VERSION ""

NS_ :

BS_:

BU_: Vector__XXX

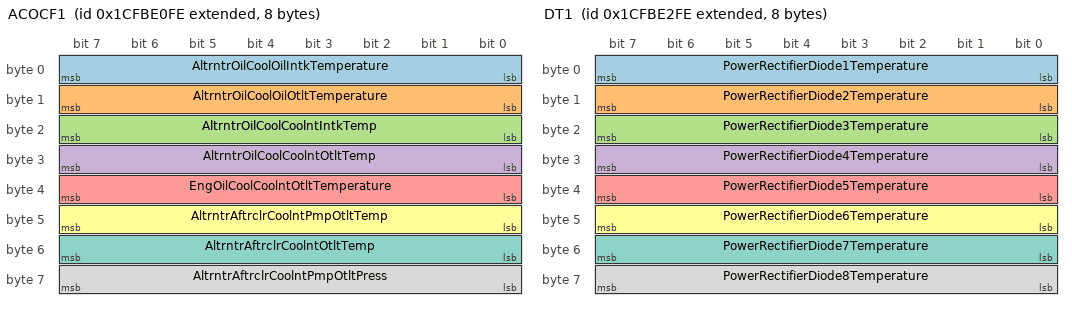
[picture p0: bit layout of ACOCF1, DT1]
BO_ 2633752830 ACOCF1: 8 Vector__XXX
SG_ AltrntrOilCoolOilIntkTemperature : 0|8@1+ (1,-40) [-40|210] "deg C" Vector__XXX
SG_ AltrntrOilCoolOilOtltTemperature : 8|8@1+ (1,-40) [-40|210] "deg C" Vector__XXX
SG_ AltrntrOilCoolCoolntIntkTemp : 16|8@1+ (1,-40) [-40|210] "deg C" Vector__XXX
SG_ AltrntrOilCoolCoolntOtltTemp : 24|8@1+ (1,-40) [-40|210] "deg C" Vector__XXX
SG_ EngOilCoolCoolntOtltTemperature : 32|8@1+ (1,-40) [-40|210] "deg C" Vector__XXX
SG_ AltrntrAftrclrCoolntPmpOtltTemp : 40|8@1+ (1,-40) [-40|210] "deg C" Vector__XXX
SG_ AltrntrAftrclrCoolntOtltTemp : 48|8@1+ (1,-40) [-40|210] "deg C" Vector__XXX
SG_ AltrntrAftrclrCoolntPmpOtltPress : 56|8@1+ (2,0) [0|500] "kPa" Vector__XXX

BO_ 2633753086 DT2: 8 Vector__XXX
SG_ PowerRectifierDiode9Temperature : 0|8@1+ (1,-40) [-40|210] "deg C" Vector__XXX
SG_ PowerRectifierDiode10Temperature : 8|8@1+ (1,-40) [-40|210] "deg C" Vector__XXX
SG_ PowerRectifierDiode11Temperature : 16|8@1+ (1,-40) [-40|210] "deg C" Vector__XXX
SG_ PowerRectifierDiode12Temperature : 24|8@1+ (1,-40) [-40|210] "deg C" Vector__XXX

BO_ 2633753342 DT1: 8 Vector__XXX
SG_ PowerRectifierDiode1Temperature : 0|8@1+ (1,-40) [-40|210] "deg C" Vector__XXX
SG_ PowerRectifierDiode2Temperature : 8|8@1+ (1,-40) [-40|210] "deg C" Vector__XXX
SG_ PowerRectifierDiode3Temperature : 16|8@1+ (1,-40) [-40|210] "deg C" Vector__XXX
SG_ PowerRectifierDiode4Temperature : 24|8@1+ (1,-40) [-40|210] "deg C" Vector__XXX
SG_ PowerRectifierDiode5Temperature : 32|8@1+ (1,-40) [-40|210] "deg C" Vector__XXX
SG_ PowerRectifierDiode6Temperature : 40|8@1+ (1,-40) [-40|210] "deg C" Vector__XXX
SG_ PowerRectifierDiode7Temperature : 48|8@1+ (1,-40) [-40|210] "deg C" Vector__XXX
SG_ PowerRectifierDiode8Temperature : 56|8@1+ (1,-40) [-40|210] "deg C" Vector__XXX

BO_ 2633753598 AT2: 8 Vector__XXX
SG_ EngineAltrntrWinding7Temperature : 0|8@1+ (1,-40) [-40|210] "deg C" Vector__XXX
SG_ EngineAltrntrWinding8Temperature : 8|8@1+ (1,-40) [-40|210] "deg C" Vector__XXX
SG_ EngineAltrntrWinding9Temperature : 16|8@1+ (1,-40) [-40|210] "deg C" Vector__XXX
SG_ EngAltrntrWinding10Temperature : 24|8@1+ (1,-40) [-40|210] "deg C" Vector__XXX
SG_ EngAltrntrWinding11Temperature : 32|8@1+ (1,-40) [-40|210] "deg C" Vector__XXX
SG_ EngAltrntrWinding12Temperature : 40|8@1+ (1,-40) [-40|210] "deg C" Vector__XXX
SG_ AltrntrAirCoolAirIntkTemperature : 48|8@1+ (1,-40) [-40|210] "deg C" Vector__XXX
SG_ AltrntrAirCoolAirOtltTemperature : 56|8@1+ (1,-40) [-40|210] "deg C" Vector__XXX

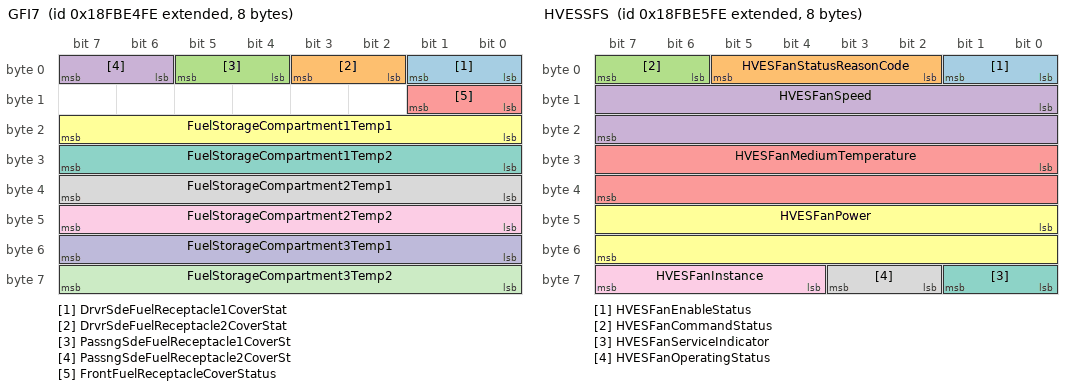
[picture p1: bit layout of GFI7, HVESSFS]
BO_ 2566644990 GFI7: 8 Vector__XXX
SG_ DrvrSdeFuelReceptacle1CoverStat : 0|2@1+ (1,0) [0|3] "" Vector__XXX
SG_ DrvrSdeFuelReceptacle2CoverStat : 2|2@1+ (1,0) [0|3] "" Vector__XXX
SG_ PassngSdeFuelReceptacle1CoverSt : 4|2@1+ (1,0) [0|3] "" Vector__XXX
SG_ PassngSdeFuelReceptacle2CoverSt : 6|2@1+ (1,0) [0|3] "" Vector__XXX
SG_ FrontFuelReceptacleCoverStatus : 8|2@1+ (1,0) [0|3] "" Vector__XXX
SG_ FuelStorageCompartment1Temp1 : 16|8@1+ (1,-40) [-40|210] "deg C" Vector__XXX
SG_ FuelStorageCompartment1Temp2 : 24|8@1+ (1,-40) [-40|210] "deg C" Vector__XXX
SG_ FuelStorageCompartment2Temp1 : 32|8@1+ (1,-40) [-40|210] "deg C" Vector__XXX
SG_ FuelStorageCompartment2Temp2 : 40|8@1+ (1,-40) [-40|210] "deg C" Vector__XXX
SG_ FuelStorageCompartment3Temp1 : 48|8@1+ (1,-40) [-40|210] "deg C" Vector__XXX
SG_ FuelStorageCompartment3Temp2 : 56|8@1+ (1,-40) [-40|210] "deg C" Vector__XXX

BO_ 2566645246 HVESSFS: 8 Vector__XXX
SG_ HVESFanEnableStatus : 0|2@1+ (1,0) [0|3] "" Vector__XXX
SG_ HVESFanStatusReasonCode : 2|4@1+ (1,0) [0|15] "" Vector__XXX
SG_ HVESFanCommandStatus : 6|2@1+ (1,0) [0|3] "" Vector__XXX
SG_ HVESFanSpeed : 8|16@1+ (0.5,0) [0|32127.5] "rpm" Vector__XXX
SG_ HVESFanMediumTemperature : 24|16@1+ (0.03125,-273) [-273|1734.96875] "deg C" Vector__XXX
SG_ HVESFanPower : 40|16@1+ (0.5,0) [0|32127.5] "W" Vector__XXX
SG_ HVESFanServiceIndicator : 56|2@1+ (1,0) [0|3] "" Vector__XXX
SG_ HVESFanOperatingStatus : 58|2@1+ (1,0) [0|3] "" Vector__XXX
SG_ HVESFanInstance : 60|4@1+ (1,0) [0|15] "" Vector__XXX

BO_ 2365318910 HVESSFC: 8 Vector__XXX
SG_ HVESFanEnableCommand : 0|2@1+ (1,0) [0|3] "" Vector__XXX
SG_ HVESFanPowerHold : 2|2@1+ (1,0) [0|3] "" Vector__XXX
SG_ HVESFanSpeedCommand : 8|16@1+ (0.5,0) [0|32127.5] "rpm" Vector__XXX
SG_ HVESFanPercentSpeedCommand : 24|8@1+ (0.4,0) [0|100] "%" Vector__XXX
SG_ HVESFanInstance1 : 32|1@1+ (1,0) [0|1] "" Vector__XXX
SG_ HVESFanInstance2 : 33|1@1+ (1,0) [0|1] "" Vector__XXX
SG_ HVESFanInstance3 : 34|1@1+ (1,0) [0|1] "" Vector__XXX
SG_ HVESFanInstance4 : 35|1@1+ (1,0) [0|1] "" Vector__XXX
SG_ HVESFanInstance5 : 36|1@1+ (1,0) [0|1] "" Vector__XXX
SG_ HVESFanInstance6 : 37|1@1+ (1,0) [0|1] "" Vector__XXX
SG_ HVESFanInstance7 : 38|1@1+ (1,0) [0|1] "" Vector__XXX
SG_ HVESFanInstance8 : 39|1@1+ (1,0) [0|1] "" Vector__XXX
SG_ HVESFanInstance9 : 40|1@1+ (1,0) [0|1] "" Vector__XXX
SG_ HVESFanInstance10 : 41|1@1+ (1,0) [0|1] "" Vector__XXX
SG_ HVESFanInstance11 : 42|1@1+ (1,0) [0|1] "" Vector__XXX
SG_ HVESFanInstance12 : 43|1@1+ (1,0) [0|1] "" Vector__XXX
SG_ HVESFanInstance13 : 44|1@1+ (1,0) [0|1] "" Vector__XXX
SG_ HVESFanInstance14 : 45|1@1+ (1,0) [0|1] "" Vector__XXX
SG_ HVESFanInstance15 : 46|1@1+ (1,0) [0|1] "" Vector__XXX

BO_ 2633754622 SCROII5: 8 Vector__XXX
SG_ Aftrtrtmnt1SCRIntkHghTempTime : 0|32@1+ (1,0) [0|4211081215] "s" Vector__XXX
SG_ SCROprtrIndcEmrgOvrrdTtlActtnTme : 32|32@1+ (1,0) [0|4211081215] "s" Vector__XXX

BO_ 2633754878 ASI2: 8 Vector__XXX
SG_ AftrtrtmntTotalDslExhstFluidUsed : 0|32@1+ (0.5,0) [0|2105540607.5] "l" Vector__XXX
SG_ AftDslExhstFldUsdThisOprtngCycle : 32|16@1+ (0.1,0) [0|6425.5] "l" Vector__XXX
SG_ DEFDosingMode : 48|8@1+ (1,0) [0|250] "" Vector__XXX
SG_ HCDoserDutyCycle : 56|8@1+ (0.4,0) [0|100] "%" Vector__XXX

BO_ 2633755134 E1NET2: 100 Vector__XXX
SG_ HostName : 7|800@0+ (1,0) [0|0] "ASCII" Vector__XXX

BO_ 2633755390 E1NET1: 19 Vector__XXX
SG_ DHCPStatus : 0|4@1+ (1,0) [0|15] "" Vector__XXX
SG_ EthernetLinkStatus : 4|2@1+ (1,0) [0|3] "" Vector__XXX
SG_ IPv4AddressOctet1 : 8|8@1+ (1,0) [0|255] "" Vector__XXX
SG_ IPv4AddressOctet2 : 16|8@1+ (1,0) [0|255] "" Vector__XXX
SG_ IPv4AddressOctet3 : 24|8@1+ (1,0) [0|255] "" Vector__XXX
SG_ IPv4AddressOctet4 : 32|8@1+ (1,0) [0|255] "" Vector__XXX
SG_ SubnetMaskOctet1 : 40|8@1+ (1,0) [0|255] "" Vector__XXX
SG_ SubnetMaskOctet2 : 48|8@1+ (1,0) [0|255] "" Vector__XXX
SG_ SubnetMaskOctet3 : 56|8@1+ (1,0) [0|255] "" Vector__XXX
SG_ SubnetMaskOctet4 : 64|8@1+ (1,0) [0|255] "" Vector__XXX
SG_ DefaultGatewayOctet1 : 72|8@1+ (1,0) [0|255] "" Vector__XXX
SG_ DefaultGatewayOctet2 : 80|8@1+ (1,0) [0|255] "" Vector__XXX
SG_ DefaultGatewayOctet3 : 88|8@1+ (1,0) [0|255] "" Vector__XXX
SG_ DefaultGatewayOctet4 : 96|8@1+ (1,0) [0|255] "" Vector__XXX
SG_ MACAddressOctet1 : 104|8@1+ (1,0) [0|255] "" Vector__XXX
SG_ MACAddressOctet2 : 112|8@1+ (1,0) [0|255] "" Vector__XXX
SG_ MACAddressOctet3 : 120|8@1+ (1,0) [0|255] "" Vector__XXX
SG_ MACAddressOctet4 : 128|8@1+ (1,0) [0|255] "" Vector__XXX
SG_ MACAddressOctet5 : 136|8@1+ (1,0) [0|255] "" Vector__XXX
SG_ MACAddressOctet6 : 144|8@1+ (1,0) [0|255] "" Vector__XXX

BO_ 2566646782 ODMCF1_2: 8 Vector__XXX
SG_ OilDebrisMontFerrsBins12IdNo : 0|8@1+ (1,0) [0|250] "" Vector__XXX
SG_ OilDebrisMonitorFerrousBin1Count : 8|24@1+ (1,0) [0|16449535] "" Vector__XXX
SG_ OilDebrisMonitorFerrousBin2Count : 32|24@1+ (1,0) [0|16449535] "" Vector__XXX

BO_ 2566647038 ODMCF3_4: 8 Vector__XXX
SG_ OilDebrisMontFerrsBins34IdNo : 0|8@1+ (1,0) [0|250] "" Vector__XXX
SG_ OilDebrisMonitorFerrousBin3Count : 8|24@1+ (1,0) [0|16449535] "" Vector__XXX
SG_ OilDebrisMonitorFerrousBin4Count : 32|24@1+ (1,0) [0|16449535] "" Vector__XXX

BO_ 2566647294 ODMCF5_6: 8 Vector__XXX
SG_ OilDebrisMontFerrsBins56IdNo : 0|8@1+ (1,0) [0|250] "" Vector__XXX
SG_ OilDebrisMonitorFerrousBin5Count : 8|24@1+ (1,0) [0|16449535] "" Vector__XXX
SG_ OilDebrisMonitorFerrousBin6Count : 32|24@1+ (1,0) [0|16449535] "" Vector__XXX

BO_ 2566647550 ODMCNF1_2: 8 Vector__XXX
SG_ OilDebrisMontNFerrsBins12IdNo : 0|8@1+ (1,0) [0|250] "" Vector__XXX
SG_ OilDebrisMonitorNonFerrsBin1Cnt : 8|24@1+ (1,0) [0|16449535] "" Vector__XXX
SG_ OilDebrisMonitorNonFerrsBin2Cnt : 32|24@1+ (1,0) [0|16449535] "" Vector__XXX

BO_ 2566647806 ODMCNF3_4: 8 Vector__XXX
SG_ OilDebrisMontNFerrsBins34IdNo : 0|8@1+ (1,0) [0|250] "" Vector__XXX
SG_ OilDebrisMonitorNonFerrsBin3Cnt : 8|24@1+ (1,0) [0|16449535] "" Vector__XXX
SG_ OilDebrisMonitorNonFerrsBin4Cnt : 32|24@1+ (1,0) [0|16449535] "" Vector__XXX

BO_ 2566648062 ODMCNF5_6: 8 Vector__XXX
SG_ OilDebrisMontNFerrsBins56IdNo : 0|8@1+ (1,0) [0|250] "" Vector__XXX
SG_ OilDebrisMonitorNonFerrsBin5Cnt : 8|24@1+ (1,0) [0|16449535] "" Vector__XXX
SG_ OilDebrisMonitorNonFerrsBin6Cnt : 32|24@1+ (1,0) [0|16449535] "" Vector__XXX

BO_ 2566648318 ODMSS: 8 Vector__XXX
SG_ OilDebrisMontStatusIdntfctionNo : 0|8@1+ (1,0) [0|250] "" Vector__XXX
SG_ OilDebrisMontTotalNumberSensors : 8|8@1+ (1,0) [0|250] "" Vector__XXX
SG_ OilDebrisMontEnvironmentStatus : 16|2@1+ (1,0) [0|3] "" Vector__XXX
SG_ OilDebrisMontSensingElementStat : 18|2@1+ (1,0) [0|3] "" Vector__XXX
SG_ OilDebrisMontSigPrcngElctrncsSt : 20|2@1+ (1,0) [0|3] "" Vector__XXX
SG_ OilDebrisMontElctrncsTempStat : 22|2@1+ (1,0) [0|3] "" Vector__XXX

BO_ 2365322238 CCVS5: 8 Vector__XXX
SG_ DirectionalVehicleSpeed : 0|16@1+ (0.0078125,-250) [-250|251.992] "km/h" Vector__XXX

BO_ 2566649086 A2DOC2: 8 Vector__XXX
SG_ Aft2DslOxidtnCtlystIntkPress : 0|16@1+ (0.1,0) [0|6425.5] "kPa" Vector__XXX
SG_ Aft2DslOxidtnCtlystOtltPress : 16|16@1+ (0.1,0) [0|6425.5] "kPa" Vector__XXX
SG_ Aft2DOCInletToDPFOtltDeltaPress : 32|16@1+ (0.1,0) [0|6425.5] "kPa" Vector__XXX

BO_ 2566649342 A1DOC2: 8 Vector__XXX
SG_ Aft1DslOxidtnCtlystIntkPress : 0|16@1+ (0.1,0) [0|6425.5] "kPa" Vector__XXX
SG_ Aft1DslOxidtnCtlystOtltPress : 16|16@1+ (0.1,0) [0|6425.5] "kPa" Vector__XXX
SG_ Aft1DOCInletToDPFOtltDeltaPress : 32|16@1+ (0.1,0) [0|6425.5] "kPa" Vector__XXX

BO_ 2566649598 VP2: 8 Vector__XXX
SG_ TotalNumberOfSatellitesInView : 0|8@1+ (1,0) [0|250] "" Vector__XXX
SG_ HorizontalDilutionOfPrecision : 8|8@1+ (0.1,0) [0|25] "" Vector__XXX
SG_ VerticalDilutionOfPrecision : 16|8@1+ (0.1,0) [0|25] "" Vector__XXX
SG_ PositionDilutionOfPrecision : 24|8@1+ (0.1,0) [0|25] "" Vector__XXX
SG_ TimeDilutionOfPrecision : 32|8@1+ (0.1,0) [0|25] "" Vector__XXX

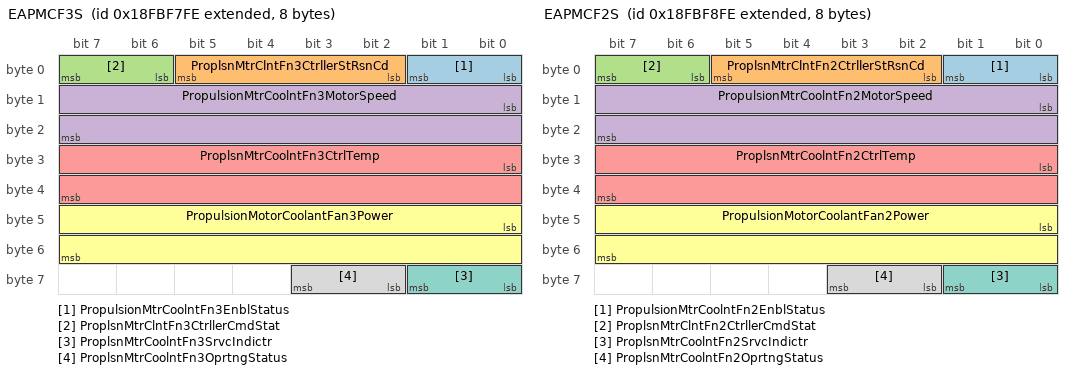
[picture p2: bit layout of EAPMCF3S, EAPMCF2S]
BO_ 2566649854 EAPMCF3S: 8 Vector__XXX
SG_ PropulsionMtrCoolntFn3EnblStatus : 0|2@1+ (1,0) [0|3] "" Vector__XXX
SG_ ProplsnMtrClntFn3CtrllerStRsnCd : 2|4@1+ (1,0) [0|15] "" Vector__XXX
SG_ ProplsnMtrClntFn3CtrllerCmdStat : 6|2@1+ (1,0) [0|3] "" Vector__XXX
SG_ PropulsionMtrCoolntFn3MotorSpeed : 8|16@1+ (0.5,0) [0|32127.5] "rpm" Vector__XXX
SG_ ProplsnMtrCoolntFn3CtrlTemp : 24|16@1+ (0.03125,-273) [-273|1734.96875] "deg C" Vector__XXX
SG_ PropulsionMotorCoolantFan3Power : 40|16@1+ (0.5,0) [0|32127.5] "W" Vector__XXX
SG_ ProplsnMtrCoolntFn3SrvcIndictr : 56|2@1+ (1,0) [0|3] "" Vector__XXX
SG_ ProplsnMtrCoolntFn3OprtngStatus : 58|2@1+ (1,0) [0|3] "" Vector__XXX

BO_ 2566650110 EAPMCF2S: 8 Vector__XXX
SG_ PropulsionMtrCoolntFn2EnblStatus : 0|2@1+ (1,0) [0|3] "" Vector__XXX
SG_ ProplsnMtrClntFn2CtrllerStRsnCd : 2|4@1+ (1,0) [0|15] "" Vector__XXX
SG_ ProplsnMtrClntFn2CtrllerCmdStat : 6|2@1+ (1,0) [0|3] "" Vector__XXX
SG_ PropulsionMtrCoolntFn2MotorSpeed : 8|16@1+ (0.5,0) [0|32127.5] "rpm" Vector__XXX
SG_ ProplsnMtrCoolntFn2CtrlTemp : 24|16@1+ (0.03125,-273) [-273|1734.96875] "deg C" Vector__XXX
SG_ PropulsionMotorCoolantFan2Power : 40|16@1+ (0.5,0) [0|32127.5] "W" Vector__XXX
SG_ ProplsnMtrCoolntFn2SrvcIndictr : 56|2@1+ (1,0) [0|3] "" Vector__XXX
SG_ ProplsnMtrCoolntFn2OprtngStatus : 58|2@1+ (1,0) [0|3] "" Vector__XXX

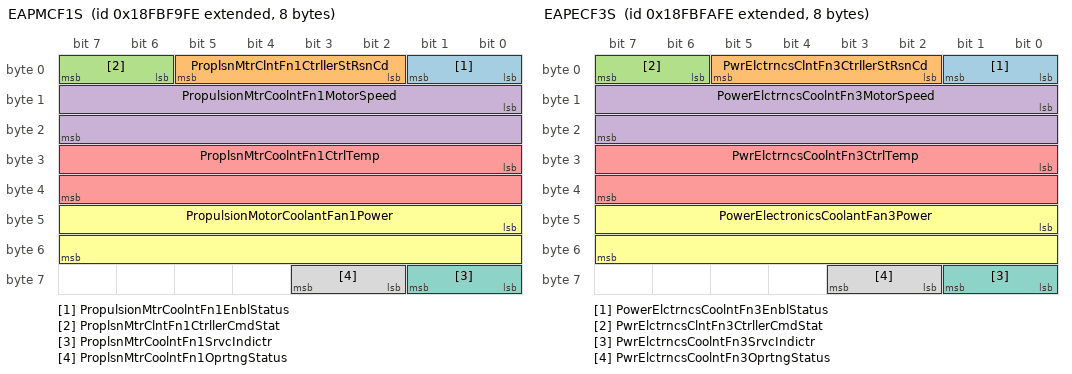
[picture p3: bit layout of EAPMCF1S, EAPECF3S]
BO_ 2566650366 EAPMCF1S: 8 Vector__XXX
SG_ PropulsionMtrCoolntFn1EnblStatus : 0|2@1+ (1,0) [0|3] "" Vector__XXX
SG_ ProplsnMtrClntFn1CtrllerStRsnCd : 2|4@1+ (1,0) [0|15] "" Vector__XXX
SG_ ProplsnMtrClntFn1CtrllerCmdStat : 6|2@1+ (1,0) [0|3] "" Vector__XXX
SG_ PropulsionMtrCoolntFn1MotorSpeed : 8|16@1+ (0.5,0) [0|32127.5] "rpm" Vector__XXX
SG_ ProplsnMtrCoolntFn1CtrlTemp : 24|16@1+ (0.03125,-273) [-273|1734.96875] "deg C" Vector__XXX
SG_ PropulsionMotorCoolantFan1Power : 40|16@1+ (0.5,0) [0|32127.5] "W" Vector__XXX
SG_ ProplsnMtrCoolntFn1SrvcIndictr : 56|2@1+ (1,0) [0|3] "" Vector__XXX
SG_ ProplsnMtrCoolntFn1OprtngStatus : 58|2@1+ (1,0) [0|3] "" Vector__XXX

BO_ 2566650622 EAPECF3S: 8 Vector__XXX
SG_ PowerElctrncsCoolntFn3EnblStatus : 0|2@1+ (1,0) [0|3] "" Vector__XXX
SG_ PwrElctrncsClntFn3CtrllerStRsnCd : 2|4@1+ (1,0) [0|15] "" Vector__XXX
SG_ PwrElctrncsClntFn3CtrllerCmdStat : 6|2@1+ (1,0) [0|3] "" Vector__XXX
SG_ PowerElctrncsCoolntFn3MotorSpeed : 8|16@1+ (0.5,0) [0|32127.5] "rpm" Vector__XXX
SG_ PwrElctrncsCoolntFn3CtrlTemp : 24|16@1+ (0.03125,-273) [-273|1734.96875] "deg C" Vector__XXX
SG_ PowerElectronicsCoolantFan3Power : 40|16@1+ (0.5,0) [0|32127.5] "W" Vector__XXX
SG_ PwrElctrncsCoolntFn3SrvcIndictr : 56|2@1+ (1,0) [0|3] "" Vector__XXX
SG_ PwrElctrncsCoolntFn3OprtngStatus : 58|2@1+ (1,0) [0|3] "" Vector__XXX

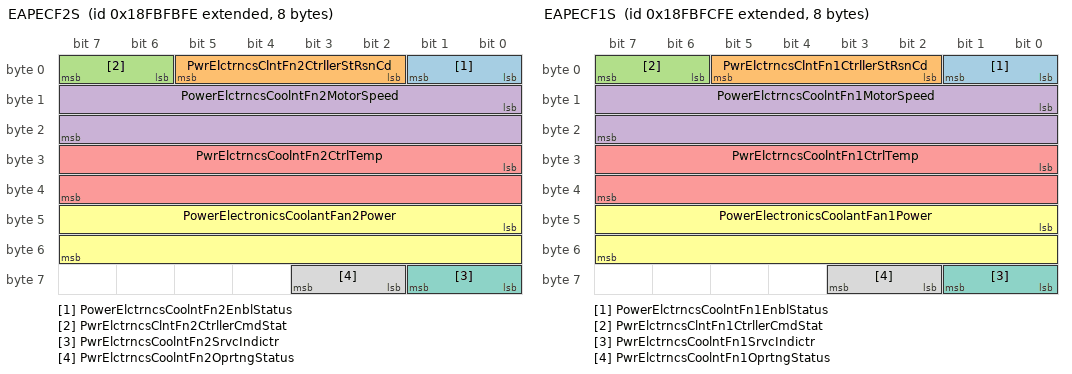
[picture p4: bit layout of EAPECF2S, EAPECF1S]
BO_ 2566650878 EAPECF2S: 8 Vector__XXX
SG_ PowerElctrncsCoolntFn2EnblStatus : 0|2@1+ (1,0) [0|3] "" Vector__XXX
SG_ PwrElctrncsClntFn2CtrllerStRsnCd : 2|4@1+ (1,0) [0|15] "" Vector__XXX
SG_ PwrElctrncsClntFn2CtrllerCmdStat : 6|2@1+ (1,0) [0|3] "" Vector__XXX
SG_ PowerElctrncsCoolntFn2MotorSpeed : 8|16@1+ (0.5,0) [0|32127.5] "rpm" Vector__XXX
SG_ PwrElctrncsCoolntFn2CtrlTemp : 24|16@1+ (0.03125,-273) [-273|1734.96875] "deg C" Vector__XXX
SG_ PowerElectronicsCoolantFan2Power : 40|16@1+ (0.5,0) [0|32127.5] "W" Vector__XXX
SG_ PwrElctrncsCoolntFn2SrvcIndictr : 56|2@1+ (1,0) [0|3] "" Vector__XXX
SG_ PwrElctrncsCoolntFn2OprtngStatus : 58|2@1+ (1,0) [0|3] "" Vector__XXX

BO_ 2566651134 EAPECF1S: 8 Vector__XXX
SG_ PowerElctrncsCoolntFn1EnblStatus : 0|2@1+ (1,0) [0|3] "" Vector__XXX
SG_ PwrElctrncsClntFn1CtrllerStRsnCd : 2|4@1+ (1,0) [0|15] "" Vector__XXX
SG_ PwrElctrncsClntFn1CtrllerCmdStat : 6|2@1+ (1,0) [0|3] "" Vector__XXX
SG_ PowerElctrncsCoolntFn1MotorSpeed : 8|16@1+ (0.5,0) [0|32127.5] "rpm" Vector__XXX
SG_ PwrElctrncsCoolntFn1CtrlTemp : 24|16@1+ (0.03125,-273) [-273|1734.96875] "deg C" Vector__XXX
SG_ PowerElectronicsCoolantFan1Power : 40|16@1+ (0.5,0) [0|32127.5] "W" Vector__XXX
SG_ PwrElctrncsCoolntFn1SrvcIndictr : 56|2@1+ (1,0) [0|3] "" Vector__XXX
SG_ PwrElctrncsCoolntFn1OprtngStatus : 58|2@1+ (1,0) [0|3] "" Vector__XXX

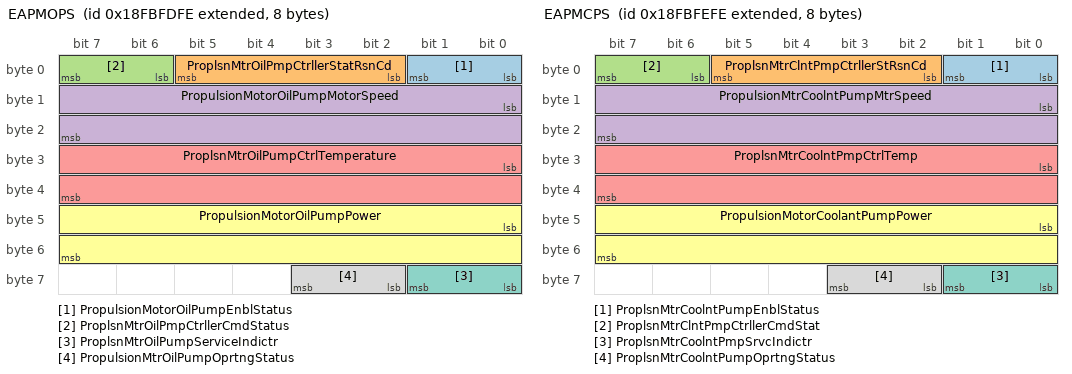
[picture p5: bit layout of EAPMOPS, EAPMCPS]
BO_ 2566651390 EAPMOPS: 8 Vector__XXX
SG_ PropulsionMotorOilPumpEnblStatus : 0|2@1+ (1,0) [0|3] "" Vector__XXX
SG_ ProplsnMtrOilPmpCtrllerStatRsnCd : 2|4@1+ (1,0) [0|15] "" Vector__XXX
SG_ ProplsnMtrOilPmpCtrllerCmdStatus : 6|2@1+ (1,0) [0|3] "" Vector__XXX
SG_ PropulsionMotorOilPumpMotorSpeed : 8|16@1+ (0.5,0) [0|32127.5] "rpm" Vector__XXX
SG_ ProplsnMtrOilPumpCtrlTemperature : 24|16@1+ (0.03125,-273) [-273|1734.96875] "deg C" Vector__XXX
SG_ PropulsionMotorOilPumpPower : 40|16@1+ (0.5,0) [0|32127.5] "W" Vector__XXX
SG_ ProplsnMtrOilPumpServiceIndictr : 56|2@1+ (1,0) [0|3] "" Vector__XXX
SG_ PropulsionMtrOilPumpOprtngStatus : 58|2@1+ (1,0) [0|3] "" Vector__XXX

BO_ 2566651646 EAPMCPS: 8 Vector__XXX
SG_ ProplsnMtrCoolntPumpEnblStatus : 0|2@1+ (1,0) [0|3] "" Vector__XXX
SG_ ProplsnMtrClntPmpCtrllerStRsnCd : 2|4@1+ (1,0) [0|15] "" Vector__XXX
SG_ ProplsnMtrClntPmpCtrllerCmdStat : 6|2@1+ (1,0) [0|3] "" Vector__XXX
SG_ PropulsionMtrCoolntPumpMtrSpeed : 8|16@1+ (0.5,0) [0|32127.5] "rpm" Vector__XXX
SG_ ProplsnMtrCoolntPmpCtrlTemp : 24|16@1+ (0.03125,-273) [-273|1734.96875] "deg C" Vector__XXX
SG_ PropulsionMotorCoolantPumpPower : 40|16@1+ (0.5,0) [0|32127.5] "W" Vector__XXX
SG_ ProplsnMtrCoolntPmpSrvcIndictr : 56|2@1+ (1,0) [0|3] "" Vector__XXX
SG_ ProplsnMtrCoolntPumpOprtngStatus : 58|2@1+ (1,0) [0|3] "" Vector__XXX

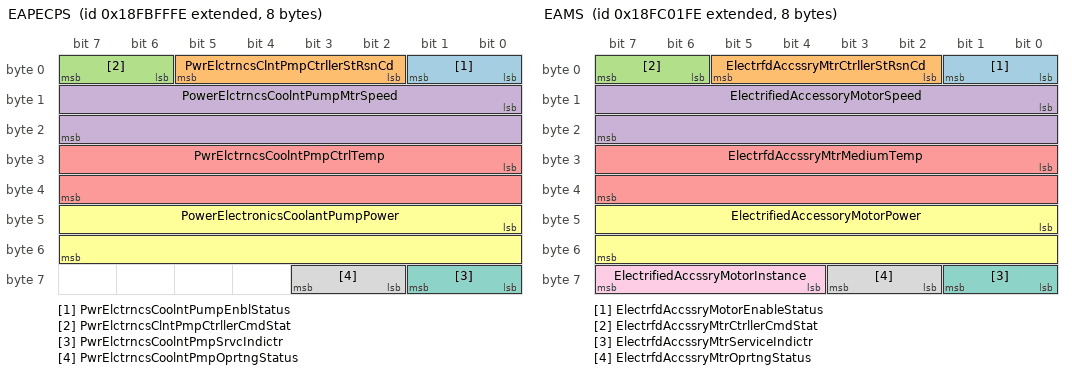
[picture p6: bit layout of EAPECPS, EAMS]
BO_ 2566651902 EAPECPS: 8 Vector__XXX
SG_ PwrElctrncsCoolntPumpEnblStatus : 0|2@1+ (1,0) [0|3] "" Vector__XXX
SG_ PwrElctrncsClntPmpCtrllerStRsnCd : 2|4@1+ (1,0) [0|15] "" Vector__XXX
SG_ PwrElctrncsClntPmpCtrllerCmdStat : 6|2@1+ (1,0) [0|3] "" Vector__XXX
SG_ PowerElctrncsCoolntPumpMtrSpeed : 8|16@1+ (0.5,0) [0|32127.5] "rpm" Vector__XXX
SG_ PwrElctrncsCoolntPmpCtrlTemp : 24|16@1+ (0.03125,-273) [-273|1734.96875] "deg C" Vector__XXX
SG_ PowerElectronicsCoolantPumpPower : 40|16@1+ (0.5,0) [0|32127.5] "W" Vector__XXX
SG_ PwrElctrncsCoolntPmpSrvcIndictr : 56|2@1+ (1,0) [0|3] "" Vector__XXX
SG_ PwrElctrncsCoolntPmpOprtngStatus : 58|2@1+ (1,0) [0|3] "" Vector__XXX

BO_ 2566652414 EAMS: 8 Vector__XXX
SG_ ElectrfdAccssryMotorEnableStatus : 0|2@1+ (1,0) [0|3] "" Vector__XXX
SG_ ElectrfdAccssryMtrCtrllerStRsnCd : 2|4@1+ (1,0) [0|15] "" Vector__XXX
SG_ ElectrfdAccssryMtrCtrllerCmdStat : 6|2@1+ (1,0) [0|3] "" Vector__XXX
SG_ ElectrifiedAccessoryMotorSpeed : 8|16@1+ (0.5,0) [0|32127.5] "rpm" Vector__XXX
SG_ ElectrfdAccssryMtrMediumTemp : 24|16@1+ (0.03125,-273) [-273|1734.96875] "deg C" Vector__XXX
SG_ ElectrifiedAccessoryMotorPower : 40|16@1+ (0.5,0) [0|32127.5] "W" Vector__XXX
SG_ ElectrfdAccssryMtrServiceIndictr : 56|2@1+ (1,0) [0|3] "" Vector__XXX
SG_ ElectrfdAccssryMtrOprtngStatus : 58|2@1+ (1,0) [0|3] "" Vector__XXX
SG_ ElectrifiedAccssryMotorInstance : 60|4@1+ (1,0) [0|15] "" Vector__XXX

BO_ 2566652670 SCRSI: 8 Vector__XXX
SG_ DieselExhaustFluidFrozenTime : 0|32@1+ (1,0) [0|4211081215] "s" Vector__XXX
SG_ Aftrtrtmnt1SCRSystemHydrocarbon : 32|8@1+ (1,0) [0|250] "%" Vector__XXX
SG_ Aft1DslExhstFldDsngSysFrozen : 40|2@1+ (1,0) [0|3] "" Vector__XXX
SG_ Aft2DslExhstFldDsngSysFrozen : 42|2@1+ (1,0) [0|3] "" Vector__XXX
SG_ Afttreatment2SCRSysHydrocarbon : 48|8@1+ (1,0) [0|250] "%" Vector__XXX

BO_ 2566652926 VEP14: 8 Vector__XXX
SG_ SLIBattryPack1Battry4StateCharge : 0|16@1+ (0.0025,0) [0|160.6375] "%" Vector__XXX
SG_ SLIBatteryPack1Battery4Capacity : 16|16@1+ (1,0) [0|64255] "Ah" Vector__XXX
SG_ SLIBatteryPack1Battery4Health : 32|8@1+ (0.5,0) [0|125] "%" Vector__XXX
SG_ SLIBattPack1Batt4PrdctMnCrnkVltg : 40|8@1+ (0.2,0) [0|50] "V" Vector__XXX
SG_ SLIBattryPack1Sensor4InitStatus : 48|4@1+ (1,0) [0|15] "" Vector__XXX

BO_ 2566653182 VEP13: 8 Vector__XXX
SG_ SLIBattryPack1Battery4NetCurrent : 0|16@1+ (0.05,-1600) [-1600|1612.75] "A" Vector__XXX
SG_ SLIBattryPack1Battry4Temperature : 16|8@1+ (1,-40) [-40|210] "deg C" Vector__XXX
SG_ SLIBatteryPack1Battery4Voltage : 24|16@1+ (0.05,0) [0|3212.75] "V" Vector__XXX

BO_ 2566653438 VEP12: 8 Vector__XXX
SG_ SLIBattryPack1Battry3StateCharge : 0|16@1+ (0.0025,0) [0|160.6375] "%" Vector__XXX
SG_ SLIBatteryPack1Battery3Capacity : 16|16@1+ (1,0) [0|64255] "Ah" Vector__XXX
SG_ SLIBatteryPack1Battery3Health : 32|8@1+ (0.5,0) [0|125] "%" Vector__XXX
SG_ SLIBattPack1Batt3PrdctMnCrnkVltg : 40|8@1+ (0.2,0) [0|50] "V" Vector__XXX
SG_ SLIBattryPack1Sensor3InitStatus : 48|4@1+ (1,0) [0|15] "" Vector__XXX

BO_ 2566653694 VEP11: 8 Vector__XXX
SG_ SLIBattryPack1Battery3NetCurrent : 0|16@1+ (0.05,-1600) [-1600|1612.75] "A" Vector__XXX
SG_ SLIBattryPack1Battry3Temperature : 16|8@1+ (1,-40) [-40|210] "deg C" Vector__XXX
SG_ SLIBatteryPack1Battery3Voltage : 24|16@1+ (0.05,0) [0|3212.75] "V" Vector__XXX

BO_ 2566653950 VEP10: 8 Vector__XXX
SG_ SLIBattryPack1Battry2StateCharge : 0|16@1+ (0.0025,0) [0|160.6375] "%" Vector__XXX
SG_ SLIBatteryPack1Battery2Capacity : 16|16@1+ (1,0) [0|64255] "Ah" Vector__XXX
SG_ SLIBatteryPack1Battery2Health : 32|8@1+ (0.5,0) [0|125] "%" Vector__XXX
SG_ SLIBattPack1Batt2PrdctMnCrnkVltg : 40|8@1+ (0.2,0) [0|50] "V" Vector__XXX
SG_ SLIBattryPack1Sensor2InitStatus : 48|4@1+ (1,0) [0|15] "" Vector__XXX

BO_ 2566654206 VEP9: 8 Vector__XXX
SG_ SLIBattryPack1Battery2NetCurrent : 0|16@1+ (0.05,-1600) [-1600|1612.75] "A" Vector__XXX
SG_ SLIBattryPack1Battry2Temperature : 16|8@1+ (1,-40) [-40|210] "deg C" Vector__XXX
SG_ SLIBatteryPack1Battery2Voltage : 24|16@1+ (0.05,0) [0|3212.75] "V" Vector__XXX

BO_ 2566654462 VEP8: 8 Vector__XXX
SG_ SLIBattryPack1Battry1StateCharge : 0|16@1+ (0.0025,0) [0|160.6375] "%" Vector__XXX
SG_ SLIBatteryPack1Battery1Capacity : 16|16@1+ (1,0) [0|64255] "Ah" Vector__XXX
SG_ SLIBatteryPack1Battery1Health : 32|8@1+ (0.5,0) [0|125] "%" Vector__XXX
SG_ SLIBattPack1Batt1PrdctMnCrnkVltg : 40|8@1+ (0.2,0) [0|50] "V" Vector__XXX
SG_ SLIBattryPack1Sensor1InitStatus : 48|4@1+ (1,0) [0|15] "" Vector__XXX

BO_ 2566654718 VEP7: 8 Vector__XXX
SG_ SLIBattryPack1Battery1NetCurrent : 0|16@1+ (0.05,-1600) [-1600|1612.75] "A" Vector__XXX
SG_ SLIBattryPack1Battry1Temperature : 16|8@1+ (1,-40) [-40|210] "deg C" Vector__XXX
SG_ SLIBatteryPack1Battery1Voltage : 24|16@1+ (0.05,0) [0|3212.75] "V" Vector__XXX

BO_ 2566654974 EEC20: 8 Vector__XXX
SG_ EstEngParasiticLossesPrcntTorque : 0|16@1+ (0.0015625,0) [0|100.3984375] "%" Vector__XXX
SG_ ActlMaximumAvailEngPercentFuel : 16|8@1+ (0.4,0) [0|100] "%" Vector__XXX

BO_ 2633764094 EVAP: 8 Vector__XXX
SG_ CanisterVentValve : 0|2@1+ (1,0) [0|3] "" Vector__XXX
SG_ CanisterPurgeValveCommand : 8|8@1+ (0.4,0) [0|100] "%" Vector__XXX
SG_ GasolineFuelTankPressure : 16|16@1+ (0.1,-3212.7) [-3212.7|3212.8] "kPa" Vector__XXX

BO_ 2633764350 FPS1: 8 Vector__XXX
SG_ FirePumpOperationTime : 0|32@1+ (1,0) [0|4211081215] "s" Vector__XXX
SG_ FirePumpEngagementCycles : 32|16@1+ (1,0) [0|64255] "" Vector__XXX

BO_ 2566655742 PHRPS: 8 Vector__XXX
SG_ RearHitchRollSensitivity : 0|8@1+ (0.4,0) [0|100] "%" Vector__XXX
SG_ RearHitchPitchSensitivity : 8|8@1+ (0.4,0) [0|100] "%" Vector__XXX

BO_ 2566655998 SHRPS: 8 Vector__XXX
SG_ FrontHitchRollSensitivity : 0|8@1+ (0.4,0) [0|100] "%" Vector__XXX
SG_ FrontHitchPitchSensitivity : 8|8@1+ (0.4,0) [0|100] "%" Vector__XXX

BO_ 2566656254 AMB3: 8 Vector__XXX
SG_ BarometricAbsolutePressure2 : 0|16@1+ (0.1,0) [0|6425.5] "kPa" Vector__XXX
SG_ EngineIntake2AirTemperature : 16|8@1+ (1,-40) [-40|210] "deg C" Vector__XXX
SG_ EngPwrDerateRelHumidityDiffrnc : 24|16@1+ (0.01,-321.27) [-321.27|321.28] "%" Vector__XXX

BO_ 2566656510 TGFI: 8 Vector__XXX
SG_ EngineTotalGaseousFuelVolumeUsed : 0|32@1+ (0.5,0) [0|2105540607.5] "m^3" Vector__XXX
SG_ EngTotalGasIdleFuelVolumeUsed : 32|32@1+ (0.5,0) [0|2105540607.5] "m^3" Vector__XXX

BO_ 2499547902 CDC: 8 Vector__XXX
SG_ CabDoorsLockActuationCommand : 0|3@1+ (1,0) [0|7] "" Vector__XXX
SG_ RemoteCabDoorLockRequest : 8|3@1+ (1,0) [0|7] "" Vector__XXX
SG_ LeftFrontWindowPositionCommand : 16|3@1+ (1,0) [0|7] "" Vector__XXX
SG_ RightFrontWindowPositionCommand : 19|3@1+ (1,0) [0|7] "" Vector__XXX
SG_ MirrorFoldingSwitch : 22|2@1+ (1,0) [0|3] "" Vector__XXX
SG_ LeftRearWindowPositionCommand : 24|3@1+ (1,0) [0|7] "" Vector__XXX
SG_ RightRearWindowPositionCommand : 27|3@1+ (1,0) [0|7] "" Vector__XXX
SG_ MirrorAutoPanningEnable : 30|2@1+ (1,0) [0|3] "" Vector__XXX
SG_ MirrorLeft1HorizontalCommand : 32|2@1+ (1,0) [0|3] "" Vector__XXX
SG_ MirrorLeft1VerticalCommand : 34|2@1+ (1,0) [0|3] "" Vector__XXX
SG_ MirrorRight1HorizontalCommand : 36|2@1+ (1,0) [0|3] "" Vector__XXX
SG_ MirrorRight1VerticalCommand : 38|2@1+ (1,0) [0|3] "" Vector__XXX
SG_ MirrorLeft2HorizontalCommand : 40|2@1+ (1,0) [0|3] "" Vector__XXX
SG_ MirrorLeft2VerticalCommand : 42|2@1+ (1,0) [0|3] "" Vector__XXX
SG_ MirrorRight2HorizontalCommand : 44|2@1+ (1,0) [0|3] "" Vector__XXX
SG_ MirrorRight2VerticalCommand : 46|2@1+ (1,0) [0|3] "" Vector__XXX
SG_ MirrorLeft1HeatCommand : 48|2@1+ (1,0) [0|3] "" Vector__XXX
SG_ MirrorRight1HeatCommand : 50|2@1+ (1,0) [0|3] "" Vector__XXX
SG_ MirrorLeft2HeatCommand : 52|2@1+ (1,0) [0|3] "" Vector__XXX
SG_ MirrorRight2HeatCommand : 54|2@1+ (1,0) [0|3] "" Vector__XXX

BO_ 2499548158 DLS: 8 Vector__XXX
SG_ LeftFrontCabDoorLatchPosition : 0|3@1+ (1,0) [0|7] "" Vector__XXX
SG_ RightFrontCabDoorLatchPosition : 8|3@1+ (1,0) [0|7] "" Vector__XXX
SG_ LeftRearCabDoorLatchPosition : 16|3@1+ (1,0) [0|7] "" Vector__XXX
SG_ RightRearCabDoorLatchPosition : 24|3@1+ (1,0) [0|7] "" Vector__XXX

BO_ 2499548670 VEP6: 8 Vector__XXX
SG_ BatteryPotentialPowerInput3 : 0|16@1+ (0.05,0) [0|3212.75] "V" Vector__XXX
SG_ BatteryPotentialPowerInput4 : 16|16@1+ (0.05,0) [0|3212.75] "V" Vector__XXX
SG_ SLIBattery3NetCurrent : 32|16@1+ (0.05,-1600) [-1600|1612.75] "A" Vector__XXX
SG_ SLIBattery4NetCurrent : 48|16@1+ (0.05,-1600) [-1600|1612.75] "A" Vector__XXX

BO_ 2499548926 PLT2: 8 Vector__XXX
SG_ PayloadTemperature5 : 0|16@1+ (0.03125,-273) [-273|1734.96875] "deg C" Vector__XXX

BO_ 2499549182 PLT1: 8 Vector__XXX
SG_ PayloadTemperature1 : 0|16@1+ (0.03125,-273) [-273|1734.96875] "deg C" Vector__XXX
SG_ PayloadTemperature2 : 16|16@1+ (0.03125,-273) [-273|1734.96875] "deg C" Vector__XXX
SG_ PayloadTemperature3 : 32|16@1+ (0.03125,-273) [-273|1734.96875] "deg C" Vector__XXX
SG_ PayloadTemperature4 : 48|16@1+ (0.03125,-273) [-273|1734.96875] "deg C" Vector__XXX

BO_ 2566658302 PLST2: 8 Vector__XXX
SG_ TotalPayloadTransactionCount : 0|32@1+ (1,0) [0|4211081215] "" Vector__XXX

BO_ 2566658558 PLST1: 8 Vector__XXX
SG_ TotalDeliveredPayloadWeight : 0|32@1+ (100,0) [0|421108121500] "kg" Vector__XXX
SG_ TotalHaulCycleCount : 32|32@1+ (1,0) [0|4211081215] "" Vector__XXX

BO_ 2633769726 EEC19: 8 Vector__XXX
SG_ TotalEngineEnergy : 0|32@1+ (1,0) [0|4211081215] "kWh" Vector__XXX
SG_ EngineExhaustFlowRate : 32|32@1+ (0.001,0) [0|4211081.215] "kg/h" Vector__XXX

BO_ 2566661118 LFC2: 8 Vector__XXX
SG_ EngineTotalDieselFuelDemand : 0|32@1+ (0.5,0) [0|2105540607.5] "l" Vector__XXX

BO_ 2566661374 AT2T1I2: 8 Vector__XXX
SG_ Aftrtrtmnt2DslExhstFldTnkVolume2 : 0|8@1+ (0.4,0) [0|100] "%" Vector__XXX
SG_ Aftrtrtmnt2DslExhstFldTnkTemp2 : 8|8@1+ (1,-40) [-40|210] "deg C" Vector__XXX
SG_ Aftrtrtmnt2DslExhstFldTankHtr2 : 16|8@1+ (0.4,0) [0|100] "%" Vector__XXX

BO_ 2566661630 AT1T1I2: 8 Vector__XXX
SG_ Aftrtrtmnt1DslExhstFldTnkVolume2 : 0|8@1+ (0.4,0) [0|100] "%" Vector__XXX
SG_ Aftrtrtmnt1DslExhstFldTnkTemp2 : 8|8@1+ (1,-40) [-40|210] "deg C" Vector__XXX
SG_ Aftrtrtmnt1DslExhstFldTankHtr2 : 16|8@1+ (0.4,0) [0|100] "%" Vector__XXX

BO_ 2566661886 A2DEFI2: 8 Vector__XXX
SG_ Aft2DslExhstFldCtrllerTemp : 0|8@1+ (1,-40) [-40|210] "deg C" Vector__XXX
SG_ Aft2DslExhstFldCtrller2Temp : 8|8@1+ (1,-40) [-40|210] "deg C" Vector__XXX

BO_ 2566662142 A1DEFI2: 8 Vector__XXX
SG_ Aft1DslExhstFldCtrller1Temp : 0|8@1+ (1,-40) [-40|210] "deg C" Vector__XXX
SG_ Aft1DslExhstFldCtrller2Temp : 8|8@1+ (1,-40) [-40|210] "deg C" Vector__XXX

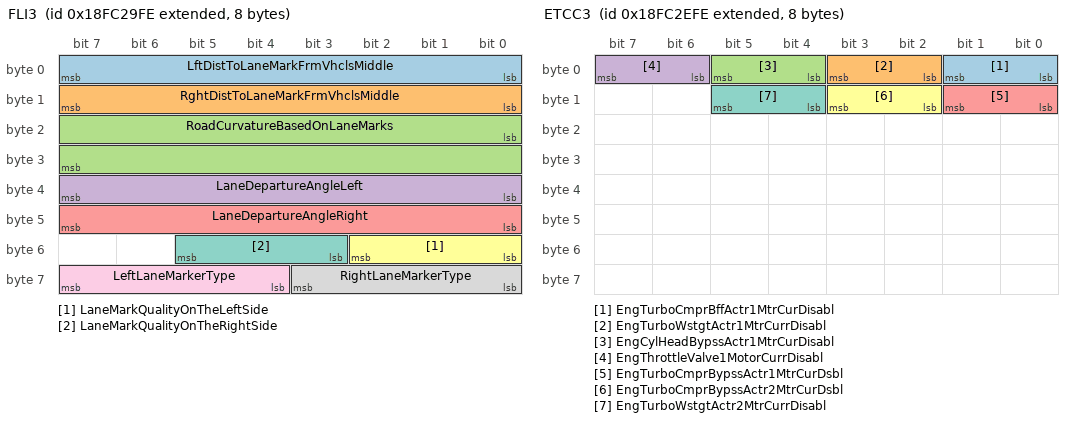
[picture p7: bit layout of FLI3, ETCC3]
BO_ 2566662654 FLI3: 8 Vector__XXX
SG_ LftDistToLaneMarkFrmVhclsMiddle : 0|8@1+ (0.02,0) [0|5] "m" Vector__XXX
SG_ RghtDistToLaneMarkFrmVhclsMiddle : 8|8@1+ (0.02,0) [0|5] "m" Vector__XXX
SG_ RoadCurvatureBasedOnLaneMarks : 16|16@1+ (0.0078125,-250) [-250|251.992] "1/km" Vector__XXX
SG_ LaneDepartureAngleLeft : 32|8@1+ (0.1,-12.5) [-12.5|12.5] "deg" Vector__XXX
SG_ LaneDepartureAngleRight : 40|8@1+ (0.1,-12.5) [-12.5|12.5] "deg" Vector__XXX
SG_ LaneMarkQualityOnTheLeftSide : 48|3@1+ (1,0) [0|7] "" Vector__XXX
SG_ LaneMarkQualityOnTheRightSide : 51|3@1+ (1,0) [0|7] "" Vector__XXX
SG_ RightLaneMarkerType : 56|4@1+ (1,0) [0|15] "" Vector__XXX
SG_ LeftLaneMarkerType : 60|4@1+ (1,0) [0|15] "" Vector__XXX

BO_ 2566662910 OII: 8 Vector__XXX
SG_ OperatorIndcmntTorqueDerateLvl1 : 0|8@1+ (1,0) [0|250] "%" Vector__XXX
SG_ OprtrIndcmntTmeToTrqDerateLvl1 : 8|16@1+ (1,0) [0|64255] "min" Vector__XXX
SG_ OperatorIndcmntTorqueDerateLvl2 : 24|8@1+ (1,0) [0|250] "%" Vector__XXX
SG_ OprtrIndcmntTmeToTrqDerateLvl2 : 32|16@1+ (1,0) [0|64255] "min" Vector__XXX
SG_ OprtrIndcmntTmeToFinalIndcmntAct : 48|16@1+ (1,0) [0|64255] "min" Vector__XXX

BO_ 2566663166 CCVS4: 8 Vector__XXX
SG_ AppliedVehicleSpeedLimit : 0|16@1+ (0.00390625,0) [0|250.996] "km/h" Vector__XXX
SG_ CruiseCtrlAdjustedMaximumSpeed : 16|16@1+ (0.00390625,0) [0|250.996] "km/h" Vector__XXX
SG_ EngExternalIdleRequestFeedback : 32|2@1+ (1,0) [0|3] "" Vector__XXX
SG_ SrcAddrCtrllingDevSttngCrsCtrl : 40|8@1+ (1,0) [0|255] "" Vector__XXX

BO_ 2566663422 BCLC: 8 Vector__XXX
SG_ TractorBrkCaliperLnngClrAxl1Lft : 0|2@1+ (1,0) [0|3] "" Vector__XXX
SG_ TractorBrkCaliperLnngClrAxl1Rght : 2|2@1+ (1,0) [0|3] "" Vector__XXX
SG_ TractorBrkCaliperLnngClrAxl2Lft : 4|2@1+ (1,0) [0|3] "" Vector__XXX
SG_ TractorBrkCaliperLnngClrAxl2Rght : 6|2@1+ (1,0) [0|3] "" Vector__XXX
SG_ TractorBrkCaliperLnngClrAxl3Lft : 8|2@1+ (1,0) [0|3] "" Vector__XXX
SG_ TractorBrkCaliperLnngClrAxl3Rght : 10|2@1+ (1,0) [0|3] "" Vector__XXX
SG_ TractorBrkCaliperLnngClrAxl4Lft : 12|2@1+ (1,0) [0|3] "" Vector__XXX
SG_ TractorBrkCaliperLnngClrAxl4Rght : 14|2@1+ (1,0) [0|3] "" Vector__XXX
SG_ TractorBrkCaliperLnngClrAxl5Lft : 16|2@1+ (1,0) [0|3] "" Vector__XXX
SG_ TractorBrkCaliperLnngClrAxl5Rght : 18|2@1+ (1,0) [0|3] "" Vector__XXX
SG_ TrlrBrkCaliperLnngClearAxl1Lft : 20|2@1+ (1,0) [0|3] "" Vector__XXX
SG_ TrlrBrkCaliperLnngClearAxl1Rght : 22|2@1+ (1,0) [0|3] "" Vector__XXX
SG_ TrlrBrkCaliperLnngClearAxl2Lft : 24|2@1+ (1,0) [0|3] "" Vector__XXX
SG_ TrlrBrkCaliperLnngClearAxl2Rght : 26|2@1+ (1,0) [0|3] "" Vector__XXX
SG_ TrlrBrkCaliperLnngClearAxl3Lft : 28|2@1+ (1,0) [0|3] "" Vector__XXX
SG_ TrlrBrkCaliperLnngClearAxl3Rght : 30|2@1+ (1,0) [0|3] "" Vector__XXX
SG_ TrlrBrkCaliperLnngClearAxl4Lft : 32|2@1+ (1,0) [0|3] "" Vector__XXX
SG_ TrlrBrkCaliperLnngClearAxl4Rght : 34|2@1+ (1,0) [0|3] "" Vector__XXX
SG_ TrlrBrkCaliperLnngClearAxl5Lft : 36|2@1+ (1,0) [0|3] "" Vector__XXX
SG_ TrlrBrkCaliperLnngClearAxl5Rght : 38|2@1+ (1,0) [0|3] "" Vector__XXX

BO_ 2566663678 AF5: 8 Vector__XXX
SG_ LNGTank1VaporPressure : 0|16@1+ (0.1,0) [0|6425.5] "kPa" Vector__XXX
SG_ LNGTank2VaporPressure : 16|16@1+ (0.1,0) [0|6425.5] "kPa" Vector__XXX
SG_ EngFuel2InjectrMeterngRail1Temp2 : 32|8@1+ (1,-40) [-40|210] "deg C" Vector__XXX

BO_ 2566663934 ETCC3: 8 Vector__XXX
SG_ EngTurboCmprBffActr1MtrCurDisabl : 0|2@1+ (1,0) [0|3] "" Vector__XXX
SG_ EngTurboWstgtActr1MtrCurrDisabl : 2|2@1+ (1,0) [0|3] "" Vector__XXX
SG_ EngCylHeadBypssActr1MtrCurDisabl : 4|2@1+ (1,0) [0|3] "" Vector__XXX
SG_ EngThrottleValve1MotorCurrDisabl : 6|2@1+ (1,0) [0|3] "" Vector__XXX
SG_ EngTurboCmprBypssActr1MtrCurDsbl : 8|2@1+ (1,0) [0|3] "" Vector__XXX
SG_ EngTurboCmprBypssActr2MtrCurDsbl : 10|2@1+ (1,0) [0|3] "" Vector__XXX
SG_ EngTurboWstgtActr2MtrCurrDisabl : 12|2@1+ (1,0) [0|3] "" Vector__XXX

BO_ 2633773054 FSAS: 8 Vector__XXX
SG_ FireSuppressionWaterTankLevel : 0|8@1+ (0.4,0) [0|100] "%" Vector__XXX
SG_ FireSuppressionClassAFoamTankLvl : 8|8@1+ (0.4,0) [0|100] "%" Vector__XXX
SG_ FireSuppressionClassBFoamTankLvl : 16|8@1+ (0.4,0) [0|100] "%" Vector__XXX
SG_ FireSupprssnCmpdAirFoamSysAirPrs : 24|8@1+ (8,0) [0|2000] "kPa" Vector__XXX

BO_ 2633773310 SCROII4: 8 Vector__XXX
SG_ SCROprtrIndcEmrgOvrrdTtlRstOccur : 0|16@1+ (1,0) [0|64255] "" Vector__XXX
SG_ SCROperatorIndcmntOverrideMode : 16|3@1+ (1,0) [0|7] "" Vector__XXX
SG_ SCROprtrIndcOvrrdRenewalRequired : 19|2@1+ (1,0) [0|3] "" Vector__XXX
SG_ SCROprtrIndcmntOverrdTimeRemain : 24|16@1+ (1,0) [0|64255] "min" Vector__XXX

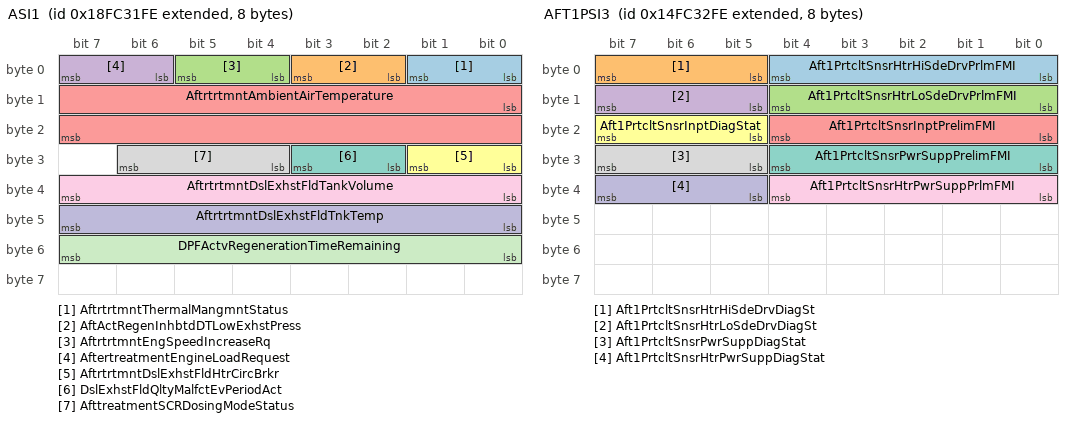
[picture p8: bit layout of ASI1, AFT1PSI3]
BO_ 2566664702 ASI1: 8 Vector__XXX
SG_ AftrtrtmntThermalMangmntStatus : 0|2@1+ (1,0) [0|3] "" Vector__XXX
SG_ AftActRegenInhbtdDTLowExhstPress : 2|2@1+ (1,0) [0|3] "" Vector__XXX
SG_ AftrtrtmntEngSpeedIncreaseRq : 4|2@1+ (1,0) [0|3] "" Vector__XXX
SG_ AftertreatmentEngineLoadRequest : 6|2@1+ (1,0) [0|3] "" Vector__XXX
SG_ AftrtrtmntAmbientAirTemperature : 8|16@1+ (0.03125,-273) [-273|1734.96875] "deg C" Vector__XXX
SG_ AftrtrtmntDslExhstFldHtrCircBrkr : 24|2@1+ (1,0) [0|3] "" Vector__XXX
SG_ DslExhstFldQltyMalfctEvPeriodAct : 26|2@1+ (1,0) [0|3] "" Vector__XXX
SG_ AfttreatmentSCRDosingModeStatus : 28|3@1+ (1,0) [0|7] "" Vector__XXX
SG_ AftrtrtmntDslExhstFldTankVolume : 32|8@1+ (0.4,0) [0|100] "%" Vector__XXX
SG_ AftrtrtmntDslExhstFldTnkTemp : 40|8@1+ (1,-40) [-40|210] "deg C" Vector__XXX
SG_ DPFActvRegenerationTimeRemaining : 48|8@1+ (1,0) [0|250] "min" Vector__XXX

BO_ 2499556094 AFT1PSI3: 8 Vector__XXX
SG_ Aft1PrtcltSnsrHtrHiSdeDrvPrlmFMI : 0|5@1+ (1,0) [0|31] "" Vector__XXX
SG_ Aft1PrtcltSnsrHtrHiSdeDrvDiagSt : 5|3@1+ (1,0) [0|7] "" Vector__XXX
SG_ Aft1PrtcltSnsrHtrLoSdeDrvPrlmFMI : 8|5@1+ (1,0) [0|31] "" Vector__XXX
SG_ Aft1PrtcltSnsrHtrLoSdeDrvDiagSt : 13|3@1+ (1,0) [0|7] "" Vector__XXX
SG_ Aft1PrtcltSnsrInptPrelimFMI : 16|5@1+ (1,0) [0|31] "" Vector__XXX
SG_ Aft1PrtcltSnsrInptDiagStat : 21|3@1+ (1,0) [0|7] "" Vector__XXX
SG_ Aft1PrtcltSnsrPwrSuppPrelimFMI : 24|5@1+ (1,0) [0|31] "" Vector__XXX
SG_ Aft1PrtcltSnsrPwrSuppDiagStat : 29|3@1+ (1,0) [0|7] "" Vector__XXX
SG_ Aft1PrtcltSnsrHtrPwrSuppPrlmFMI : 32|5@1+ (1,0) [0|31] "" Vector__XXX
SG_ Aft1PrtcltSnsrHtrPwrSuppDiagStat : 37|3@1+ (1,0) [0|7] "" Vector__XXX

BO_ 2499556350 EFIMRPI3: 8 Vector__XXX
SG_ EngFuel1InjectrMtrngRail1DsrdPrs : 0|16@1+ (5,0) [0|321275] "kPa" Vector__XXX
SG_ EngFuel1InjectrMtrngRail2DsrdPrs : 16|16@1+ (5,0) [0|321275] "kPa" Vector__XXX

BO_ 2499556606 EFIMRPI2: 8 Vector__XXX
SG_ EngFuel1InjectrMtrngRail1Press1 : 0|16@1+ (5,0) [0|321275] "kPa" Vector__XXX
SG_ EngFuel1InjectrMtrngRail1Press2 : 16|16@1+ (5,0) [0|321275] "kPa" Vector__XXX
SG_ EngFuel1InjectrMtrngRail2Press1 : 32|16@1+ (5,0) [0|321275] "kPa" Vector__XXX
SG_ EngFuel1InjectrMtrngRail2Press2 : 48|16@1+ (5,0) [0|321275] "kPa" Vector__XXX

BO_ 2566665726 AT2P1I: 8 Vector__XXX
SG_ Aftrtrtmnt2DslExhstFldPumpHeater : 0|8@1+ (0.4,0) [0|100] "%" Vector__XXX
SG_ Aftrtrtmnt2DslExhstFldPmp2MtrSpd : 8|16@1+ (0.5,0) [0|32127.5] "rpm" Vector__XXX

BO_ 2499557118 GFSVI: 8 Vector__XXX
SG_ EngGsFuelSupplyShutoffValve1Pos : 0|8@1+ (0.4,0) [0|100] "%" Vector__XXX
SG_ EngGsFuelSupplyShutoffValve2Pos : 8|8@1+ (0.4,0) [0|100] "%" Vector__XXX
SG_ EngGsFuelSupplyBleedValve1Pos : 16|8@1+ (0.4,0) [0|100] "%" Vector__XXX
SG_ EngGsFuelSupplyBleedValve2Pos : 24|8@1+ (0.4,0) [0|100] "%" Vector__XXX
SG_ EngGsFuelSupplyBleedValve3Pos : 32|8@1+ (0.4,0) [0|100] "%" Vector__XXX
SG_ InertGasSupplyValvePosition : 40|8@1+ (0.4,0) [0|100] "%" Vector__XXX

BO_ 2499557374 EOMDI2: 8 Vector__XXX
SG_ EngineOilMist9Concentration : 0|8@1+ (1,0) [0|250] "%" Vector__XXX
SG_ EngineOilMist10Concentration : 8|8@1+ (1,0) [0|250] "%" Vector__XXX

BO_ 2499557630 EOMDI1: 8 Vector__XXX
SG_ EngineOilMist1Concentration : 0|8@1+ (1,0) [0|250] "%" Vector__XXX
SG_ EngineOilMist2Concentration : 8|8@1+ (1,0) [0|250] "%" Vector__XXX
SG_ EngineOilMist3Concentration : 16|8@1+ (1,0) [0|250] "%" Vector__XXX
SG_ EngineOilMist4Concentration : 24|8@1+ (1,0) [0|250] "%" Vector__XXX
SG_ EngineOilMist5Concentration : 32|8@1+ (1,0) [0|250] "%" Vector__XXX
SG_ EngineOilMist6Concentration : 40|8@1+ (1,0) [0|250] "%" Vector__XXX
SG_ EngineOilMist7Concentration : 48|8@1+ (1,0) [0|250] "%" Vector__XXX
SG_ EngineOilMist8Concentration : 56|8@1+ (1,0) [0|250] "%" Vector__XXX

BO_ 2499557886 GFSP2: 8 Vector__XXX
SG_ PlantGasFuelSupplyOutletPressure : 0|16@1+ (0.5,0) [0|32127.5] "kPa" Vector__XXX
SG_ PlantInertGsSupplyOutletPressure : 16|16@1+ (0.5,0) [0|32127.5] "kPa" Vector__XXX

BO_ 2499558142 GFSP1: 8 Vector__XXX
SG_ EngineGaseousFuelSupplyPressure2 : 0|16@1+ (0.5,0) [0|32127.5] "kPa" Vector__XXX
SG_ EngGsFuelSupplyUnitIntkPressure : 16|16@1+ (0.5,0) [0|32127.5] "kPa" Vector__XXX
SG_ EngGsFuelSuppShtoffVlv1IntkPress : 32|16@1+ (0.5,0) [0|32127.5] "kPa" Vector__XXX
SG_ EngGsFuelSuppShtoffVlv2IntkPress : 48|16@1+ (0.5,0) [0|32127.5] "kPa" Vector__XXX

BO_ 2566667262 EEBT3: 8 Vector__XXX
SG_ EngineEndBearing17Temperature : 0|8@1+ (1,-40) [-40|210] "deg C" Vector__XXX
SG_ EngineEndBearing18Temperature : 8|8@1+ (1,-40) [-40|210] "deg C" Vector__XXX
SG_ EngineEndBearing19Temperature : 16|8@1+ (1,-40) [-40|210] "deg C" Vector__XXX
SG_ EngineEndBearing20Temperature : 24|8@1+ (1,-40) [-40|210] "deg C" Vector__XXX

BO_ 2566667518 EEBT2: 8 Vector__XXX
SG_ EngineEndBearing9Temperature : 0|8@1+ (1,-40) [-40|210] "deg C" Vector__XXX
SG_ EngineEndBearing10Temperature : 8|8@1+ (1,-40) [-40|210] "deg C" Vector__XXX
SG_ EngineEndBearing11Temperature : 16|8@1+ (1,-40) [-40|210] "deg C" Vector__XXX
SG_ EngineEndBearing12Temperature : 24|8@1+ (1,-40) [-40|210] "deg C" Vector__XXX
SG_ EngineEndBearing13Temperature : 32|8@1+ (1,-40) [-40|210] "deg C" Vector__XXX
SG_ EngineEndBearing14Temperature : 40|8@1+ (1,-40) [-40|210] "deg C" Vector__XXX
SG_ EngineEndBearing15Temperature : 48|8@1+ (1,-40) [-40|210] "deg C" Vector__XXX
SG_ EngineEndBearing16Temperature : 56|8@1+ (1,-40) [-40|210] "deg C" Vector__XXX

BO_ 2566667774 EEBT1: 8 Vector__XXX
SG_ EngineEndBearing1Temperature : 0|8@1+ (1,-40) [-40|210] "deg C" Vector__XXX
SG_ EngineEndBearing2Temperature : 8|8@1+ (1,-40) [-40|210] "deg C" Vector__XXX
SG_ EngineEndBearing3Temperature : 16|8@1+ (1,-40) [-40|210] "deg C" Vector__XXX
SG_ EngineEndBearing4Temperature : 24|8@1+ (1,-40) [-40|210] "deg C" Vector__XXX
SG_ EngineEndBearing5Temperature : 32|8@1+ (1,-40) [-40|210] "deg C" Vector__XXX
SG_ EngineEndBearing6Temperature : 40|8@1+ (1,-40) [-40|210] "deg C" Vector__XXX
SG_ EngineEndBearing7Temperature : 48|8@1+ (1,-40) [-40|210] "deg C" Vector__XXX
SG_ EngineEndBearing8Temperature : 56|8@1+ (1,-40) [-40|210] "deg C" Vector__XXX

BO_ 2566668030 HEDPI: 8 Vector__XXX
SG_ HeatExchangerDebrisPurgeStatus : 0|2@1+ (1,0) [0|3] "" Vector__XXX
SG_ HeatExchangerDebrisPurgeApprchng : 2|2@1+ (1,0) [0|3] "" Vector__XXX

BO_ 2566668286 ETCC2: 8 Vector__XXX
SG_ EngStagedTurboSolenoidStat : 0|8@1+ (0.4,0) [0|100] "%" Vector__XXX

BO_ 2566668542 EHF2PC: 8 Vector__XXX
SG_ EngFuel2PumpHydrFlwCtrlValve : 0|8@1+ (0.4,0) [0|100] "%" Vector__XXX
SG_ EngFuel2PumpHydrSwashPlateAgl : 8|8@1+ (0.4,0) [0|100] "%" Vector__XXX
SG_ EngFuel2PumpHydrDirectionalValve : 16|8@1+ (0.4,0) [0|100] "%" Vector__XXX
SG_ EngineFuel2PumpHydraulicPressure : 24|16@1+ (2,0) [0|128510] "kPa" Vector__XXX

BO_ 2566668798 AF4: 8 Vector__XXX
SG_ EngFuel2InjectrMeterngRail1Press : 0|16@1+ (2,0) [0|128510] "kPa" Vector__XXX
SG_ EngFuel2InjectrMeterngRail2Press : 16|16@1+ (2,0) [0|128510] "kPa" Vector__XXX
SG_ EngFuel2InjectrMeterngRail1Temp : 32|8@1+ (1,-40) [-40|210] "deg C" Vector__XXX
SG_ EngFuel2InjectrMeterngRail2Temp : 40|8@1+ (1,-40) [-40|210] "deg C" Vector__XXX
SG_ EngFuel2InjectrMtrngRail1Press2 : 48|16@1+ (2,0) [0|128510] "kPa" Vector__XXX

BO_ 2566669054 TIRE2: 8 Vector__XXX
SG_ TireLocation : 0|8@1+ (1,0) [0|255] "" Vector__XXX
SG_ TirePressure : 8|16@1+ (1,0) [0|64255] "kPa" Vector__XXX
SG_ RequiredTirePressure : 24|16@1+ (1,0) [0|64255] "kPa" Vector__XXX

BO_ 2566669310 TCSI: 8 Vector__XXX
SG_ TireLocation : 0|8@1+ (1,0) [0|255] "" Vector__XXX
SG_ ColdInflationPressure : 8|16@1+ (1,0) [0|64255] "kPa" Vector__XXX
SG_ UnderPressurePercentageThreshold : 24|8@1+ (0.5,0) [0|125] "%" Vector__XXX
SG_ ExtrmUnderPressPrcntageThreshold : 32|8@1+ (0.5,0) [0|125] "%" Vector__XXX
SG_ OverPressurePercentageThreshold : 40|8@1+ (0.5,0) [0|125] "%" Vector__XXX
SG_ OverTemperature : 48|8@1+ (1,-40) [-40|210] "deg C" Vector__XXX

BO_ 2566669822 TWSSI: 8 Vector__XXX
SG_ TotalNumberOfAntennasUsed : 0|8@1+ (1,0) [0|250] "" Vector__XXX
SG_ AntennaNumber : 0|8@1+ (1,0) [0|250] "" Vector__XXX
SG_ TotalNumberTireSensorsMonitored : 0|8@1+ (1,0) [0|250] "" Vector__XXX
SG_ TireSensorNumber : 0|8@1+ (1,0) [0|250] "" Vector__XXX
SG_ TireLocation : 0|8@1+ (1,0) [0|255] "" Vector__XXX
SG_ TireWirelessSigStrengthIndictr : 0|8@1+ (0.5,-125) [-125|0] "dBm" Vector__XXX

BO_ 2566670078 TSIS: 200 Vector__XXX
SG_ NumberOfTireSensors : 0|8@1+ (1,0) [0|250] "" Vector__XXX
SG_ TireNumber : 0|8@1+ (1,0) [0|250] "" Vector__XXX
SG_ TireLocation : 0|8@1+ (1,0) [0|255] "" Vector__XXX
SG_ TireSensorIdentificationNumber : 7|1600@0+ (1,0) [0|0] "ASCII" Vector__XXX

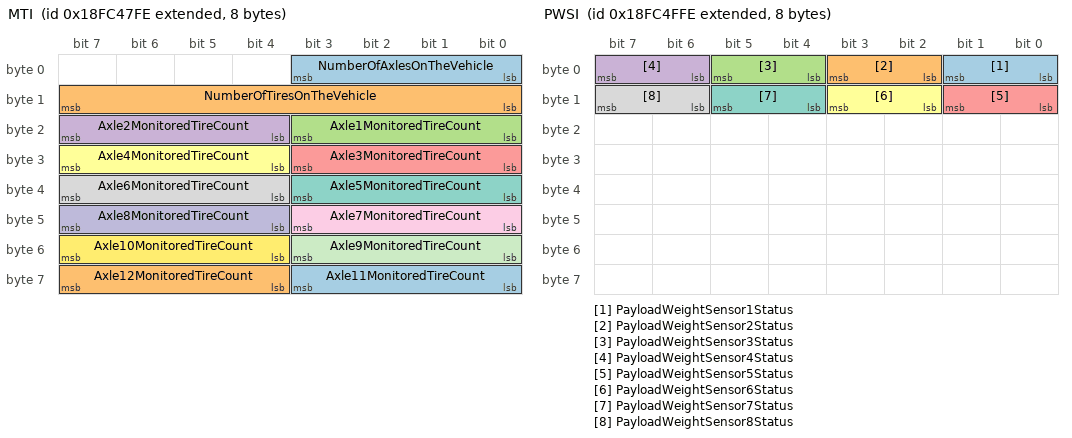
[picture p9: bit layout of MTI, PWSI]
BO_ 2566670334 MTI: 8 Vector__XXX
SG_ NumberOfAxlesOnTheVehicle : 0|4@1+ (1,0) [0|13] "" Vector__XXX
SG_ NumberOfTiresOnTheVehicle : 8|8@1+ (1,0) [0|250] "" Vector__XXX
SG_ Axle1MonitoredTireCount : 16|4@1+ (1,0) [0|13] "" Vector__XXX
SG_ Axle2MonitoredTireCount : 20|4@1+ (1,0) [0|13] "" Vector__XXX
SG_ Axle3MonitoredTireCount : 24|4@1+ (1,0) [0|13] "" Vector__XXX
SG_ Axle4MonitoredTireCount : 28|4@1+ (1,0) [0|13] "" Vector__XXX
SG_ Axle5MonitoredTireCount : 32|4@1+ (1,0) [0|13] "" Vector__XXX
SG_ Axle6MonitoredTireCount : 36|4@1+ (1,0) [0|13] "" Vector__XXX
SG_ Axle7MonitoredTireCount : 40|4@1+ (1,0) [0|13] "" Vector__XXX
SG_ Axle8MonitoredTireCount : 44|4@1+ (1,0) [0|13] "" Vector__XXX
SG_ Axle9MonitoredTireCount : 48|4@1+ (1,0) [0|13] "" Vector__XXX
SG_ Axle10MonitoredTireCount : 52|4@1+ (1,0) [0|13] "" Vector__XXX
SG_ Axle11MonitoredTireCount : 56|4@1+ (1,0) [0|13] "" Vector__XXX
SG_ Axle12MonitoredTireCount : 60|4@1+ (1,0) [0|13] "" Vector__XXX

BO_ 2566670590 AT2HI2: 24 Vector__XXX
SG_ Aft2SCRSysTotalSysCleaningTme : 0|32@1+ (1,0) [0|4211081215] "s" Vector__XXX
SG_ Aft2SCRSysTotalNoSysCleaningEvts : 32|32@1+ (1,0) [0|4211081215] "" Vector__XXX
SG_ Aft2SCRSysTotalNoSysCleangInhRqs : 64|32@1+ (1,0) [0|4211081215] "" Vector__XXX
SG_ Aft2SCRSysTotalNoSysCleangManRqs : 96|32@1+ (1,0) [0|4211081215] "" Vector__XXX
SG_ Aft2SCRSysAvrgTmeBtwnSysClngEvts : 128|32@1+ (1,0) [0|4211081215] "s" Vector__XXX
SG_ Aft2SCRSysAvDistBtwnSysClengEvts : 160|32@1+ (0.125,0) [0|526385151.875] "km" Vector__XXX

BO_ 2566670846 AT1HI2: 28 Vector__XXX
SG_ Aft1SCRSysTotalCleaningTme : 0|32@1+ (1,0) [0|4211081215] "s" Vector__XXX
SG_ Aft1SCRSysTotalNoOfSysCleangEvts : 32|32@1+ (1,0) [0|4211081215] "" Vector__XXX
SG_ Aft1SCRSysTotalNoSysCleangInhRqs : 64|32@1+ (1,0) [0|4211081215] "" Vector__XXX
SG_ Aft1SCRSysTotalNoSysCleangManRqs : 96|32@1+ (1,0) [0|4211081215] "" Vector__XXX
SG_ Aft1SCRSysAvrTmeBtwnSysCleanEvts : 128|32@1+ (1,0) [0|4211081215] "s" Vector__XXX
SG_ Aft1SCRSysAvDistBtwnSysCleanEvts : 160|32@1+ (0.125,0) [0|526385151.875] "km" Vector__XXX
SG_ TotalAftrtrtmntOperatingHours : 192|32@1+ (1,0) [0|4211081215] "s" Vector__XXX

BO_ 2566671102 SCRSC: 8 Vector__XXX
SG_ SCRSystemCleaningLampCommand : 0|3@1+ (1,0) [0|7] "" Vector__XXX
SG_ SCRSystemCleaningStatus : 10|2@1+ (1,0) [0|3] "" Vector__XXX
SG_ SCRSystemCleaningInhibitedStatus : 16|2@1+ (1,0) [0|3] "" Vector__XXX
SG_ SCRSystemCleaningInhbtdDTInhbtSw : 18|2@1+ (1,0) [0|3] "" Vector__XXX
SG_ SCRSysCleaningInhDTCltchDiseng : 20|2@1+ (1,0) [0|3] "" Vector__XXX
SG_ SCRSysCleaningInhbtdDTSrvcBrkAct : 22|2@1+ (1,0) [0|3] "" Vector__XXX
SG_ SCRSystemCleaningInhbtdDTPTOActv : 24|2@1+ (1,0) [0|3] "" Vector__XXX
SG_ SCRSysCleaningInhDTAcclPdlOffIdl : 26|2@1+ (1,0) [0|3] "" Vector__XXX
SG_ SCRSysCleaningInhbtdDTOutOfNtrl : 28|2@1+ (1,0) [0|3] "" Vector__XXX
SG_ SCRSysClnInhDTVhclSpdAbvAllwdSpd : 30|2@1+ (1,0) [0|3] "" Vector__XXX
SG_ SCRSysCleaningInhDTPrkBrkNotSet : 32|2@1+ (1,0) [0|3] "" Vector__XXX
SG_ SCRSysCleaningInhDTLowExhstTemp : 34|2@1+ (1,0) [0|3] "" Vector__XXX
SG_ SCRSysCleaningInhDTSysFaultAct : 36|2@1+ (1,0) [0|3] "" Vector__XXX
SG_ SCRSysCleaningInhbtdDTSysTimeout : 38|2@1+ (1,0) [0|3] "" Vector__XXX
SG_ SCRSysCleaningInhDTTmprySysLckt : 40|2@1+ (1,0) [0|3] "" Vector__XXX
SG_ SCRSysCleaningInhDTPrmntSysLckt : 42|2@1+ (1,0) [0|3] "" Vector__XXX
SG_ SCRSysCleangInhDTEngNotWarmedUp : 44|2@1+ (1,0) [0|3] "" Vector__XXX
SG_ SCRSysCleangInhDTVehicleSpeed : 46|2@1+ (1,0) [0|3] "" Vector__XXX
SG_ SCRSystemCleaningAutoInitConf : 48|2@1+ (1,0) [0|3] "" Vector__XXX
SG_ SCRSystemCleaningForcedStatus : 53|3@1+ (1,0) [0|7] "" Vector__XXX
SG_ Aft1SCRSysCondtnsNotMetActCleang : 60|2@1+ (1,0) [0|3] "" Vector__XXX

BO_ 2566671358 EEC17: 8 Vector__XXX
SG_ PEMSEngineFuelMassFlowRate : 0|16@1+ (0.02,0) [0|1285.1] "g/s" Vector__XXX
SG_ VehicleFuelRate : 16|16@1+ (0.02,0) [0|1285.1] "g/s" Vector__XXX
SG_ EngineExhaustFlowRate : 32|16@1+ (0.2,0) [0|12851] "kg/h" Vector__XXX
SG_ CylinderFuelRate : 48|16@1+ (0.03125,0) [0|2007.96875] "mg/stroke" Vector__XXX

BO_ 2566671614 SCROII3: 8 Vector__XXX
SG_ SCROperatorIndcmntOverrideEnbl : 0|2@1+ (1,0) [0|3] "" Vector__XXX
SG_ SCROprtrIndcmntOvrrdTimeRemain : 8|16@1+ (1,0) [0|64255] "s" Vector__XXX
SG_ NoSCROprtrIndcmntOvrrdEvtsRemain : 24|8@1+ (1,0) [0|250] "" Vector__XXX
SG_ TotalNoSCROprtrIndcmntOvrrdEvts : 32|16@1+ (1,0) [0|64255] "" Vector__XXX

BO_ 2566671870 A2SCRDSI3: 8 Vector__XXX
SG_ Aftrtrtmnt2DslExhstFldDsngPress : 0|8@1+ (4,0) [0|1000] "kPa" Vector__XXX
SG_ Aft2DslExhstFldDoser2AbsPress : 8|8@1+ (8,0) [0|2000] "kPa" Vector__XXX
SG_ Aftrtrtmnt2DslExhstFldDoser2Temp : 16|8@1+ (1,-40) [-40|210] "deg C" Vector__XXX
SG_ Aft2DslExhstFldDoser2Press : 24|8@1+ (4,0) [0|1000] "kPa" Vector__XXX

BO_ 2566672126 A1SCRDSI3: 8 Vector__XXX
SG_ Aftrtrtmnt1DslExhstFldDsngPress : 0|8@1+ (4,0) [0|1000] "kPa" Vector__XXX
SG_ Aft1DslExhstFldDoser2AbsPress : 8|8@1+ (8,0) [0|2000] "kPa" Vector__XXX
SG_ Aftrtrtmnt1DslExhstFldDoser2Temp : 16|8@1+ (1,-40) [-40|210] "deg C" Vector__XXX
SG_ Aft1DslExhstFldDoser2Press : 24|8@1+ (4,0) [0|1000] "kPa" Vector__XXX

BO_ 2566672382 PWSI: 8 Vector__XXX
SG_ PayloadWeightSensor1Status : 0|2@1+ (1,0) [0|3] "" Vector__XXX
SG_ PayloadWeightSensor2Status : 2|2@1+ (1,0) [0|3] "" Vector__XXX
SG_ PayloadWeightSensor3Status : 4|2@1+ (1,0) [0|3] "" Vector__XXX
SG_ PayloadWeightSensor4Status : 6|2@1+ (1,0) [0|3] "" Vector__XXX
SG_ PayloadWeightSensor5Status : 8|2@1+ (1,0) [0|3] "" Vector__XXX
SG_ PayloadWeightSensor6Status : 10|2@1+ (1,0) [0|3] "" Vector__XXX
SG_ PayloadWeightSensor7Status : 12|2@1+ (1,0) [0|3] "" Vector__XXX
SG_ PayloadWeightSensor8Status : 14|2@1+ (1,0) [0|3] "" Vector__XXX

BO_ 2566672638 PLSS: 8 Vector__XXX
SG_ HaulCycleCount : 0|16@1+ (1,0) [0|64255] "" Vector__XXX
SG_ HaulModeStatus : 16|4@1+ (1,0) [0|15] "" Vector__XXX
SG_ PayloadDeliveryTransactionStatus : 20|4@1+ (1,0) [0|15] "" Vector__XXX
SG_ DeliveredPayloadWeight : 24|24@1+ (2,0) [0|32899070] "kg" Vector__XXX
SG_ DeliveredPayloadConfidence : 48|8@1+ (0.5,0) [0|125] "%" Vector__XXX

BO_ 2365346302 ASC7: 8 Vector__XXX
SG_ LiftAxle1Status : 0|3@1+ (1,0) [0|7] "" Vector__XXX
SG_ LiftAxle2Status : 3|3@1+ (1,0) [0|7] "" Vector__XXX
SG_ LiftAxle3Status : 8|3@1+ (1,0) [0|7] "" Vector__XXX
SG_ LiftAxle4Status : 11|3@1+ (1,0) [0|7] "" Vector__XXX

BO_ 2633782014 BWLN: 8 Vector__XXX
SG_ BinInstance : 0|4@1+ (1,0) [0|15] "" Vector__XXX
SG_ BinWeighingErrorStatus : 4|4@1+ (1,0) [0|15] "" Vector__XXX
SG_ BinLiftCount : 8|16@1+ (1,0) [0|64255] "" Vector__XXX
SG_ NetBinWeight : 24|16@1+ (2,0) [0|128510] "kg" Vector__XXX

BO_ 2566673406 EGLI: 8 Vector__XXX
SG_ GaseousFuelLeakage1Concentration : 0|8@1+ (0.5,0) [0|125] "%" Vector__XXX
SG_ GaseousFuelLeakage2Concentration : 8|8@1+ (0.5,0) [0|125] "%" Vector__XXX
SG_ GaseousFuelLeakage3Concentration : 16|8@1+ (0.5,0) [0|125] "%" Vector__XXX
SG_ GasLeakageDetection1Pressure : 24|8@1+ (4,0) [0|1000] "kPa" Vector__XXX
SG_ GasLeakageDetection2Pressure : 32|8@1+ (4,0) [0|1000] "kPa" Vector__XXX
SG_ GasLeakageDetection3Pressure : 40|8@1+ (4,0) [0|1000] "kPa" Vector__XXX

BO_ 2566674174 SCROII2: 8 Vector__XXX
SG_ AftertreatmentSCRMalfunctionTime : 0|32@1+ (1,0) [0|4211081215] "s" Vector__XXX
SG_ SCROperatorInducementTotalTime : 32|32@1+ (1,0) [0|4211081215] "s" Vector__XXX

BO_ 2566674430 SCROII1: 8 Vector__XXX
SG_ DieselExhaustFluidTank1EmptyTime : 0|32@1+ (1,0) [0|4211081215] "s" Vector__XXX
SG_ DslExhstFldQualityMalfunctionTme : 32|32@1+ (1,0) [0|4211081215] "s" Vector__XXX

BO_ 2566674686 TCI7: 8 Vector__XXX
SG_ EngTurbocharger2LubeOilPressure : 0|8@1+ (4,0) [0|1000] "kPa" Vector__XXX
SG_ EngTurbocharger3LubeOilPressure : 8|8@1+ (4,0) [0|1000] "kPa" Vector__XXX
SG_ EngTurbocharger4LubeOilPressure : 16|8@1+ (4,0) [0|1000] "kPa" Vector__XXX
SG_ EngTurbocharger2OilTemperature : 24|16@1+ (0.03125,-273) [-273|1734.96875] "deg C" Vector__XXX

BO_ 2365348350 ELS: 8 Vector__XXX
SG_ EngineUnloadStatus : 0|2@1+ (1,0) [0|3] "" Vector__XXX
SG_ EngineLoadShareStatus : 2|4@1+ (1,0) [0|15] "" Vector__XXX

BO_ 2566675966 HVESSCFG: 16 Vector__XXX
SG_ HVES1NominalVoltage : 0|16@1+ (0.05,0) [0|3212.75] "V" Vector__XXX
SG_ HVES1RecommendedMinOprtngVoltage : 16|16@1+ (0.05,0) [0|3212.75] "V" Vector__XXX
SG_ HVES1RecommendedMaxOprtngVoltage : 32|16@1+ (0.05,0) [0|3212.75] "V" Vector__XXX
SG_ HVES1RecommendedMinimumStateChrg : 48|16@1+ (0.0015625,0) [0|100.3984375] "%" Vector__XXX
SG_ HVES1RecommendedMaximumStateChrg : 64|16@1+ (0.0015625,0) [0|100.3984375] "%" Vector__XXX
SG_ HVES1RecommendedMaxOprtngTemp : 80|16@1+ (0.03125,-273) [-273|1734.96875] "deg C" Vector__XXX
SG_ HVES1RecommendedMinOprtngTemp : 96|16@1+ (0.03125,-273) [-273|1734.96875] "deg C" Vector__XXX
SG_ HVES1CellMaximumVoltageLimit : 112|8@1+ (0.02044,0) [0|5.11] "V" Vector__XXX
SG_ HVES1CellMinimumVoltageLimit : 120|8@1+ (0.02044,0) [0|5.11] "V" Vector__XXX

BO_ 2633785086 HVESSHIST: 11 Vector__XXX
SG_ HVES1StateOfHealth : 0|8@1+ (0.4,0) [0|100] "%" Vector__XXX
SG_ HVES1ContactorOpenUnderLoadCount : 8|16@1+ (1,0) [0|64255] "" Vector__XXX
SG_ HVES1TotalEnergyThroughput : 24|32@1+ (100,0) [0|421108121500] "Watt-hour" Vector__XXX
SG_ HVES1TotalAccumulatedCharge : 56|32@1+ (100,0) [0|421108121500] "Ah" Vector__XXX

BO_ 2566687742 AFT1PSI2: 8 Vector__XXX
SG_ Aft1PrticulateSnsrDetctnStat : 0|4@1+ (1,0) [0|15] "" Vector__XXX
SG_ Aft1PrticulateSnsrPwrSupply : 4|2@1+ (1,0) [0|3] "" Vector__XXX
SG_ Aft1PrticulateSnsrRegenFailedCnt : 8|8@1+ (1,0) [0|250] "" Vector__XXX
SG_ Aftrtrtmnt1PrticulateSnsrTemp : 16|16@1+ (0.03125,-273) [-273|1734.96875] "deg C" Vector__XXX
SG_ Aft1PrticulateSnsrMaxResist : 32|8@1+ (250,0) [0|62500] "kohm" Vector__XXX
SG_ Aftrtrtmnt1PrtcltSensorHtrResist : 40|16@1+ (0.1,0) [0|6425.5] "ohm" Vector__XXX

BO_ 2566687998 AFT1PSI1: 8 Vector__XXX
SG_ Aftrtrtmnt1PrticulateSnsrResist : 0|16@1+ (1,0) [0|64255] "kohm" Vector__XXX
SG_ Aftrtrtmnt1PrticulateSnsrHtrStat : 16|2@1+ (1,0) [0|3] "" Vector__XXX
SG_ Aft1PrticulateSnsrRegenStatus : 18|2@1+ (1,0) [0|3] "" Vector__XXX
SG_ Aft1PrticulateSnsrRegenState : 20|4@1+ (1,0) [0|15] "" Vector__XXX
SG_ Aft1PrticulateSnsrActAccmltTme : 24|16@1+ (6,0) [0|385530] "s" Vector__XXX
SG_ Aft1PrticulateSnsrTmeBetweenRegs : 40|16@1+ (6,0) [0|385530] "s" Vector__XXX

BO_ 2566688254 PII: 7 Vector__XXX
SG_ ProductIdentificationCode : 0|50@1+ (1,0) [0|1.12589990684262E015] "" Vector__XXX
SG_ ProductIdentificationBrand : 0|50@1+ (1,0) [0|1.12589990684262E015] "" Vector__XXX
SG_ ProductIdentificationModel : 0|50@1+ (1,0) [0|1.12589990684262E015] "" Vector__XXX

BO_ 2566688510 CFF: 0 Vector__XXX

BO_ 2432471038 AF3: 8 Vector__XXX
SG_ EngineGasSupplyPressure : 0|16@1+ (0.00390625,0) [0|250.996] "MPa" Vector__XXX
SG_ EngFuelVaporizer1DischargeTemp : 16|8@1+ (1,-40) [-40|210] "deg C" Vector__XXX
SG_ EngGaseousFuelFilterOtltTemp : 24|8@1+ (1,-40) [-40|210] "deg C" Vector__XXX
SG_ EngGsFuelSupplyPressRgltrCtrlCmd : 32|16@1+ (0.0025,0) [0|160.6375] "%" Vector__XXX

BO_ 2499580158 EFIMRPI1: 8 Vector__XXX
SG_ EngInjectorMeteringRail1Press1 : 0|16@1+ (0.00390625,0) [0|250.996] "MPa" Vector__XXX
SG_ EngInjectorMeteringRail1Press2 : 16|16@1+ (0.00390625,0) [0|250.996] "MPa" Vector__XXX
SG_ EngInjectorMeteringRail2Press1 : 32|16@1+ (0.00390625,0) [0|250.996] "MPa" Vector__XXX
SG_ EngInjectorMeteringRail2Press2 : 48|16@1+ (0.00390625,0) [0|250.996] "MPa" Vector__XXX

BO_ 2566689278 EEN: 8 Vector__XXX
SG_ EngineExhaustNOx : 0|16@1+ (0.05,-200) [-200|3012.75] "ppm" Vector__XXX
SG_ EngineExhaustDesiredNOx : 16|16@1+ (0.05,-200) [-200|3012.75] "ppm" Vector__XXX
SG_ EngExhaustNOxSensorPowerSupply : 32|2@1+ (1,0) [0|3] "" Vector__XXX

BO_ 2566689534 AFR: 8 Vector__XXX
SG_ EngineMainChamberAirFuelRatio : 0|16@1+ (0.001,0) [0|64.255] "" Vector__XXX
SG_ EngMainChamberDsrdAirFuelRatio : 16|16@1+ (0.001,0) [0|64.255] "" Vector__XXX
SG_ EnginePrechamberAirFuelRatio : 32|16@1+ (0.001,0) [0|64.255] "" Vector__XXX
SG_ EnginePrechamberDsrdAirFuelRatio : 48|16@1+ (0.001,0) [0|64.255] "" Vector__XXX

BO_ 2566689790 GFP2: 8 Vector__XXX
SG_ EngineMainChamberFuelAbsPressure : 0|16@1+ (0.1,0) [0|6425.5] "kPa" Vector__XXX
SG_ EngMainChamberFuelDsrdAbsPress : 16|16@1+ (0.1,0) [0|6425.5] "kPa" Vector__XXX
SG_ EnginePrechamberFuelAbsPressure : 32|16@1+ (0.1,0) [0|6425.5] "kPa" Vector__XXX
SG_ EngPrechamberFuelDsrdAbsPressure : 48|16@1+ (0.1,0) [0|6425.5] "kPa" Vector__XXX

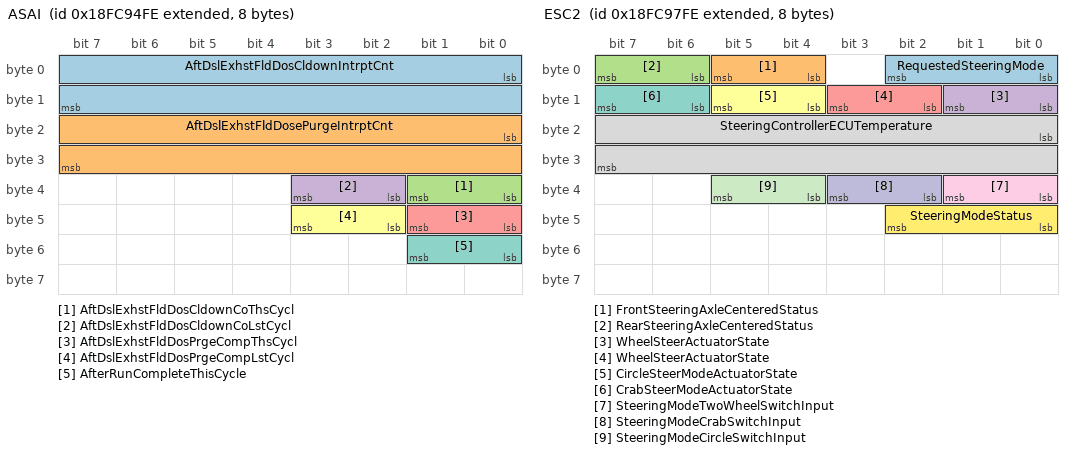
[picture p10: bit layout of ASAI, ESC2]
BO_ 2566690046 ASAI: 8 Vector__XXX
SG_ AftDslExhstFldDosCldownIntrptCnt : 0|16@1+ (1,0) [0|64255] "" Vector__XXX
SG_ AftDslExhstFldDosePurgeIntrptCnt : 16|16@1+ (1,0) [0|64255] "" Vector__XXX
SG_ AftDslExhstFldDosCldownCoThsCycl : 32|2@1+ (1,0) [0|3] "" Vector__XXX
SG_ AftDslExhstFldDosCldownCoLstCycl : 34|2@1+ (1,0) [0|3] "" Vector__XXX
SG_ AftDslExhstFldDosPrgeCompThsCycl : 40|2@1+ (1,0) [0|3] "" Vector__XXX
SG_ AftDslExhstFldDosPrgeCompLstCycl : 42|2@1+ (1,0) [0|3] "" Vector__XXX
SG_ AfterRunCompleteThisCycle : 48|2@1+ (1,0) [0|3] "" Vector__XXX

BO_ 2365363710 ECPMSI: 8 Vector__XXX
SG_ EngCylPressureMonitor1PrelimFMI : 0|5@1+ (1,0) [0|31] "" Vector__XXX
SG_ EngCylPressureMonitor2PrelimFMI : 8|5@1+ (1,0) [0|31] "" Vector__XXX

BO_ 2566690558 EI2: 8 Vector__XXX
SG_ EngineExhaustPressure1 : 0|16@1+ (0.125,0) [0|8031.875] "kPa" Vector__XXX
SG_ EngineOilFilterIntakePressure : 16|16@1+ (0.1,0) [0|6425.5] "kPa" Vector__XXX
SG_ EngineCommonRailOilPressure : 32|8@1+ (4,0) [0|1000] "kPa" Vector__XXX
SG_ EngineCommonRailOilAbsPressure : 40|8@1+ (4,0) [0|1000] "kPa" Vector__XXX
SG_ EngineExhaustPressure2 : 48|16@1+ (0.0078125,-250) [-250|251.99] "kPa" Vector__XXX

BO_ 2566690814 ESC2: 8 Vector__XXX
SG_ RequestedSteeringMode : 0|3@1+ (1,0) [0|7] "" Vector__XXX
SG_ FrontSteeringAxleCenteredStatus : 4|2@1+ (1,0) [0|3] "" Vector__XXX
SG_ RearSteeringAxleCenteredStatus : 6|2@1+ (1,0) [0|3] "" Vector__XXX
SG_ WheelSteerActuatorState : 8|2@1+ (1,0) [0|3] "" Vector__XXX
SG_ WheelSteerActuatorState : 10|2@1+ (1,0) [0|3] "" Vector__XXX
SG_ CircleSteerModeActuatorState : 12|2@1+ (1,0) [0|3] "" Vector__XXX
SG_ CrabSteerModeActuatorState : 14|2@1+ (1,0) [0|3] "" Vector__XXX
SG_ SteeringControllerECUTemperature : 16|16@1+ (0.03125,-273) [-273|1734.96875] "deg C" Vector__XXX
SG_ SteeringModeTwoWheelSwitchInput : 32|2@1+ (1,0) [0|3] "" Vector__XXX
SG_ SteeringModeCrabSwitchInput : 34|2@1+ (1,0) [0|3] "" Vector__XXX
SG_ SteeringModeCircleSwitchInput : 36|2@1+ (1,0) [0|3] "" Vector__XXX
SG_ SteeringModeStatus : 40|3@1+ (1,0) [0|7] "" Vector__XXX

BO_ 2499582206 VSL: 8 Vector__XXX
SG_ SoftTopSpeedLimitActive : 0|2@1+ (1,0) [0|3] "" Vector__XXX
SG_ SoftTopRatioLimitExceeded : 2|2@1+ (1,0) [0|3] "" Vector__XXX
SG_ SoftTopSpeedLimitRemainingDist : 8|16@1+ (1,0) [0|64255] "km" Vector__XXX
SG_ SoftTopSpeedLimitResetDistance : 24|16@1+ (1,0) [0|64255] "km" Vector__XXX
SG_ StTopSpdLmtRemainCntnsIntrvlDist : 40|16@1+ (1,0) [0|64255] "km" Vector__XXX

BO_ 2566691326 AUI: 201 Vector__XXX
SG_ NoAssemblyUnitIdentifyFields : 0|8@1+ (1,0) [0|250] "" Vector__XXX
SG_ AssemblyUnitIdentification : 15|1600@0+ (1,0) [0|0] "ASCII" Vector__XXX

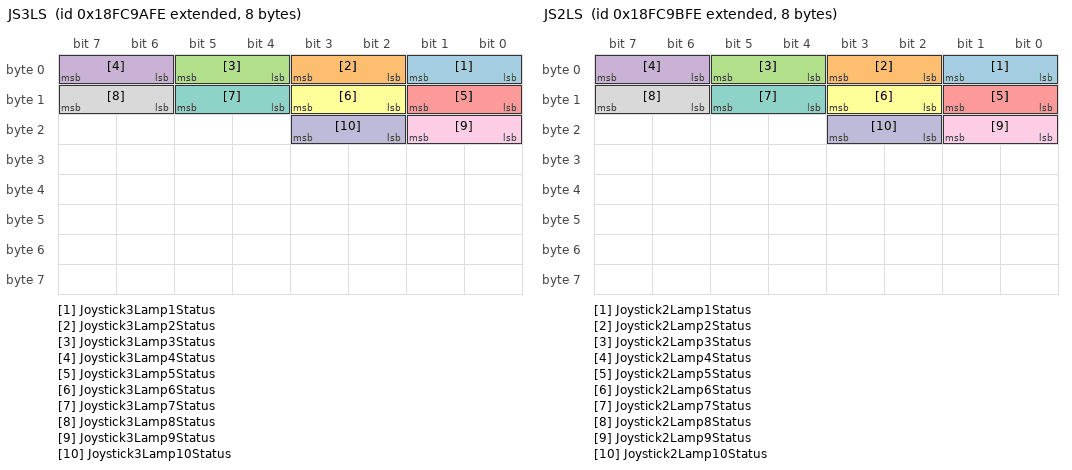
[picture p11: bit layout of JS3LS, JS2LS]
BO_ 2566691582 JS3LS: 8 Vector__XXX
SG_ Joystick3Lamp1Status : 0|2@1+ (1,0) [0|3] "" Vector__XXX
SG_ Joystick3Lamp2Status : 2|2@1+ (1,0) [0|3] "" Vector__XXX
SG_ Joystick3Lamp3Status : 4|2@1+ (1,0) [0|3] "" Vector__XXX
SG_ Joystick3Lamp4Status : 6|2@1+ (1,0) [0|3] "" Vector__XXX
SG_ Joystick3Lamp5Status : 8|2@1+ (1,0) [0|3] "" Vector__XXX
SG_ Joystick3Lamp6Status : 10|2@1+ (1,0) [0|3] "" Vector__XXX
SG_ Joystick3Lamp7Status : 12|2@1+ (1,0) [0|3] "" Vector__XXX
SG_ Joystick3Lamp8Status : 14|2@1+ (1,0) [0|3] "" Vector__XXX
SG_ Joystick3Lamp9Status : 16|2@1+ (1,0) [0|3] "" Vector__XXX
SG_ Joystick3Lamp10Status : 18|2@1+ (1,0) [0|3] "" Vector__XXX

BO_ 2566691838 JS2LS: 8 Vector__XXX
SG_ Joystick2Lamp1Status : 0|2@1+ (1,0) [0|3] "" Vector__XXX
SG_ Joystick2Lamp2Status : 2|2@1+ (1,0) [0|3] "" Vector__XXX
SG_ Joystick2Lamp3Status : 4|2@1+ (1,0) [0|3] "" Vector__XXX
SG_ Joystick2Lamp4Status : 6|2@1+ (1,0) [0|3] "" Vector__XXX
SG_ Joystick2Lamp5Status : 8|2@1+ (1,0) [0|3] "" Vector__XXX
SG_ Joystick2Lamp6Status : 10|2@1+ (1,0) [0|3] "" Vector__XXX
SG_ Joystick2Lamp7Status : 12|2@1+ (1,0) [0|3] "" Vector__XXX
SG_ Joystick2Lamp8Status : 14|2@1+ (1,0) [0|3] "" Vector__XXX
SG_ Joystick2Lamp9Status : 16|2@1+ (1,0) [0|3] "" Vector__XXX
SG_ Joystick2Lamp10Status : 18|2@1+ (1,0) [0|3] "" Vector__XXX

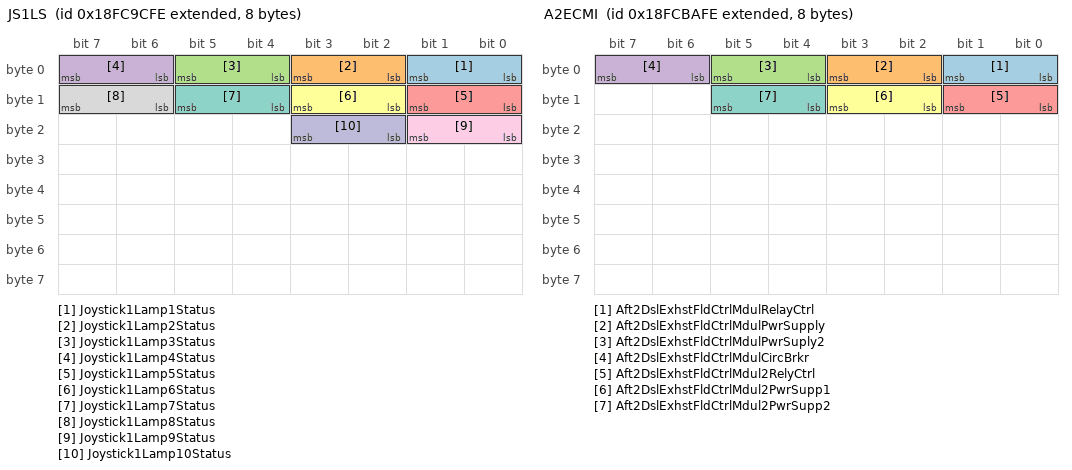
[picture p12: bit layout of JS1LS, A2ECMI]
BO_ 2566692094 JS1LS: 8 Vector__XXX
SG_ Joystick1Lamp1Status : 0|2@1+ (1,0) [0|3] "" Vector__XXX
SG_ Joystick1Lamp2Status : 2|2@1+ (1,0) [0|3] "" Vector__XXX
SG_ Joystick1Lamp3Status : 4|2@1+ (1,0) [0|3] "" Vector__XXX
SG_ Joystick1Lamp4Status : 6|2@1+ (1,0) [0|3] "" Vector__XXX
SG_ Joystick1Lamp5Status : 8|2@1+ (1,0) [0|3] "" Vector__XXX
SG_ Joystick1Lamp6Status : 10|2@1+ (1,0) [0|3] "" Vector__XXX
SG_ Joystick1Lamp7Status : 12|2@1+ (1,0) [0|3] "" Vector__XXX
SG_ Joystick1Lamp8Status : 14|2@1+ (1,0) [0|3] "" Vector__XXX
SG_ Joystick1Lamp9Status : 16|2@1+ (1,0) [0|3] "" Vector__XXX
SG_ Joystick1Lamp10Status : 18|2@1+ (1,0) [0|3] "" Vector__XXX

BO_ 2499583486 ETAPC: 8 Vector__XXX
SG_ EngineTimingActr1PositionCommand : 0|3@1+ (1,0) [0|7] "" Vector__XXX
SG_ EngineTimingActr2PositionCommand : 3|3@1+ (1,0) [0|7] "" Vector__XXX

BO_ 2499583742 ETAP: 8 Vector__XXX
SG_ EngineTimingActuator1 : 0|3@1+ (1,0) [0|7] "" Vector__XXX
SG_ EngineTimingActuator2 : 3|3@1+ (1,0) [0|7] "" Vector__XXX
SG_ EngTimingActr1RequestedPosition : 8|3@1+ (1,0) [0|7] "" Vector__XXX
SG_ EngTimingActr2RequestedPosition : 11|3@1+ (1,0) [0|7] "" Vector__XXX

BO_ 2566692862 DD2: 8 Vector__XXX
SG_ EngineOilFilterDiffPressure : 0|16@1+ (0.0078125,-250) [-250|251.99] "kPa" Vector__XXX
SG_ EngineFuel2Tank1Level : 16|8@1+ (0.4,0) [0|100] "%" Vector__XXX
SG_ EngineFuel2Tank2Level : 24|8@1+ (0.4,0) [0|100] "%" Vector__XXX
SG_ EngineFuel2Tank3Level : 32|8@1+ (0.4,0) [0|100] "%" Vector__XXX
SG_ EngineFuel2Tank4Level : 40|8@1+ (0.4,0) [0|100] "%" Vector__XXX
SG_ DisplayRemainPowered : 48|2@1+ (1,0) [0|3] "" Vector__XXX
SG_ EngineOilLevelHighLow : 56|8@1+ (0.5,-62.5) [-62.5|62.5] "l" Vector__XXX

BO_ 2633801982 MFEH: 8 Vector__XXX
SG_ EngTotalHoursOfGaseousFuelOp : 0|32@1+ (0.05,0) [0|210554060.75] "h" Vector__XXX
SG_ EngTotalHoursOfDslFuelOperation : 32|32@1+ (0.05,0) [0|210554060.75] "h" Vector__XXX

BO_ 2633802238 ESMR3: 8 Vector__XXX
SG_ EngineSparkPlug17MisfireRate : 0|8@1+ (0.4,0) [0|100] "%" Vector__XXX
SG_ EngineSparkPlug18MisfireRate : 8|8@1+ (0.4,0) [0|100] "%" Vector__XXX
SG_ EngineSparkPlug19MisfireRate : 16|8@1+ (0.4,0) [0|100] "%" Vector__XXX
SG_ EngineSparkPlug20MisfireRate : 24|8@1+ (0.4,0) [0|100] "%" Vector__XXX
SG_ EngineSparkPlug21MisfireRate : 32|8@1+ (0.4,0) [0|100] "%" Vector__XXX
SG_ EngineSparkPlug22MisfireRate : 40|8@1+ (0.4,0) [0|100] "%" Vector__XXX
SG_ EngineSparkPlug23MisfireRate : 48|8@1+ (0.4,0) [0|100] "%" Vector__XXX
SG_ EngineSparkPlug24MisfireRate : 56|8@1+ (0.4,0) [0|100] "%" Vector__XXX

BO_ 2633802494 ESMR2: 8 Vector__XXX
SG_ EngineSparkPlug9MisfireRate : 0|8@1+ (0.4,0) [0|100] "%" Vector__XXX
SG_ EngineSparkPlug10MisfireRate : 8|8@1+ (0.4,0) [0|100] "%" Vector__XXX
SG_ EngineSparkPlug11MisfireRate : 16|8@1+ (0.4,0) [0|100] "%" Vector__XXX
SG_ EngineSparkPlug12MisfireRate : 24|8@1+ (0.4,0) [0|100] "%" Vector__XXX
SG_ EngineSparkPlug13MisfireRate : 32|8@1+ (0.4,0) [0|100] "%" Vector__XXX
SG_ EngineSparkPlug14MisfireRate : 40|8@1+ (0.4,0) [0|100] "%" Vector__XXX
SG_ EngineSparkPlug15MisfireRate : 48|8@1+ (0.4,0) [0|100] "%" Vector__XXX
SG_ EngineSparkPlug16MisfireRate : 56|8@1+ (0.4,0) [0|100] "%" Vector__XXX

BO_ 2633802750 ESMR1: 8 Vector__XXX
SG_ EngineSparkPlug1MisfireRate : 0|8@1+ (0.4,0) [0|100] "%" Vector__XXX
SG_ EngineSparkPlug2MisfireRate : 8|8@1+ (0.4,0) [0|100] "%" Vector__XXX
SG_ EngineSparkPlug3MisfireRate : 16|8@1+ (0.4,0) [0|100] "%" Vector__XXX
SG_ EngineSparkPlug4MisfireRate : 24|8@1+ (0.4,0) [0|100] "%" Vector__XXX
SG_ EngineSparkPlug5MisfireRate : 32|8@1+ (0.4,0) [0|100] "%" Vector__XXX
SG_ EngineSparkPlug6MisfireRate : 40|8@1+ (0.4,0) [0|100] "%" Vector__XXX
SG_ EngineSparkPlug7MisfireRate : 48|8@1+ (0.4,0) [0|100] "%" Vector__XXX
SG_ EngineSparkPlug8MisfireRate : 56|8@1+ (0.4,0) [0|100] "%" Vector__XXX

BO_ 2633803006 ESVMAX6: 8 Vector__XXX
SG_ EngineSparkPlug21MaximumVoltage : 0|16@1+ (1,0) [0|64255] "V" Vector__XXX
SG_ EngineSparkPlug22MaximumVoltage : 16|16@1+ (1,0) [0|64255] "V" Vector__XXX
SG_ EngineSparkPlug23MaximumVoltage : 32|16@1+ (1,0) [0|64255] "V" Vector__XXX
SG_ EngineSparkPlug24MaximumVoltage : 48|16@1+ (1,0) [0|64255] "V" Vector__XXX

BO_ 2633803262 ESVMAX5: 8 Vector__XXX
SG_ EngineSparkPlug17MaximumVoltage : 0|16@1+ (1,0) [0|64255] "V" Vector__XXX
SG_ EngineSparkPlug18MaximumVoltage : 16|16@1+ (1,0) [0|64255] "V" Vector__XXX
SG_ EngineSparkPlug19MaximumVoltage : 32|16@1+ (1,0) [0|64255] "V" Vector__XXX
SG_ EngineSparkPlug20MaximumVoltage : 48|16@1+ (1,0) [0|64255] "V" Vector__XXX

BO_ 2633803518 ESVMAX4: 8 Vector__XXX
SG_ EngineSparkPlug13MaximumVoltage : 0|16@1+ (1,0) [0|64255] "V" Vector__XXX
SG_ EngineSparkPlug14MaximumVoltage : 16|16@1+ (1,0) [0|64255] "V" Vector__XXX
SG_ EngineSparkPlug15MaximumVoltage : 32|16@1+ (1,0) [0|64255] "V" Vector__XXX
SG_ EngineSparkPlug16MaximumVoltage : 48|16@1+ (1,0) [0|64255] "V" Vector__XXX

BO_ 2633803774 ESVMAX3: 8 Vector__XXX
SG_ EngineSparkPlug9MaximumVoltage : 0|16@1+ (1,0) [0|64255] "V" Vector__XXX
SG_ EngineSparkPlug10MaximumVoltage : 16|16@1+ (1,0) [0|64255] "V" Vector__XXX
SG_ EngineSparkPlug11MaximumVoltage : 32|16@1+ (1,0) [0|64255] "V" Vector__XXX
SG_ EngineSparkPlug12MaximumVoltage : 48|16@1+ (1,0) [0|64255] "V" Vector__XXX

BO_ 2633804030 ESVMAX2: 8 Vector__XXX
SG_ EngineSparkPlug5MaximumVoltage : 0|16@1+ (1,0) [0|64255] "V" Vector__XXX
SG_ EngineSparkPlug6MaximumVoltage : 16|16@1+ (1,0) [0|64255] "V" Vector__XXX
SG_ EngineSparkPlug7MaximumVoltage : 32|16@1+ (1,0) [0|64255] "V" Vector__XXX
SG_ EngineSparkPlug8MaximumVoltage : 48|16@1+ (1,0) [0|64255] "V" Vector__XXX

BO_ 2633804286 ESVMAX1: 8 Vector__XXX
SG_ EngineSparkPlug1MaximumVoltage : 0|16@1+ (1,0) [0|64255] "V" Vector__XXX
SG_ EngineSparkPlug2MaximumVoltage : 16|16@1+ (1,0) [0|64255] "V" Vector__XXX
SG_ EngineSparkPlug3MaximumVoltage : 32|16@1+ (1,0) [0|64255] "V" Vector__XXX
SG_ EngineSparkPlug4MaximumVoltage : 48|16@1+ (1,0) [0|64255] "V" Vector__XXX

BO_ 2633804542 ESVMIN6: 8 Vector__XXX
SG_ EngineSparkPlug21MinimumVoltage : 0|16@1+ (1,0) [0|64255] "V" Vector__XXX
SG_ EngineSparkPlug22MinimumVoltage : 16|16@1+ (1,0) [0|64255] "V" Vector__XXX
SG_ EngineSparkPlug23MinimumVoltage : 32|16@1+ (1,0) [0|64255] "V" Vector__XXX
SG_ EngineSparkPlug24MinimumVoltage : 48|16@1+ (1,0) [0|64255] "V" Vector__XXX

BO_ 2633804798 ESVMIN5: 8 Vector__XXX
SG_ EngineSparkPlug17MinimumVoltage : 0|16@1+ (1,0) [0|64255] "V" Vector__XXX
SG_ EngineSparkPlug18MinimumVoltage : 16|16@1+ (1,0) [0|64255] "V" Vector__XXX
SG_ EngineSparkPlug19MinimumVoltage : 32|16@1+ (1,0) [0|64255] "V" Vector__XXX
SG_ EngineSparkPlug20MinimumVoltage : 48|16@1+ (1,0) [0|64255] "V" Vector__XXX

BO_ 2633805054 ESVMIN4: 8 Vector__XXX
SG_ EngineSparkPlug13MinimumVoltage : 0|16@1+ (1,0) [0|64255] "V" Vector__XXX
SG_ EngineSparkPlug14MinimumVoltage : 16|16@1+ (1,0) [0|64255] "V" Vector__XXX
SG_ EngineSparkPlug15MinimumVoltage : 32|16@1+ (1,0) [0|64255] "V" Vector__XXX
SG_ EngineSparkPlug16MinimumVoltage : 48|16@1+ (1,0) [0|64255] "V" Vector__XXX

BO_ 2633805310 ESVMIN3: 8 Vector__XXX
SG_ EngineSparkPlug9MinimumVoltage : 0|16@1+ (1,0) [0|64255] "V" Vector__XXX
SG_ EngineSparkPlug10MinimumVoltage : 16|16@1+ (1,0) [0|64255] "V" Vector__XXX
SG_ EngineSparkPlug11MinimumVoltage : 32|16@1+ (1,0) [0|64255] "V" Vector__XXX
SG_ EngineSparkPlug12MinimumVoltage : 48|16@1+ (1,0) [0|64255] "V" Vector__XXX

BO_ 2633805566 ESVMIN2: 8 Vector__XXX
SG_ EngineSparkPlug5MinimumVoltage : 0|16@1+ (1,0) [0|64255] "V" Vector__XXX
SG_ EngineSparkPlug6MinimumVoltage : 16|16@1+ (1,0) [0|64255] "V" Vector__XXX
SG_ EngineSparkPlug7MinimumVoltage : 32|16@1+ (1,0) [0|64255] "V" Vector__XXX
SG_ EngineSparkPlug8MinimumVoltage : 48|16@1+ (1,0) [0|64255] "V" Vector__XXX

BO_ 2633805822 ESVMIN1: 8 Vector__XXX
SG_ EngineSparkPlug1MinimumVoltage : 0|16@1+ (1,0) [0|64255] "V" Vector__XXX
SG_ EngineSparkPlug2MinimumVoltage : 16|16@1+ (1,0) [0|64255] "V" Vector__XXX
SG_ EngineSparkPlug3MinimumVoltage : 32|16@1+ (1,0) [0|64255] "V" Vector__XXX
SG_ EngineSparkPlug4MinimumVoltage : 48|16@1+ (1,0) [0|64255] "V" Vector__XXX

BO_ 2633806078 EICMH: 8 Vector__XXX
SG_ EngIgnitionCtrlModule1TimeRemain : 0|32@1+ (0.05,0) [0|210554060.75] "h" Vector__XXX
SG_ EngIgnitionCtrlModule2TimeRemain : 32|32@1+ (0.05,0) [0|210554060.75] "h" Vector__XXX

BO_ 2566697470 ICMSTS: 8 Vector__XXX
SG_ EngIgnitionCtrlModule1Temp : 0|8@1+ (1,-40) [-40|210] "deg C" Vector__XXX
SG_ EngIgnitionCtrlModule2Temp : 8|8@1+ (1,-40) [-40|210] "deg C" Vector__XXX
SG_ EngineIgnitionCtrlModule1State : 16|3@1+ (1,0) [0|7] "" Vector__XXX
SG_ EngineIgnitionCtrlModule2State : 19|3@1+ (1,0) [0|7] "" Vector__XXX

BO_ 2566697726 SPOC1: 64 Vector__XXX
SG_ SwitchedOutput1Current : 0|16@1+ (0.005,0) [0|321.275] "A" Vector__XXX
SG_ SwitchedOutput2Current : 16|16@1+ (0.005,0) [0|321.275] "A" Vector__XXX
SG_ SwitchedOutput3Current : 32|16@1+ (0.005,0) [0|321.275] "A" Vector__XXX
SG_ SwitchedOutput4Current : 48|16@1+ (0.005,0) [0|321.275] "A" Vector__XXX
SG_ SwitchedOutput5Current : 64|16@1+ (0.005,0) [0|321.275] "A" Vector__XXX
SG_ SwitchedOutput6Current : 80|16@1+ (0.005,0) [0|321.275] "A" Vector__XXX
SG_ SwitchedOutput7Current : 96|16@1+ (0.005,0) [0|321.275] "A" Vector__XXX
SG_ SwitchedOutput8Current : 112|16@1+ (0.005,0) [0|321.275] "A" Vector__XXX
SG_ SwitchedOutput9Current : 128|16@1+ (0.005,0) [0|321.275] "A" Vector__XXX
SG_ SwitchedOutput10Current : 144|16@1+ (0.005,0) [0|321.275] "A" Vector__XXX
SG_ SwitchedOutput11Current : 160|16@1+ (0.005,0) [0|321.275] "A" Vector__XXX
SG_ SwitchedOutput12Current : 176|16@1+ (0.005,0) [0|321.275] "A" Vector__XXX
SG_ SwitchedOutput13Current : 192|16@1+ (0.005,0) [0|321.275] "A" Vector__XXX
SG_ SwitchedOutput14Current : 208|16@1+ (0.005,0) [0|321.275] "A" Vector__XXX
SG_ SwitchedOutput15Current : 224|16@1+ (0.005,0) [0|321.275] "A" Vector__XXX
SG_ SwitchedOutput16Current : 240|16@1+ (0.005,0) [0|321.275] "A" Vector__XXX
SG_ SwitchedOutput17Current : 256|16@1+ (0.005,0) [0|321.275] "A" Vector__XXX
SG_ SwitchedOutput18Current : 272|16@1+ (0.005,0) [0|321.275] "A" Vector__XXX
SG_ SwitchedOutput19Current : 288|16@1+ (0.005,0) [0|321.275] "A" Vector__XXX
SG_ SwitchedOutput20Current : 304|16@1+ (0.005,0) [0|321.275] "A" Vector__XXX
SG_ SwitchedOutput21Current : 320|16@1+ (0.005,0) [0|321.275] "A" Vector__XXX
SG_ SwitchedOutput22Current : 336|16@1+ (0.005,0) [0|321.275] "A" Vector__XXX
SG_ SwitchedOutput23Current : 352|16@1+ (0.005,0) [0|321.275] "A" Vector__XXX
SG_ SwitchedOutput24Current : 368|16@1+ (0.005,0) [0|321.275] "A" Vector__XXX
SG_ SwitchedOutput25Current : 384|16@1+ (0.005,0) [0|321.275] "A" Vector__XXX
SG_ SwitchedOutput26Current : 400|16@1+ (0.005,0) [0|321.275] "A" Vector__XXX
SG_ SwitchedOutput27Current : 416|16@1+ (0.005,0) [0|321.275] "A" Vector__XXX
SG_ SwitchedOutput28Current : 432|16@1+ (0.005,0) [0|321.275] "A" Vector__XXX
SG_ SwitchedOutput29Current : 448|16@1+ (0.005,0) [0|321.275] "A" Vector__XXX
SG_ SwitchedOutput30Current : 464|16@1+ (0.005,0) [0|321.275] "A" Vector__XXX
SG_ SwitchedOutput31Current : 480|16@1+ (0.005,0) [0|321.275] "A" Vector__XXX
SG_ SwitchedOutput32Current : 496|16@1+ (0.005,0) [0|321.275] "A" Vector__XXX

BO_ 2566697982 FPOC: 64 Vector__XXX
SG_ FusedOutput1Current : 0|16@1+ (0.005,0) [0|321.275] "A" Vector__XXX
SG_ FusedOutput2Current : 16|16@1+ (0.005,0) [0|321.275] "A" Vector__XXX
SG_ FusedOutput3Current : 32|16@1+ (0.005,0) [0|321.275] "A" Vector__XXX
SG_ FusedOutput4Current : 48|16@1+ (0.005,0) [0|321.275] "A" Vector__XXX
SG_ FusedOutput5Current : 64|16@1+ (0.005,0) [0|321.275] "A" Vector__XXX
SG_ FusedOutput6Current : 80|16@1+ (0.005,0) [0|321.275] "A" Vector__XXX
SG_ FusedOutput7Current : 96|16@1+ (0.005,0) [0|321.275] "A" Vector__XXX
SG_ FusedOutput8Current : 112|16@1+ (0.005,0) [0|321.275] "A" Vector__XXX
SG_ FusedOutput9Current : 128|16@1+ (0.005,0) [0|321.275] "A" Vector__XXX
SG_ FusedOutput10Current : 144|16@1+ (0.005,0) [0|321.275] "A" Vector__XXX
SG_ FusedOutput11Current : 160|16@1+ (0.005,0) [0|321.275] "A" Vector__XXX
SG_ FusedOutput12Current : 176|16@1+ (0.005,0) [0|321.275] "A" Vector__XXX
SG_ FusedOutput13Current : 192|16@1+ (0.005,0) [0|321.275] "A" Vector__XXX
SG_ FusedOutput14Current : 208|16@1+ (0.005,0) [0|321.275] "A" Vector__XXX
SG_ FusedOutput15Current : 224|16@1+ (0.005,0) [0|321.275] "A" Vector__XXX
SG_ FusedOutput16Current : 240|16@1+ (0.005,0) [0|321.275] "A" Vector__XXX
SG_ FusedOutput17Current : 256|16@1+ (0.005,0) [0|321.275] "A" Vector__XXX
SG_ FusedOutput18Current : 272|16@1+ (0.005,0) [0|321.275] "A" Vector__XXX
SG_ FusedOutput19Current : 288|16@1+ (0.005,0) [0|321.275] "A" Vector__XXX
SG_ FusedOutput20Current : 304|16@1+ (0.005,0) [0|321.275] "A" Vector__XXX
SG_ FusedOutput21Current : 320|16@1+ (0.005,0) [0|321.275] "A" Vector__XXX
SG_ FusedOutput22Current : 336|16@1+ (0.005,0) [0|321.275] "A" Vector__XXX
SG_ FusedOutput23Current : 352|16@1+ (0.005,0) [0|321.275] "A" Vector__XXX
SG_ FusedOutput24Current : 368|16@1+ (0.005,0) [0|321.275] "A" Vector__XXX
SG_ FusedOutput25Current : 384|16@1+ (0.005,0) [0|321.275] "A" Vector__XXX
SG_ FusedOutput26Current : 400|16@1+ (0.005,0) [0|321.275] "A" Vector__XXX
SG_ FusedOutput27Current : 416|16@1+ (0.005,0) [0|321.275] "A" Vector__XXX
SG_ FusedOutput28Current : 432|16@1+ (0.005,0) [0|321.275] "A" Vector__XXX
SG_ FusedOutput29Current : 448|16@1+ (0.005,0) [0|321.275] "A" Vector__XXX
SG_ FusedOutput30Current : 464|16@1+ (0.005,0) [0|321.275] "A" Vector__XXX
SG_ FusedOutput31Current : 480|16@1+ (0.005,0) [0|321.275] "A" Vector__XXX
SG_ FusedOutput32Current : 496|16@1+ (0.005,0) [0|321.275] "A" Vector__XXX

BO_ 2566698238 SPOS: 8 Vector__XXX
SG_ SwitchedOutput4 : 0|2@1+ (1,0) [0|3] "" Vector__XXX
SG_ SwitchedOutput3 : 2|2@1+ (1,0) [0|3] "" Vector__XXX
SG_ SwitchedOutput2 : 4|2@1+ (1,0) [0|3] "" Vector__XXX
SG_ SwitchedOutput1 : 6|2@1+ (1,0) [0|3] "" Vector__XXX
SG_ SwitchedOutput8 : 8|2@1+ (1,0) [0|3] "" Vector__XXX
SG_ SwitchedOutput7 : 10|2@1+ (1,0) [0|3] "" Vector__XXX
SG_ SwitchedOutput6 : 12|2@1+ (1,0) [0|3] "" Vector__XXX
SG_ SwitchedOutput5 : 14|2@1+ (1,0) [0|3] "" Vector__XXX
SG_ SwitchedOutput12 : 16|2@1+ (1,0) [0|3] "" Vector__XXX
SG_ SwitchedOutput11 : 18|2@1+ (1,0) [0|3] "" Vector__XXX
SG_ SwitchedOutput10 : 20|2@1+ (1,0) [0|3] "" Vector__XXX
SG_ SwitchedOutput9 : 22|2@1+ (1,0) [0|3] "" Vector__XXX
SG_ SwitchedOutput16 : 24|2@1+ (1,0) [0|3] "" Vector__XXX
SG_ SwitchedOutput15 : 26|2@1+ (1,0) [0|3] "" Vector__XXX
SG_ SwitchedOutput14 : 28|2@1+ (1,0) [0|3] "" Vector__XXX
SG_ SwitchedOutput13 : 30|2@1+ (1,0) [0|3] "" Vector__XXX
SG_ SwitchedOutput20 : 32|2@1+ (1,0) [0|3] "" Vector__XXX
SG_ SwitchedOutput19 : 34|2@1+ (1,0) [0|3] "" Vector__XXX
SG_ SwitchedOutput18 : 36|2@1+ (1,0) [0|3] "" Vector__XXX
SG_ SwitchedOutput17 : 38|2@1+ (1,0) [0|3] "" Vector__XXX
SG_ SwitchedOutput24 : 40|2@1+ (1,0) [0|3] "" Vector__XXX
SG_ SwitchedOutput23 : 42|2@1+ (1,0) [0|3] "" Vector__XXX
SG_ SwitchedOutput22 : 44|2@1+ (1,0) [0|3] "" Vector__XXX
SG_ SwitchedOutput21 : 46|2@1+ (1,0) [0|3] "" Vector__XXX
SG_ SwitchedOutput28 : 48|2@1+ (1,0) [0|3] "" Vector__XXX
SG_ SwitchedOutput27 : 50|2@1+ (1,0) [0|3] "" Vector__XXX
SG_ SwitchedOutput26 : 52|2@1+ (1,0) [0|3] "" Vector__XXX
SG_ SwitchedOutput25 : 54|2@1+ (1,0) [0|3] "" Vector__XXX
SG_ SwitchedOutput32 : 56|2@1+ (1,0) [0|3] "" Vector__XXX
SG_ SwitchedOutput31 : 58|2@1+ (1,0) [0|3] "" Vector__XXX
SG_ SwitchedOutput30 : 60|2@1+ (1,0) [0|3] "" Vector__XXX
SG_ SwitchedOutput29 : 62|2@1+ (1,0) [0|3] "" Vector__XXX

BO_ 2566698494 FPOS: 8 Vector__XXX
SG_ FusedOutput4 : 0|2@1+ (1,0) [0|3] "" Vector__XXX
SG_ FusedOutput3 : 2|2@1+ (1,0) [0|3] "" Vector__XXX
SG_ FusedOutput2 : 4|2@1+ (1,0) [0|3] "" Vector__XXX
SG_ FusedOutput1 : 6|2@1+ (1,0) [0|3] "" Vector__XXX
SG_ FusedOutput8 : 8|2@1+ (1,0) [0|3] "" Vector__XXX
SG_ FusedOutput7 : 10|2@1+ (1,0) [0|3] "" Vector__XXX
SG_ FusedOutput6 : 12|2@1+ (1,0) [0|3] "" Vector__XXX
SG_ FusedOutput5 : 14|2@1+ (1,0) [0|3] "" Vector__XXX
SG_ FusedOutput12 : 16|2@1+ (1,0) [0|3] "" Vector__XXX
SG_ FusedOutput11 : 18|2@1+ (1,0) [0|3] "" Vector__XXX
SG_ FusedOutput10 : 20|2@1+ (1,0) [0|3] "" Vector__XXX
SG_ FusedOutput9 : 22|2@1+ (1,0) [0|3] "" Vector__XXX
SG_ FusedOutput16 : 24|2@1+ (1,0) [0|3] "" Vector__XXX
SG_ FusedOutput15 : 26|2@1+ (1,0) [0|3] "" Vector__XXX
SG_ FusedOutput14 : 28|2@1+ (1,0) [0|3] "" Vector__XXX
SG_ FusedOutput13 : 30|2@1+ (1,0) [0|3] "" Vector__XXX
SG_ FusedOutput20 : 32|2@1+ (1,0) [0|3] "" Vector__XXX
SG_ FusedOutput19 : 34|2@1+ (1,0) [0|3] "" Vector__XXX
SG_ FusedOutput18 : 36|2@1+ (1,0) [0|3] "" Vector__XXX
SG_ FusedOutput17 : 38|2@1+ (1,0) [0|3] "" Vector__XXX
SG_ FusedOutput24 : 40|2@1+ (1,0) [0|3] "" Vector__XXX
SG_ FusedOutput23 : 42|2@1+ (1,0) [0|3] "" Vector__XXX
SG_ FusedOutput22 : 44|2@1+ (1,0) [0|3] "" Vector__XXX
SG_ FusedOutput21 : 46|2@1+ (1,0) [0|3] "" Vector__XXX
SG_ FusedOutput28 : 48|2@1+ (1,0) [0|3] "" Vector__XXX
SG_ FusedOutput27 : 50|2@1+ (1,0) [0|3] "" Vector__XXX
SG_ FusedOutput26 : 52|2@1+ (1,0) [0|3] "" Vector__XXX
SG_ FusedOutput25 : 54|2@1+ (1,0) [0|3] "" Vector__XXX
SG_ FusedOutput32 : 56|2@1+ (1,0) [0|3] "" Vector__XXX
SG_ FusedOutput31 : 58|2@1+ (1,0) [0|3] "" Vector__XXX
SG_ FusedOutput30 : 60|2@1+ (1,0) [0|3] "" Vector__XXX
SG_ FusedOutput29 : 62|2@1+ (1,0) [0|3] "" Vector__XXX

BO_ 2566698750 VEP5: 8 Vector__XXX
SG_ SLIBatteryPackStateOfCharge : 0|16@1+ (0.0025,0) [0|160.6375] "%" Vector__XXX
SG_ SLIBatteryPackCapacity : 16|16@1+ (1,0) [0|64255] "Ah" Vector__XXX
SG_ SLIBatteryPackHealth : 32|8@1+ (0.5,0) [0|125] "%" Vector__XXX
SG_ SLICrnkngPredictMinBattryVoltage : 40|8@1+ (0.2,0) [0|50] "V" Vector__XXX

BO_ 2566699006 HSS2: 8 Vector__XXX
SG_ HybridBatteryPackRemainingCharge : 0|16@1+ (0.0025,0) [0|160.6375] "%" Vector__XXX
SG_ HybridSysEngStopStrtRemnPrcntage : 16|8@1+ (0.4,0) [0|100] "%" Vector__XXX
SG_ HybridProplsnMdeMaxSpeedSetting : 24|8@1+ (1,0) [0|250] "km/h" Vector__XXX
SG_ HybridPropulsionMdeRemainingDist : 32|16@1+ (0.03125,0) [0|2007.96875] "km" Vector__XXX

BO_ 2566699262 AT2S2: 8 Vector__XXX
SG_ Aft2DslPFTmeToNextActvRegen : 0|32@1+ (1,0) [0|4211081215] "s" Vector__XXX
SG_ Aft2SCRSysTmeSncLastSysCleanEvnt : 32|32@1+ (1,0) [0|4211081215] "s" Vector__XXX

BO_ 2566699518 AT1S2: 8 Vector__XXX
SG_ Aft1DslPFTmeToNextActvRegen : 0|32@1+ (1,0) [0|4211081215] "s" Vector__XXX
SG_ Aft1SCRSysTmeSncLastSysCleanEvnt : 32|32@1+ (1,0) [0|4211081215] "s" Vector__XXX

BO_ 2566699774 A2ECMI: 8 Vector__XXX
SG_ Aft2DslExhstFldCtrlMdulRelayCtrl : 0|2@1+ (1,0) [0|3] "" Vector__XXX
SG_ Aft2DslExhstFldCtrlMdulPwrSupply : 2|2@1+ (1,0) [0|3] "" Vector__XXX
SG_ Aft2DslExhstFldCtrlMdulPwrSuply2 : 4|2@1+ (1,0) [0|3] "" Vector__XXX
SG_ Aft2DslExhstFldCtrlMdulCircBrkr : 6|2@1+ (1,0) [0|3] "" Vector__XXX
SG_ Aft2DslExhstFldCtrlMdul2RelyCtrl : 8|2@1+ (1,0) [0|3] "" Vector__XXX
SG_ Aft2DslExhstFldCtrlMdul2PwrSupp1 : 10|2@1+ (1,0) [0|3] "" Vector__XXX
SG_ Aft2DslExhstFldCtrlMdul2PwrSupp2 : 12|2@1+ (1,0) [0|3] "" Vector__XXX

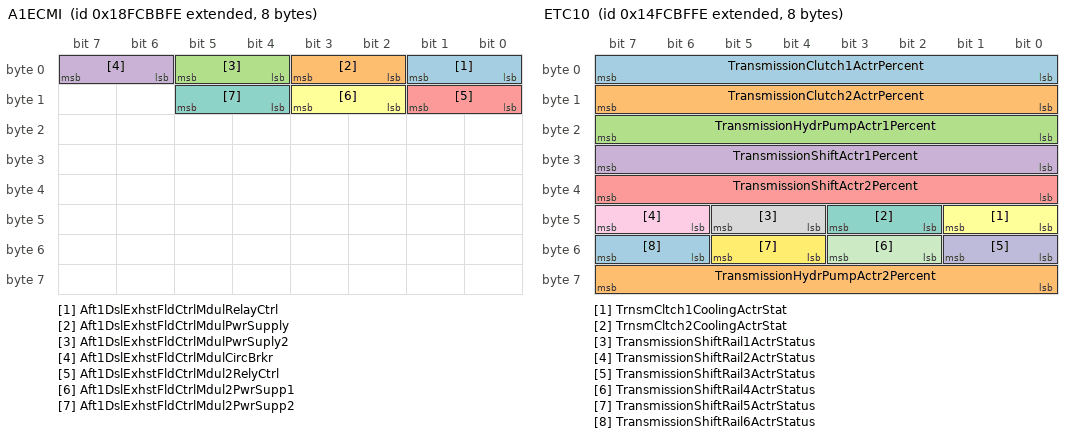
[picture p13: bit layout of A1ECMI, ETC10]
BO_ 2566700030 A1ECMI: 8 Vector__XXX
SG_ Aft1DslExhstFldCtrlMdulRelayCtrl : 0|2@1+ (1,0) [0|3] "" Vector__XXX
SG_ Aft1DslExhstFldCtrlMdulPwrSupply : 2|2@1+ (1,0) [0|3] "" Vector__XXX
SG_ Aft1DslExhstFldCtrlMdulPwrSuply2 : 4|2@1+ (1,0) [0|3] "" Vector__XXX
SG_ Aft1DslExhstFldCtrlMdulCircBrkr : 6|2@1+ (1,0) [0|3] "" Vector__XXX
SG_ Aft1DslExhstFldCtrlMdul2RelyCtrl : 8|2@1+ (1,0) [0|3] "" Vector__XXX
SG_ Aft1DslExhstFldCtrlMdul2PwrSupp1 : 10|2@1+ (1,0) [0|3] "" Vector__XXX
SG_ Aft1DslExhstFldCtrlMdul2PwrSupp2 : 12|2@1+ (1,0) [0|3] "" Vector__XXX

BO_ 2566700286 A2SCRSI2: 8 Vector__XXX
SG_ Aftrtrtmnt2TotalDslExhstFldUsed : 0|32@1+ (0.5,0) [0|2105540607.5] "l" Vector__XXX

BO_ 2566700542 A1SCRSI2: 8 Vector__XXX
SG_ Aftrtrtmnt1TotalDslExhstFldUsed : 0|32@1+ (0.5,0) [0|2105540607.5] "l" Vector__XXX
SG_ AftrtrtmntTripDieselExhaustFluid : 32|32@1+ (0.05,0) [0|210554060.75] "l" Vector__XXX

BO_ 2365374206 ETC9: 8 Vector__XXX
SG_ DualCltchTrnsmInputShft1Spd : 0|16@1+ (0.125,0) [0|8031.875] "rpm" Vector__XXX
SG_ DualCltchTrnsmInputShft2Spd : 16|16@1+ (0.125,0) [0|8031.875] "rpm" Vector__XXX
SG_ DualCltchTrnsmSelPreSelctionGear : 32|8@1+ (1,-125) [-125|125] "" Vector__XXX
SG_ DualCltchTrnsmCurrPreSlctionGear : 40|8@1+ (1,-125) [-125|125] "" Vector__XXX

BO_ 2499592190 ETC10: 8 Vector__XXX
SG_ TransmissionClutch1ActrPercent : 0|8@1+ (0.4,0) [0|100] "%" Vector__XXX
SG_ TransmissionClutch2ActrPercent : 8|8@1+ (0.4,0) [0|100] "%" Vector__XXX
SG_ TransmissionHydrPumpActr1Percent : 16|8@1+ (0.4,0) [0|100] "%" Vector__XXX
SG_ TransmissionShiftActr1Percent : 24|8@1+ (0.4,0) [0|100] "%" Vector__XXX
SG_ TransmissionShiftActr2Percent : 32|8@1+ (0.4,0) [0|100] "%" Vector__XXX
SG_ TrnsmCltch1CoolingActrStat : 40|2@1+ (1,0) [0|3] "" Vector__XXX
SG_ TrnsmCltch2CoolingActrStat : 42|2@1+ (1,0) [0|3] "" Vector__XXX
SG_ TransmissionShiftRail1ActrStatus : 44|2@1+ (1,0) [0|3] "" Vector__XXX
SG_ TransmissionShiftRail2ActrStatus : 46|2@1+ (1,0) [0|3] "" Vector__XXX
SG_ TransmissionShiftRail3ActrStatus : 48|2@1+ (1,0) [0|3] "" Vector__XXX
SG_ TransmissionShiftRail4ActrStatus : 50|2@1+ (1,0) [0|3] "" Vector__XXX
SG_ TransmissionShiftRail5ActrStatus : 52|2@1+ (1,0) [0|3] "" Vector__XXX
SG_ TransmissionShiftRail6ActrStatus : 54|2@1+ (1,0) [0|3] "" Vector__XXX
SG_ TransmissionHydrPumpActr2Percent : 56|8@1+ (0.4,0) [0|100] "%" Vector__XXX

BO_ 2499592446 ETC11: 8 Vector__XXX
SG_ TransmissionShiftRail1Position : 0|8@1+ (0.4,0) [0|100] "%" Vector__XXX
SG_ TransmissionShiftRail2Position : 8|8@1+ (0.4,0) [0|100] "%" Vector__XXX
SG_ TransmissionShiftRail3Position : 16|8@1+ (0.4,0) [0|100] "%" Vector__XXX
SG_ TransmissionShiftRail4Position : 24|8@1+ (0.4,0) [0|100] "%" Vector__XXX
SG_ TransmissionShiftRail5Position : 32|8@1+ (0.4,0) [0|100] "%" Vector__XXX
SG_ TransmissionShiftRail6Position : 40|8@1+ (0.4,0) [0|100] "%" Vector__XXX

BO_ 2566701566 TRF3: 8 Vector__XXX
SG_ TransmissionClutch2Pressure : 0|8@1+ (16,0) [0|4000] "kPa" Vector__XXX
SG_ TrnsmOilTransmissionCoolOtltTemp : 8|8@1+ (1,-40) [-40|210] "deg C" Vector__XXX

BO_ 2566701822 HSS1: 8 Vector__XXX
SG_ HybridSystemWarningIndicator : 0|2@1+ (1,0) [0|3] "" Vector__XXX
SG_ HybridSystemOverheatIndicator : 2|2@1+ (1,0) [0|3] "" Vector__XXX
SG_ HybridSystemStopIndicator : 4|2@1+ (1,0) [0|3] "" Vector__XXX
SG_ HybridSystemOBDRelatedDTCStatus : 6|2@1+ (1,0) [0|3] "" Vector__XXX
SG_ PropulsionSystemActive : 8|2@1+ (1,0) [0|3] "" Vector__XXX
SG_ HybridSystemEngineAssistStatus : 10|2@1+ (1,0) [0|3] "" Vector__XXX
SG_ HybridSystemServiceIndicator : 12|2@1+ (1,0) [0|3] "" Vector__XXX
SG_ HybridSystemMtrOverspeedIndictr : 14|2@1+ (1,0) [0|3] "" Vector__XXX
SG_ HybridSysMtrOverspdAudibleAlarm : 16|2@1+ (1,0) [0|3] "" Vector__XXX
SG_ HybridSysElectricAltrntrIndictr : 18|2@1+ (1,0) [0|3] "" Vector__XXX
SG_ HybridSystemRegativeBrkngIndictr : 20|2@1+ (1,0) [0|3] "" Vector__XXX
SG_ HybridSystemInitIndictr : 22|2@1+ (1,0) [0|3] "" Vector__XXX
SG_ HybridSysHghVltgExposureIndictr : 24|2@1+ (1,0) [0|3] "" Vector__XXX
SG_ StoredEnergySourceOnlyModeAllwd : 26|2@1+ (1,0) [0|3] "" Vector__XXX
SG_ StoredEnergySrcIncreasngMdeAllwd : 28|2@1+ (1,0) [0|3] "" Vector__XXX
SG_ StoredEnergySourceLevel : 32|8@1+ (0.4,0) [0|100] "%" Vector__XXX
SG_ HybridPropulsionModeStatus : 40|4@1+ (1,0) [0|15] "" Vector__XXX
SG_ HybridProplsnMdeTransitionStatus : 44|4@1+ (1,0) [0|15] "" Vector__XXX
SG_ ExtEnergySourceConnectnStatus : 48|4@1+ (1,0) [0|15] "" Vector__XXX
SG_ HybridSystemProplsnDisablStatus : 52|2@1+ (1,0) [0|3] "" Vector__XXX

BO_ 2566702078 GFI4: 8 Vector__XXX
SG_ SupplyGasMethanePercentage : 0|16@1+ (0.0025,0) [0|160.6375] "%" Vector__XXX

BO_ 2566702334 A2SCREGT2: 8 Vector__XXX
SG_ Aftrtrtmnt2SCRIntrmedTemperature : 0|16@1+ (0.03125,-273) [-273|1734.96875] "deg C" Vector__XXX
SG_ Aft2SCRIntrmedTempPrelimFMI : 16|5@1+ (1,0) [0|31] "" Vector__XXX

BO_ 2566702590 A1SCREGT2: 8 Vector__XXX
SG_ Aftrtrtmnt1SCRIntrmedTemperature : 0|16@1+ (0.03125,-273) [-273|1734.96875] "deg C" Vector__XXX
SG_ Aft1SCRIntrmedTempPrelimFMI : 16|5@1+ (1,0) [0|31] "" Vector__XXX

BO_ 2566702846 DM57: 1 Vector__XXX
SG_ EngineOBDWarmUpSequence : 0|2@1+ (1,0) [0|3] "" Vector__XXX

BO_ 2566703102 DM56: 200 Vector__XXX
SG_ ModelYear : 7|64@0+ (1,0) [0|0] "ASCII" Vector__XXX
SG_ CertificationEngineFamilyName : 7|1600@0+ (1,0) [0|0] "ASCII" Vector__XXX

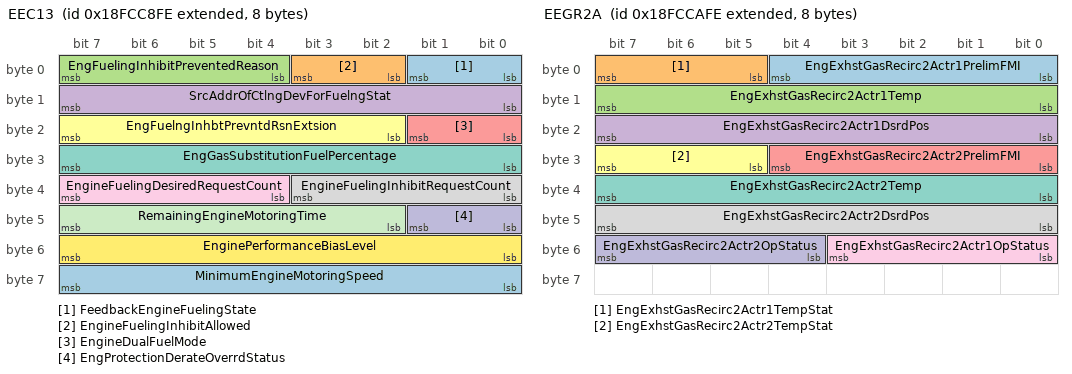
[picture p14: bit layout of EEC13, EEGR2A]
BO_ 2566703358 EEC13: 8 Vector__XXX
SG_ FeedbackEngineFuelingState : 0|2@1+ (1,0) [0|3] "" Vector__XXX
SG_ EngineFuelingInhibitAllowed : 2|2@1+ (1,0) [0|3] "" Vector__XXX
SG_ EngFuelingInhibitPreventedReason : 4|4@1+ (1,0) [0|15] "" Vector__XXX
SG_ SrcAddrOfCtlngDevForFuelngStat : 8|8@1+ (1,0) [0|255] "" Vector__XXX
SG_ EngineDualFuelMode : 16|2@1+ (1,0) [0|3] "" Vector__XXX
SG_ EngFuelngInhbtPrevntdRsnExtsion : 18|6@1+ (1,0) [0|63] "" Vector__XXX
SG_ EngGasSubstitutionFuelPercentage : 24|8@1+ (0.5,0) [0|125] "%" Vector__XXX
SG_ EngineFuelingInhibitRequestCount : 32|4@1+ (1,0) [0|15] "" Vector__XXX
SG_ EngineFuelingDesiredRequestCount : 36|4@1+ (1,0) [0|15] "" Vector__XXX
SG_ EngProtectionDerateOverrdStatus : 40|2@1+ (1,0) [0|3] "" Vector__XXX
SG_ RemainingEngineMotoringTime : 42|6@1+ (1,0) [0|58] "s" Vector__XXX
SG_ EnginePerformanceBiasLevel : 48|8@1+ (0.4,0) [0|100] "%" Vector__XXX
SG_ MinimumEngineMotoringSpeed : 56|8@1+ (10,0) [0|2500] "rpm" Vector__XXX

BO_ 2566703614 EF_TVI2: 8 Vector__XXX
SG_ EngineThrottleValve1Temperature : 0|8@1+ (1,-40) [-40|210] "deg C" Vector__XXX
SG_ EngineThrottleValve2Temperature : 8|8@1+ (1,-40) [-40|210] "deg C" Vector__XXX
SG_ EngineFuelValve1Temperature : 16|8@1+ (1,-40) [-40|210] "deg C" Vector__XXX
SG_ EngineFuelValve2Temperature : 24|8@1+ (1,-40) [-40|210] "deg C" Vector__XXX
SG_ EngTurboWastegateActr2Temp : 32|8@1+ (1,-40) [-40|210] "deg C" Vector__XXX
SG_ EngFuelRackFuelSupplyTemperature : 40|8@1+ (1,-40) [-40|210] "deg C" Vector__XXX
SG_ EngineThrottleValve1Position2 : 48|8@1+ (0.4,0) [0|100] "%" Vector__XXX

BO_ 2566703870 EEGR2A: 8 Vector__XXX
SG_ EngExhstGasRecirc2Actr1PrelimFMI : 0|5@1+ (1,0) [0|31] "" Vector__XXX
SG_ EngExhstGasRecirc2Actr1TempStat : 5|3@1+ (1,0) [0|7] "" Vector__XXX
SG_ EngExhstGasRecirc2Actr1Temp : 8|8@1+ (1,-40) [-40|210] "deg C" Vector__XXX
SG_ EngExhstGasRecirc2Actr1DsrdPos : 16|8@1+ (0.4,0) [0|100] "%" Vector__XXX
SG_ EngExhstGasRecirc2Actr2PrelimFMI : 24|5@1+ (1,0) [0|31] "" Vector__XXX
SG_ EngExhstGasRecirc2Actr2TempStat : 29|3@1+ (1,0) [0|7] "" Vector__XXX
SG_ EngExhstGasRecirc2Actr2Temp : 32|8@1+ (1,-40) [-40|210] "deg C" Vector__XXX
SG_ EngExhstGasRecirc2Actr2DsrdPos : 40|8@1+ (0.4,0) [0|100] "%" Vector__XXX
SG_ EngExhstGasRecirc2Actr1OpStatus : 48|4@1+ (1,0) [0|15] "" Vector__XXX
SG_ EngExhstGasRecirc2Actr2OpStatus : 52|4@1+ (1,0) [0|15] "" Vector__XXX

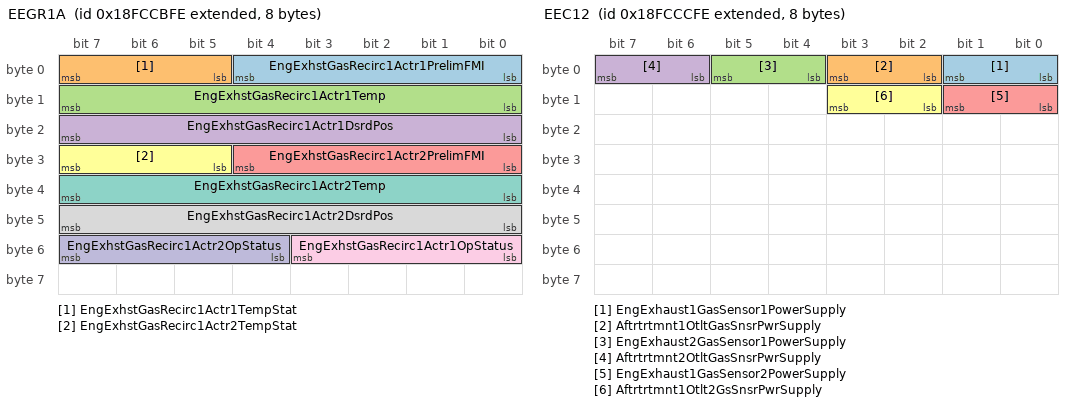
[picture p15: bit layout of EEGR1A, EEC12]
BO_ 2566704126 EEGR1A: 8 Vector__XXX
SG_ EngExhstGasRecirc1Actr1PrelimFMI : 0|5@1+ (1,0) [0|31] "" Vector__XXX
SG_ EngExhstGasRecirc1Actr1TempStat : 5|3@1+ (1,0) [0|7] "" Vector__XXX
SG_ EngExhstGasRecirc1Actr1Temp : 8|8@1+ (1,-40) [-40|210] "deg C" Vector__XXX
SG_ EngExhstGasRecirc1Actr1DsrdPos : 16|8@1+ (0.4,0) [0|100] "%" Vector__XXX
SG_ EngExhstGasRecirc1Actr2PrelimFMI : 24|5@1+ (1,0) [0|31] "" Vector__XXX
SG_ EngExhstGasRecirc1Actr2TempStat : 29|3@1+ (1,0) [0|7] "" Vector__XXX
SG_ EngExhstGasRecirc1Actr2Temp : 32|8@1+ (1,-40) [-40|210] "deg C" Vector__XXX
SG_ EngExhstGasRecirc1Actr2DsrdPos : 40|8@1+ (0.4,0) [0|100] "%" Vector__XXX
SG_ EngExhstGasRecirc1Actr1OpStatus : 48|4@1+ (1,0) [0|15] "" Vector__XXX
SG_ EngExhstGasRecirc1Actr2OpStatus : 52|4@1+ (1,0) [0|15] "" Vector__XXX

BO_ 2566704382 EEC12: 8 Vector__XXX
SG_ EngExhaust1GasSensor1PowerSupply : 0|2@1+ (1,0) [0|3] "" Vector__XXX
SG_ Aftrtrtmnt1OtltGasSnsrPwrSupply : 2|2@1+ (1,0) [0|3] "" Vector__XXX
SG_ EngExhaust2GasSensor1PowerSupply : 4|2@1+ (1,0) [0|3] "" Vector__XXX
SG_ Aftrtrtmnt2OtltGasSnsrPwrSupply : 6|2@1+ (1,0) [0|3] "" Vector__XXX
SG_ EngExhaust1GasSensor2PowerSupply : 8|2@1+ (1,0) [0|3] "" Vector__XXX
SG_ Aftrtrtmnt1Otlt2GsSnsrPwrSupply : 10|2@1+ (1,0) [0|3] "" Vector__XXX

BO_ 2566704638 DSS: 0 Vector__XXX

BO_ 2566704894 DSC: 0 Vector__XXX

BO_ 2566705150 NSSR: 8 Vector__XXX
SG_ Aft1OtltNOxSnsrSelfDiagssTrigger : 0|4@1+ (1,0) [0|15] "" Vector__XXX
SG_ EngExhst1IntkNOxSnsrSelfDiagTrg : 4|4@1+ (1,0) [0|15] "" Vector__XXX
SG_ Aft2OtltNOxSnsrSelfDiagssTrigger : 8|4@1+ (1,0) [0|15] "" Vector__XXX
SG_ EngExhst2IntkNOxSnsrSelfDiagTrg : 12|4@1+ (1,0) [0|15] "" Vector__XXX

BO_ 2566705406 EPSI: 8 Vector__XXX
SG_ Aftertreatment1ParticulateSensor : 0|16@1+ (0.0125,0) [0|803.1875] "mg/m^3" Vector__XXX
SG_ Aftertreatment2ParticulateSensor : 16|16@1+ (0.0125,0) [0|803.1875] "mg/m^3" Vector__XXX
SG_ Aftrtrtmnt1ParticulateSensorCurr : 32|16@1+ (0.00390625,0) [0|250.99609375] "µA" Vector__XXX

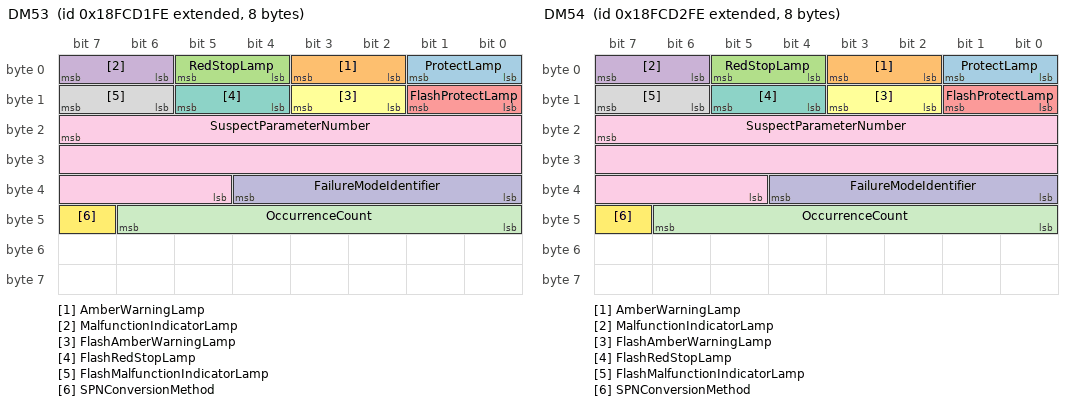
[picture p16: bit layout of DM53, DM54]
BO_ 2566705662 DM53: 8 Vector__XXX
SG_ ProtectLamp : 0|2@1+ (1,0) [0|3] "" Vector__XXX
SG_ AmberWarningLamp : 2|2@1+ (1,0) [0|3] "" Vector__XXX
SG_ RedStopLamp : 4|2@1+ (1,0) [0|3] "" Vector__XXX
SG_ MalfunctionIndicatorLamp : 6|2@1+ (1,0) [0|3] "" Vector__XXX
SG_ FlashProtectLamp : 8|2@1+ (1,0) [0|3] "" Vector__XXX
SG_ FlashAmberWarningLamp : 10|2@1+ (1,0) [0|3] "" Vector__XXX
SG_ FlashRedStopLamp : 12|2@1+ (1,0) [0|3] "" Vector__XXX
SG_ FlashMalfunctionIndicatorLamp : 14|2@1+ (1,0) [0|3] "" Vector__XXX
SG_ SuspectParameterNumber : 23|19@0+ (1,0) [0|524287] "" Vector__XXX
SG_ FailureModeIdentifier : 32|5@1+ (1,0) [0|31] "" Vector__XXX
SG_ OccurrenceCount : 40|7@1+ (1,0) [0|127] "" Vector__XXX
SG_ SPNConversionMethod : 47|1@1+ (1,0) [0|1] "" Vector__XXX

BO_ 2566705918 DM54: 8 Vector__XXX
SG_ ProtectLamp : 0|2@1+ (1,0) [0|3] "" Vector__XXX
SG_ AmberWarningLamp : 2|2@1+ (1,0) [0|3] "" Vector__XXX
SG_ RedStopLamp : 4|2@1+ (1,0) [0|3] "" Vector__XXX
SG_ MalfunctionIndicatorLamp : 6|2@1+ (1,0) [0|3] "" Vector__XXX
SG_ FlashProtectLamp : 8|2@1+ (1,0) [0|3] "" Vector__XXX
SG_ FlashAmberWarningLamp : 10|2@1+ (1,0) [0|3] "" Vector__XXX
SG_ FlashRedStopLamp : 12|2@1+ (1,0) [0|3] "" Vector__XXX
SG_ FlashMalfunctionIndicatorLamp : 14|2@1+ (1,0) [0|3] "" Vector__XXX
SG_ SuspectParameterNumber : 23|19@0+ (1,0) [0|524287] "" Vector__XXX
SG_ FailureModeIdentifier : 32|5@1+ (1,0) [0|31] "" Vector__XXX
SG_ OccurrenceCount : 40|7@1+ (1,0) [0|127] "" Vector__XXX
SG_ SPNConversionMethod : 47|1@1+ (1,0) [0|1] "" Vector__XXX

BO_ 2566706174 DM55: 0 Vector__XXX

BO_ 2566706430 XCP_ID: 0 Vector__XXX

BO_ 2566706686 AT1P1I: 8 Vector__XXX
SG_ Aftrtrtmnt1DslExhstFldPumpHeater : 0|8@1+ (0.4,0) [0|100] "%" Vector__XXX
SG_ Aftrtrtmnt1DslExhstFldPmp2MtrSpd : 8|16@1+ (0.5,0) [0|32127.5] "rpm" Vector__XXX
SG_ Aft1DslExhstFldDsngUnit1HtrRely : 24|2@1+ (1,0) [0|3] "" Vector__XXX
SG_ Aftrtrtmnt1DslExhstFldPmpPwrSupp : 26|2@1+ (1,0) [0|3] "" Vector__XXX

BO_ 2566706942 AT1DPF2S5: 8 Vector__XXX
SG_ Aft1DslPF2SootSnsrAnalyFreq3 : 0|16@1+ (0.1,0) [0|6425.5] "MHz" Vector__XXX
SG_ Aft1DslPF2SootSnsrFreq3SootSig : 16|16@1+ (0.0025,0) [0|160.6375] "%" Vector__XXX
SG_ Aft1DslPF2SootSnsrAnalyFreq4 : 32|16@1+ (0.1,0) [0|6425.5] "MHz" Vector__XXX
SG_ Aft1DslPF2SootSnsrFreq4SootSig : 48|16@1+ (0.0025,0) [0|160.6375] "%" Vector__XXX

BO_ 2566707198 AT1DPF2S4: 8 Vector__XXX
SG_ Aft1DslPF2SootSnsrAnalyFreq1 : 0|16@1+ (0.1,0) [0|6425.5] "MHz" Vector__XXX
SG_ Aft1DslPF2SootSnsrFreq1SootSig : 16|16@1+ (0.0025,0) [0|160.6375] "%" Vector__XXX
SG_ Aft1DslPF2SootSnsrAnalyFreq2 : 32|16@1+ (0.1,0) [0|6425.5] "MHz" Vector__XXX
SG_ Aft1DslPF2SootSnsrFreq2SootSig : 48|16@1+ (0.0025,0) [0|160.6375] "%" Vector__XXX

BO_ 2566707454 AT1DPF2S3: 8 Vector__XXX
SG_ Aft1DslPF2SootSnsrAnalyRqFreq1 : 0|16@1+ (0.1,0) [0|6425.5] "MHz" Vector__XXX
SG_ Aft1DslPF2SootSnsrAnalyRqFreq2 : 16|16@1+ (0.1,0) [0|6425.5] "MHz" Vector__XXX
SG_ Aft1DslPF2SootSnsrAnalyRqFreq3 : 32|16@1+ (0.1,0) [0|6425.5] "MHz" Vector__XXX
SG_ Aft1DslPF2SootSnsrAnalyRqFreq4 : 48|16@1+ (0.1,0) [0|6425.5] "MHz" Vector__XXX

BO_ 2566707710 AT1DPF1S5: 8 Vector__XXX
SG_ Aft1DslPF1SootSnsrAnalyFreq3 : 0|16@1+ (0.1,0) [0|6425.5] "MHz" Vector__XXX
SG_ Aft1DslPF1SootSnsrFreq3SootSig : 16|16@1+ (0.0025,0) [0|160.6375] "%" Vector__XXX
SG_ Aft1DslPF1SootSnsrAnalyFreq4 : 32|16@1+ (0.1,0) [0|6425.5] "MHz" Vector__XXX
SG_ Aft1DslPF1SootSnsrFreq4SootSig : 48|16@1+ (0.0025,0) [0|160.6375] "%" Vector__XXX

BO_ 2566707966 AT1DPF1S4: 8 Vector__XXX
SG_ Aft1DslPF1SootSnsrAnalyFreq1 : 0|16@1+ (0.1,0) [0|6425.5] "MHz" Vector__XXX
SG_ Aft1DslPF1SootSnsrFreq1SootSig : 16|16@1+ (0.0025,0) [0|160.6375] "%" Vector__XXX
SG_ Aft1DslPF1SootSnsrAnalyFreq2 : 32|16@1+ (0.1,0) [0|6425.5] "MHz" Vector__XXX
SG_ Aft1DslPF1SootSnsrFreq2SootSig : 48|16@1+ (0.0025,0) [0|160.6375] "%" Vector__XXX

BO_ 2566708222 AT1DPF1S3: 8 Vector__XXX
SG_ Aft1DslPF1SootSnsrAnalyRqFreq1 : 0|16@1+ (0.1,0) [0|6425.5] "MHz" Vector__XXX
SG_ Aft1DslPF1SootSnsrAnalyRqFreq2 : 16|16@1+ (0.1,0) [0|6425.5] "MHz" Vector__XXX
SG_ Aft1DslPF1SootSnsrAnalyRqFreq3 : 32|16@1+ (0.1,0) [0|6425.5] "MHz" Vector__XXX
SG_ Aft1DslPF1SootSnsrAnalyRqFreq4 : 48|16@1+ (0.1,0) [0|6425.5] "MHz" Vector__XXX

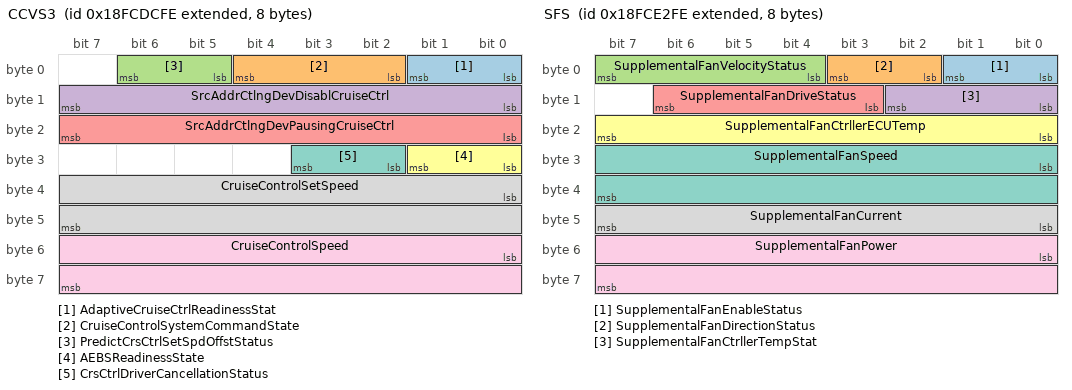
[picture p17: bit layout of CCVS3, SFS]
BO_ 2566708478 CCVS3: 8 Vector__XXX
SG_ AdaptiveCruiseCtrlReadinessStat : 0|2@1+ (1,0) [0|3] "" Vector__XXX
SG_ CruiseControlSystemCommandState : 2|3@1+ (1,0) [0|7] "" Vector__XXX
SG_ PredictCrsCtrlSetSpdOffstStatus : 5|2@1+ (1,0) [0|3] "" Vector__XXX
SG_ SrcAddrCtlngDevDisablCruiseCtrl : 8|8@1+ (1,0) [0|255] "" Vector__XXX
SG_ SrcAddrCtlngDevPausingCruiseCtrl : 16|8@1+ (1,0) [0|255] "" Vector__XXX
SG_ AEBSReadinessState : 24|2@1+ (1,0) [0|3] "" Vector__XXX
SG_ CrsCtrlDriverCancellationStatus : 26|2@1+ (1,0) [0|3] "" Vector__XXX
SG_ CruiseControlSetSpeed : 32|16@1+ (0.00390625,0) [0|250.996] "km/h" Vector__XXX
SG_ CruiseControlSpeed : 48|16@1+ (0.00390625,0) [0|250.996] "km/h" Vector__XXX

BO_ 2566708734 AT2AC3: 8 Vector__XXX
SG_ Aftrtrtmnt2SecondaryAirAbsPress : 0|16@1+ (0.1,0) [0|6425.5] "kPa" Vector__XXX

BO_ 2566708990 AT1AC3: 8 Vector__XXX
SG_ Aftrtrtmnt1SecondaryAirAbsPress : 0|16@1+ (0.1,0) [0|6425.5] "kPa" Vector__XXX
SG_ OprtrIndcOverrdRenewalRequired : 16|2@1+ (1,0) [0|3] "" Vector__XXX

BO_ 2566709246 EFL_P12: 8 Vector__XXX
SG_ EngineFuelDeliveryAbsPressure : 0|8@1+ (4,0) [0|1000] "kPa" Vector__XXX
SG_ EngFilteredFuelDeliveryPressure : 8|8@1+ (4,0) [0|1000] "kPa" Vector__XXX
SG_ EngFilteredFuelDeliveryAbsPress : 16|8@1+ (4,0) [0|1000] "kPa" Vector__XXX
SG_ EngineFuelFilterDegradation : 24|8@1+ (1,0) [0|250] "%" Vector__XXX
SG_ EngineFuelReturnPressure : 32|8@1+ (1.64,-7) [-7|403] "kPa" Vector__XXX
SG_ EngineThrottleValve2DiffPressure : 40|16@1+ (0.1,0) [0|6425.5] "kPa" Vector__XXX
SG_ EngFuelSupplyPumpIntkAbsPressure : 56|8@1+ (5,0) [0|1250] "kPa" Vector__XXX

BO_ 2566709502 DPFC2: 8 Vector__XXX
SG_ Aft1DslPFIntkTemperatuRstPoint : 0|16@1+ (0.03125,-273) [-273|1734.96875] "deg C" Vector__XXX
SG_ EngineUnburnedFuelPercentage : 16|16@1+ (0.0025,0) [0|160.6375] "%" Vector__XXX
SG_ Aftertreatment1FuelMassRate : 32|16@1+ (0.05,0) [0|3212.75] "g/m" Vector__XXX
SG_ Aftertreatment2FuelMassRate : 48|16@1+ (0.05,0) [0|3212.75] "g/m" Vector__XXX

BO_ 2566709758 LFE2: 8 Vector__XXX
SG_ EngineFuelRate : 0|32@1+ (0.001,0) [0|4211081.215] "l/h" Vector__XXX
SG_ EngineDieselFuelDemandRate : 32|16@1+ (0.05,0) [0|3212.75] "l/h" Vector__XXX

BO_ 2566710014 SFS: 8 Vector__XXX
SG_ SupplementalFanEnableStatus : 0|2@1+ (1,0) [0|3] "" Vector__XXX
SG_ SupplementalFanDirectionStatus : 2|2@1+ (1,0) [0|3] "" Vector__XXX
SG_ SupplementalFanVelocityStatus : 4|4@1+ (1,0) [0|15] "" Vector__XXX
SG_ SupplementalFanCtrllerTempStat : 8|3@1+ (1,0) [0|7] "" Vector__XXX
SG_ SupplementalFanDriveStatus : 11|4@1+ (1,0) [0|15] "" Vector__XXX
SG_ SupplementalFanCtrllerECUTemp : 16|8@1+ (1,-40) [-40|210] "deg C" Vector__XXX
SG_ SupplementalFanSpeed : 24|16@1+ (0.5,0) [0|32127.5] "rpm" Vector__XXX
SG_ SupplementalFanCurrent : 40|8@1+ (1,-125) [-125|125] "A" Vector__XXX
SG_ SupplementalFanPower : 48|16@1+ (0.5,0) [0|32127.5] "W" Vector__XXX

BO_ 2432492542 EBCC: 8 Vector__XXX
SG_ EngTurbocharger1TurbineOtltPress : 0|8@1+ (2,0) [0|500] "kPa" Vector__XXX
SG_ EngTurbo1TurbineDsrdOtltPress : 8|8@1+ (2,0) [0|500] "kPa" Vector__XXX
SG_ EngineExhaustBrakeActrCommand : 16|8@1+ (0.4,0) [0|100] "%" Vector__XXX
SG_ EngTurbocharger2TurbineOtltPress : 24|8@1+ (2,0) [0|500] "kPa" Vector__XXX
SG_ EngTurbo2TurbineDsrdOtltPress : 32|8@1+ (2,0) [0|500] "kPa" Vector__XXX

BO_ 2566710526 EFP: 8 Vector__XXX
SG_ EngineFuelDynamicViscosity : 0|16@1+ (0.015625,0) [0|1003.984375] "Cp" Vector__XXX
SG_ EngineFuelDensity : 16|16@1+ (3.052E-005,0) [0|1.961] "g/cc" Vector__XXX
SG_ EngineFuelDielectricity : 32|16@1+ (0.0001220703125,0) [0|7.844] "" Vector__XXX
SG_ EngineFuelTemperature : 48|16@1+ (0.03125,-273) [-273|1734.96875] "deg C" Vector__XXX

BO_ 2566710782 HOP: 8 Vector__XXX
SG_ HydraulicOilDynamicViscosity : 0|16@1+ (0.015625,0) [0|1003.984375] "Cp" Vector__XXX
SG_ HydraulicOilDensity : 16|16@1+ (3.052E-005,0) [0|1.961] "g/cc" Vector__XXX
SG_ HydrOilRelativeDielectricity : 32|16@1+ (0.0001220703125,0) [0|7.844] "" Vector__XXX
SG_ HydraulicOilTemperature : 48|16@1+ (0.03125,-273) [-273|1734.96875] "deg C" Vector__XXX

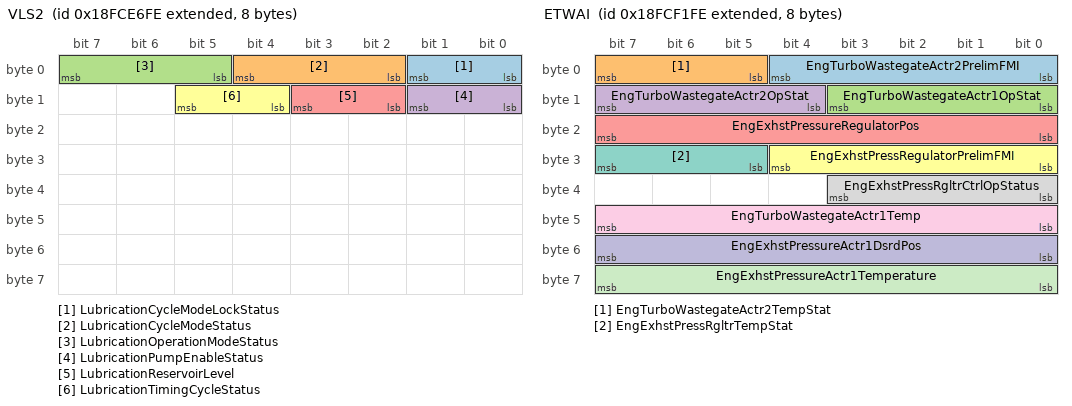
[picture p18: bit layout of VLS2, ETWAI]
BO_ 2566711038 VLS2: 8 Vector__XXX
SG_ LubricationCycleModeLockStatus : 0|2@1+ (1,0) [0|3] "" Vector__XXX
SG_ LubricationCycleModeStatus : 2|3@1+ (1,0) [0|7] "" Vector__XXX
SG_ LubricationOperationModeStatus : 5|3@1+ (1,0) [0|7] "" Vector__XXX
SG_ LubricationPumpEnableStatus : 8|2@1+ (1,0) [0|3] "" Vector__XXX
SG_ LubricationReservoirLevel : 10|2@1+ (1,0) [0|3] "" Vector__XXX
SG_ LubricationTimingCycleStatus : 12|2@1+ (1,0) [0|3] "" Vector__XXX

BO_ 2566711294 EC3: 8 Vector__XXX
SG_ EngFrictionPrcntTrqAtIdl_Point1 : 0|8@1+ (1,-125) [-125|125] "%" Vector__XXX
SG_ EngFrictionPercentTorque_Point2 : 8|8@1+ (1,-125) [-125|125] "%" Vector__XXX
SG_ EngFrictionPercentTorque_Point3 : 16|8@1+ (1,-125) [-125|125] "%" Vector__XXX
SG_ EngFrictionPercentTorque_Point4 : 24|8@1+ (1,-125) [-125|125] "%" Vector__XXX
SG_ EngFrictionPercentTorque_Point5 : 32|8@1+ (1,-125) [-125|125] "%" Vector__XXX
SG_ EngFrictionPercentTorque_Point6 : 40|8@1+ (1,-125) [-125|125] "%" Vector__XXX
SG_ EngFrictionPercentTorque_Point7 : 48|8@1+ (1,-125) [-125|125] "%" Vector__XXX

BO_ 2566711550 IVAC: 8 Vector__XXX
SG_ IntkVlvActSysOilPrs1SolenoidCtrl : 0|2@1+ (1,0) [0|3] "" Vector__XXX
SG_ IntkVlvActSysOilPrs2SolenoidCtrl : 2|2@1+ (1,0) [0|3] "" Vector__XXX

BO_ 2566711806 ARMSWIMC: 8 Vector__XXX
SG_ Armrest1Switch1 : 0|2@1+ (1,0) [0|3] "" Vector__XXX
SG_ Armrest1Switch2 : 2|2@1+ (1,0) [0|3] "" Vector__XXX
SG_ Armrest2Switch1 : 4|2@1+ (1,0) [0|3] "" Vector__XXX
SG_ Armrest2Switch2 : 6|2@1+ (1,0) [0|3] "" Vector__XXX

BO_ 2566712318 AFT2NAI: 8 Vector__XXX
SG_ Aftrtrtmnt2NOxAdsorberRegenStat : 0|2@1+ (1,0) [0|3] "" Vector__XXX
SG_ Aft2NOxAdsorberDesulfationStat : 2|2@1+ (1,0) [0|3] "" Vector__XXX

BO_ 2566712574 AFT1NAI: 8 Vector__XXX
SG_ Aftrtrtmnt1NOxAdsorberRegenStat : 0|2@1+ (1,0) [0|3] "" Vector__XXX
SG_ Aft1NOxAdsorberDesulfationStat : 2|2@1+ (1,0) [0|3] "" Vector__XXX

BO_ 2566712830 AT2WUDOC: 8 Vector__XXX
SG_ Aft2WarmUpDslOxidtnCtlystIntkTmp : 0|16@1+ (0.03125,-273) [-273|1734.96875] "deg C" Vector__XXX
SG_ Aft2WarmUpDslOxidtnCtlystOtltTmp : 16|16@1+ (0.03125,-273) [-273|1734.96875] "deg C" Vector__XXX

BO_ 2499604222 LLRE: 8 Vector__XXX
SG_ BladeElevationDeviationLeft : 0|16@1+ (1,-32000) [-32000|32255] "mm" Vector__XXX
SG_ BladeElevationDeviationRight : 16|16@1+ (1,-32000) [-32000|32255] "mm" Vector__XXX
SG_ BldReferenceElevationOffsetLeft : 32|16@1+ (1,-32000) [-32000|32255] "mm" Vector__XXX
SG_ BldReferenceElevationOffsetRight : 48|16@1+ (1,-32000) [-32000|32255] "mm" Vector__XXX

BO_ 2499604478 EFL_P11: 8 Vector__XXX
SG_ EngExhstGasRecirc1IntkAbsPress : 0|16@1+ (0.1,0) [0|6425.5] "kPa" Vector__XXX
SG_ EngExhstGasRecirc1OtltAbsPress : 16|16@1+ (0.1,0) [0|6425.5] "kPa" Vector__XXX
SG_ EngineOilPressure : 32|16@1+ (0.1,0) [0|6425.5] "kPa" Vector__XXX
SG_ EngineFuelDeliveryPressure : 48|16@1+ (0.1,0) [0|6425.5] "kPa" Vector__XXX

BO_ 2566713598 EFS2: 8 Vector__XXX
SG_ EngFuelFilterIntakeAbsPressure : 0|8@1+ (2,0) [0|500] "kPa" Vector__XXX
SG_ EngineFuelFilterDegradation : 8|8@1+ (1,0) [0|250] "%" Vector__XXX
SG_ FuelTankTransferPump : 16|2@1+ (1,0) [0|3] "" Vector__XXX
SG_ FuelTankTransferPumpPressure : 24|16@1+ (0.1,0) [0|6425.5] "kPa" Vector__XXX
SG_ EngineFuelPumpIntakeOilPressure : 40|8@1+ (4,0) [0|1000] "kPa" Vector__XXX

BO_ 2566713854 ETWAI: 8 Vector__XXX
SG_ EngTurboWastegateActr2PrelimFMI : 0|5@1+ (1,0) [0|31] "" Vector__XXX
SG_ EngTurboWastegateActr2TempStat : 5|3@1+ (1,0) [0|7] "" Vector__XXX
SG_ EngTurboWastegateActr1OpStat : 8|4@1+ (1,0) [0|15] "" Vector__XXX
SG_ EngTurboWastegateActr2OpStat : 12|4@1+ (1,0) [0|15] "" Vector__XXX
SG_ EngExhstPressureRegulatorPos : 16|8@1+ (0.4,0) [0|100] "%" Vector__XXX
SG_ EngExhstPressRegulatorPrelimFMI : 24|5@1+ (1,0) [0|31] "" Vector__XXX
SG_ EngExhstPressRgltrTempStat : 29|3@1+ (1,0) [0|7] "" Vector__XXX
SG_ EngExhstPressRgltrCtrlOpStatus : 32|4@1+ (1,0) [0|15] "" Vector__XXX
SG_ EngTurboWastegateActr1Temp : 40|8@1+ (1,-40) [-40|210] "deg C" Vector__XXX
SG_ EngExhstPressureActr1DsrdPos : 48|8@1+ (0.4,0) [0|100] "%" Vector__XXX
SG_ EngExhstPressureActr1Temperature : 56|8@1+ (1,-40) [-40|210] "deg C" Vector__XXX

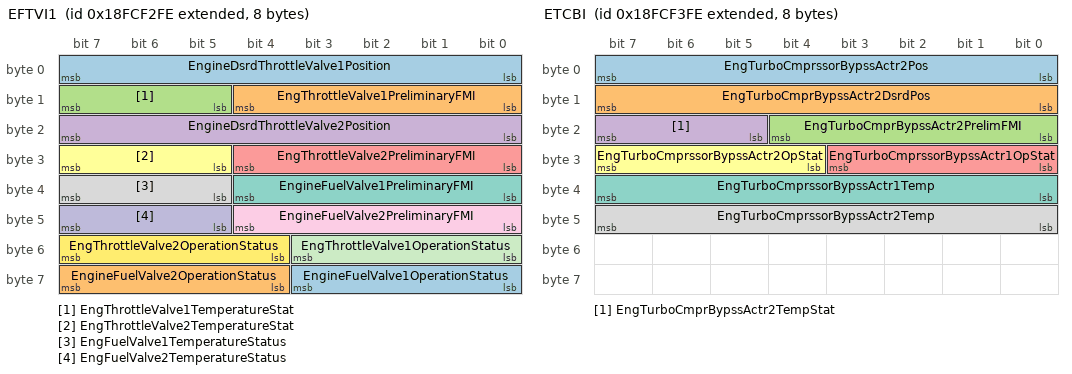
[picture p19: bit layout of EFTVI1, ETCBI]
BO_ 2566714110 EFTVI1: 8 Vector__XXX
SG_ EngineDsrdThrottleValve1Position : 0|8@1+ (0.4,0) [0|100] "%" Vector__XXX
SG_ EngThrottleValve1PreliminaryFMI : 8|5@1+ (1,0) [0|31] "" Vector__XXX
SG_ EngThrottleValve1TemperatureStat : 13|3@1+ (1,0) [0|7] "" Vector__XXX
SG_ EngineDsrdThrottleValve2Position : 16|8@1+ (0.4,0) [0|100] "%" Vector__XXX
SG_ EngThrottleValve2PreliminaryFMI : 24|5@1+ (1,0) [0|31] "" Vector__XXX
SG_ EngThrottleValve2TemperatureStat : 29|3@1+ (1,0) [0|7] "" Vector__XXX
SG_ EngineFuelValve1PreliminaryFMI : 32|5@1+ (1,0) [0|31] "" Vector__XXX
SG_ EngFuelValve1TemperatureStatus : 37|3@1+ (1,0) [0|7] "" Vector__XXX
SG_ EngineFuelValve2PreliminaryFMI : 40|5@1+ (1,0) [0|31] "" Vector__XXX
SG_ EngFuelValve2TemperatureStatus : 45|3@1+ (1,0) [0|7] "" Vector__XXX
SG_ EngThrottleValve1OperationStatus : 48|4@1+ (1,0) [0|15] "" Vector__XXX
SG_ EngThrottleValve2OperationStatus : 52|4@1+ (1,0) [0|15] "" Vector__XXX
SG_ EngineFuelValve1OperationStatus : 56|4@1+ (1,0) [0|15] "" Vector__XXX
SG_ EngineFuelValve2OperationStatus : 60|4@1+ (1,0) [0|15] "" Vector__XXX

BO_ 2566714366 ETCBI: 8 Vector__XXX
SG_ EngTurboCmprssorBypssActr2Pos : 0|8@1+ (0.4,0) [0|100] "%" Vector__XXX
SG_ EngTurboCmprBypssActr2DsrdPos : 8|8@1+ (0.4,0) [0|100] "%" Vector__XXX
SG_ EngTurboCmprBypssActr2PrelimFMI : 16|5@1+ (1,0) [0|31] "" Vector__XXX
SG_ EngTurboCmprBypssActr2TempStat : 21|3@1+ (1,0) [0|7] "" Vector__XXX
SG_ EngTurboCmprssorBypssActr1OpStat : 24|4@1+ (1,0) [0|15] "" Vector__XXX
SG_ EngTurboCmprssorBypssActr2OpStat : 28|4@1+ (1,0) [0|15] "" Vector__XXX
SG_ EngTurboCmprssorBypssActr1Temp : 32|8@1+ (1,-40) [-40|210] "deg C" Vector__XXX
SG_ EngTurboCmprssorBypssActr2Temp : 40|8@1+ (1,-40) [-40|210] "deg C" Vector__XXX

BO_ 2566714622 CAC2: 8 Vector__XXX
SG_ EngChargeAirCool2IntkTemperature : 0|16@1+ (0.03125,-273) [-273|1734.96875] "deg C" Vector__XXX
SG_ EngChargeAirCool2OtltTemperature : 16|16@1+ (0.03125,-273) [-273|1734.96875] "deg C" Vector__XXX
SG_ EngChargeAirCool2AmbientAirTemp : 32|16@1+ (0.03125,-273) [-273|1734.96875] "deg C" Vector__XXX
SG_ EngineChargeAirCooler2Efficiency : 48|8@1+ (0.4,0) [0|100] "%" Vector__XXX

BO_ 2566714878 CAC2P: 8 Vector__XXX
SG_ EngChargeAirCool2PreCoolIntkTemp : 0|16@1+ (0.03125,-273) [-273|1734.96875] "deg C" Vector__XXX
SG_ EngChargeAirCool2PreCoolOtltTemp : 16|16@1+ (0.03125,-273) [-273|1734.96875] "deg C" Vector__XXX
SG_ EngineChargeAirCool2PreCoolEff : 32|8@1+ (0.4,0) [0|100] "%" Vector__XXX

BO_ 2566715134 CAC1: 8 Vector__XXX
SG_ EngChargeAirCool1IntkTemperature : 0|16@1+ (0.03125,-273) [-273|1734.96875] "deg C" Vector__XXX
SG_ EngChargeAirCool1AmbientAirTemp : 16|16@1+ (0.03125,-273) [-273|1734.96875] "deg C" Vector__XXX
SG_ EngineChargeAirCooler1Efficiency : 32|8@1+ (0.4,0) [0|100] "%" Vector__XXX

BO_ 2566715390 CAC1P: 8 Vector__XXX
SG_ EngChargeAirCool1PreCoolIntkTemp : 0|16@1+ (0.03125,-273) [-273|1734.96875] "deg C" Vector__XXX
SG_ EngChargeAirCool1PreCoolOtltTemp : 16|16@1+ (0.03125,-273) [-273|1734.96875] "deg C" Vector__XXX
SG_ EngineChargeAirCool1PreCoolEff : 32|8@1+ (0.4,0) [0|100] "%" Vector__XXX

BO_ 2566715646 DPF2S2: 8 Vector__XXX
SG_ Aftrtrtmnt2DslPFSootSigStdDviat : 0|16@1+ (0.0025,0) [0|160.6375] "%" Vector__XXX
SG_ Aftrtrtmnt2DslPFSootSignalMax : 16|16@1+ (0.0025,0) [0|160.6375] "%" Vector__XXX
SG_ Aftrtrtmnt2DslPFSootSignalMin : 32|16@1+ (0.0025,0) [0|160.6375] "%" Vector__XXX

BO_ 2566715902 DPF1S2: 8 Vector__XXX
SG_ Aftrtrtmnt1DslPFSootSigStdDviat : 0|16@1+ (0.0025,0) [0|160.6375] "%" Vector__XXX
SG_ Aftrtrtmnt1DslPFSootSignalMax : 16|16@1+ (0.0025,0) [0|160.6375] "%" Vector__XXX
SG_ Aftrtrtmnt1DslPFSootSignalMin : 32|16@1+ (0.0025,0) [0|160.6375] "%" Vector__XXX

BO_ 2633825022 EEC11: 8 Vector__XXX
SG_ EngExhstGasRecirc2Valve1Ctrl : 0|16@1+ (0.0025,0) [0|160.6375] "%" Vector__XXX
SG_ EngExhstGasRecirc2Valve2Ctrl : 16|16@1+ (0.0025,0) [0|160.6375] "%" Vector__XXX
SG_ EngExhstGasRecirc2Valve1PosError : 32|16@1+ (0.004,-125) [-125|132.02] "%" Vector__XXX
SG_ EngExhstGasRecirc2Valve2PosError : 48|16@1+ (0.004,-125) [-125|132.02] "%" Vector__XXX

BO_ 2499607550 EMAP: 8 Vector__XXX
SG_ EngExhstMnfldBnk1FlwBalVlvActrPs : 0|16@1+ (0.0025,0) [0|160.6375] "%" Vector__XXX
SG_ EngExhstMnfldBnk2FlwBalVlvActrPs : 16|16@1+ (0.0025,0) [0|160.6375] "%" Vector__XXX

BO_ 2633825534 EMAC: 8 Vector__XXX
SG_ EngExhstMfBnk1FlwBalVlvActrCtrl : 0|16@1+ (0.0025,0) [0|160.6375] "%" Vector__XXX
SG_ EngExhstMfBnk2FlwBalVlvActrCtrl : 16|16@1+ (0.0025,0) [0|160.6375] "%" Vector__XXX

CM_ BO_ 2633752830 "Aftercooler and Oil Cooler Fluids 1";
CM_ BO_ 2633753086 "Diode Temperature 2";
CM_ BO_ 2633753342 "Diode Temperature 1";
CM_ BO_ 2633753598 "Alternator Temperature 2";
CM_ BO_ 2566644990 "Fuel Information 7 (Gaseous)";
CM_ BO_ 2566645246 "High Voltage Energy Storage System Fan Status";
CM_ BO_ 2365318910 "High Voltage Energy Storage System Fan Commands";
CM_ BO_ 2633754622 "SCR Operator Inducement Information 5";
CM_ BO_ 2633754878 "Aftertreatment System Information 2";
CM_ BO_ 2633755134 "Ethernet 1 Connection Information 2";
CM_ BO_ 2633755390 "Ethernet 1 Connection Information 1";
CM_ BO_ 2566646782 "Oil Debris Monitor Counts Ferrous Bins 1 & 2";
CM_ BO_ 2566647038 "Oil Debris Monitor Counts Ferrous Bins 3 & 4";
CM_ BO_ 2566647294 "Oil Debris Monitor Counts Ferrous Bins 5 & 6";
CM_ BO_ 2566647550 "Oil Debris Monitor Counts Non-Ferrous Bins 1 & 2";
CM_ BO_ 2566647806 "Oil Debris Monitor Counts Non-Ferrous Bins 3 & 4";
CM_ BO_ 2566648062 "Oil Debris Monitor Counts Non-Ferrous Bins 5 & 6";
CM_ BO_ 2566648318 "Oil Debris Monitoring System Status";
CM_ BO_ 2365322238 "Cruise Control / Vehicle Speed 5";
CM_ BO_ 2566649086 "Aftertreatment 2 Diesel Oxidation Catalyst 2";
CM_ BO_ 2566649342 "Aftertreatment 1 Diesel Oxidation Catalyst 2";
CM_ BO_ 2566649598 "Vehicle Position 2";
CM_ BO_ 2566649854 "Electrified Accessory Propulsion Motor Coolant Fan 3 Status";
CM_ BO_ 2566650110 "Electrified Accessory Propulsion Motor Coolant Fan 2 Status";
CM_ BO_ 2566650366 "Electrified Accessory Propulsion Motor Coolant Fan 1 Status";
CM_ BO_ 2566650622 "Electrified Accessory Power Electronics Coolant Fan 3 Status";
CM_ BO_ 2566650878 "Electrified Accessory Power Electronics Coolant Fan 2 Status";
CM_ BO_ 2566651134 "Electrified Accessory Power Electronics Coolant Fan 1 Status";
CM_ BO_ 2566651390 "Electrified Accessory Propulsion Motor Oil Pump Status";
CM_ BO_ 2566651646 "Electrified Accessory Propulsion Motor Coolant Pump Status";
CM_ BO_ 2566651902 "Electrified Accessory Power Electronics Coolant Pump Status";
CM_ BO_ 2566652414 "Electrified Accessory Motor Status";
CM_ BO_ 2566652670 "SCR System Information";
CM_ BO_ 2566652926 "Vehicle Electrical Power 14";
CM_ BO_ 2566653182 "Vehicle Electrical Power 13";
CM_ BO_ 2566653438 "Vehicle Electrical Power 12";
CM_ BO_ 2566653694 "Vehicle Electrical Power 11";
CM_ BO_ 2566653950 "Vehicle Electrical Power 10";
CM_ BO_ 2566654206 "Vehicle Electrical Power 9";
CM_ BO_ 2566654462 "Vehicle Electrical Power 8";
CM_ BO_ 2566654718 "Vehicle Electrical Power 7";
CM_ BO_ 2566654974 "Electronic Engine Controller 20";
CM_ BO_ 2633764094 "Evaporative Systems";
CM_ BO_ 2633764350 "Fire Pump Statistics 1";
CM_ BO_ 2566655742 "Primary or Rear Hitch Roll and Pitch Sensitivity";
CM_ BO_ 2566655998 "ISO 11783-7: Secondary or Front Hitch Roll and Pitch Sensitivity";
CM_ BO_ 2566656254 "Ambient Conditions 3";
CM_ BO_ 2566656510 "Total Gaseous Fuel Information";
CM_ BO_ 2499547902 "Cab Door Control";
CM_ BO_ 2499548158 "Door Latch Status";
CM_ BO_ 2499548670 "Vehicle Electrical Power 6";
CM_ BO_ 2499548926 "Payload Temperature 2";
CM_ BO_ 2499549182 "Payload Temperature 1";
CM_ BO_ 2566658302 "Payload System Totals 2";
CM_ BO_ 2566658558 "Payload System Totals 1";
CM_ BO_ 2633769726 "Electronic Engine Controller 19";
CM_ BO_ 2566661118 "Fuel Consumption (Liquid) 2";
CM_ BO_ 2566661374 "Aftertreatment 2 Diesel Exhaust Fluid Tank 1 Information 2";
CM_ BO_ 2566661630 "Aftertreatment 1 Diesel Exhaust Fluid Tank 1 Information 2";
CM_ BO_ 2566661886 "Aftertreatment 2 Diesel Exhaust Fluid Information 2";
CM_ BO_ 2566662142 "Aftertreatment 1 Diesel Exhaust Fluid Information 2";
CM_ BO_ 2566662654 "Forward Lane Image 3";
CM_ BO_ 2566662910 "Operator Inducement Information";
CM_ BO_ 2566663166 "Cruise Control / Vehicle Speed 4";
CM_ BO_ 2566663422 "Brake Caliper Lining Clearance";
CM_ BO_ 2566663678 "Alternate Fuel 5";
CM_ BO_ 2566663934 "Engine Turbocharger Control 3";
CM_ BO_ 2633773054 "Fire Suppression Agent Status";
CM_ BO_ 2633773310 "SCR Operator Inducement Information 4";
CM_ BO_ 2566664702 "Aftertreatment System Information 1";
CM_ BO_ 2499556094 "Aftertreatment 1 Particulate Sensor Information 3";
CM_ BO_ 2499556350 "Engine Fuel Injector Metering Rail Pressure Information 3";
CM_ BO_ 2499556606 "Engine Fuel Injector Metering Rail Pressure Information 2";
CM_ BO_ 2566665726 "Aftertreatment 2 Diesel Exhaust Fluid Pump 1 Information";
CM_ BO_ 2499557118 "Gaseous Fuel Supply Valve Information";
CM_ BO_ 2499557374 "Engine Oil Mist Detection Information 2";
CM_ BO_ 2499557630 "Engine Oil Mist Detection Information 1";
CM_ BO_ 2499557886 "Gaseous Fuel Supply Pressure 2";
CM_ BO_ 2499558142 "Gaseous Fuel Supply Pressure 1";
CM_ BO_ 2566667262 "Engine End Bearing Temperature 3";
CM_ BO_ 2566667518 "Engine End Bearing Temperature 2";
CM_ BO_ 2566667774 "Engine End Bearing Temperature 1";
CM_ BO_ 2566668030 "Heat Exchanger Debris Purge Information";
CM_ BO_ 2566668286 "Engine Turbocharger Control 2";
CM_ BO_ 2566668542 "Engine Hydraulic Fuel 2 Pump Status";
CM_ BO_ 2566668798 "Alternate Fuel 4";
CM_ BO_ 2566669054 "Tire Condition Message 2";
CM_ BO_ 2566669310 "Tire Configuration Status Information";
CM_ BO_ 2566669822 "Tire Wireless Signal Strength Indicator";
CM_ BO_ 2566670078 "Tire Sensor Identification Status";
CM_ BO_ 2566670334 "Monitored Tire Information";
CM_ BO_ 2566670590 "Aftertreatment 2 Historical Information 2";
CM_ BO_ 2566670846 "Aftertreatment 1 Historical Information 2";
CM_ BO_ 2566671102 "SCR System Cleaning";
CM_ BO_ 2566671358 "Electronic Engine Controller 17";
CM_ BO_ 2566671614 "SCR Operator Inducement Information 3";
CM_ BO_ 2566671870 "Aftertreatment 2 SCR Dosing System Information 3";
CM_ BO_ 2566672126 "Aftertreatment 1 SCR Dosing System Information 3";
CM_ BO_ 2566672382 "Payload Weight Sensor Information";
CM_ BO_ 2566672638 "Payload System Status";
CM_ BO_ 2365346302 "Air Suspension Control 7";
CM_ BO_ 2633782014 "Bin Weight and Lift Count";
CM_ BO_ 2566673406 "Engine Gaseous Leakage Information";
CM_ BO_ 2566674174 "SCR Operator Inducement Information 2";
CM_ BO_ 2566674430 "SCR Operator Inducement Information 1";
CM_ BO_ 2566674686 "Turbocharger Information 7";
CM_ BO_ 2365348350 "Engine Load Sharing Information";
CM_ BO_ 2566675966 "High Voltage Energy Storage System Configuration";
CM_ BO_ 2633785086 "High Voltage Energy Storage System History";
CM_ BO_ 2566687742 "Aftertreatment 1 Particulate Sensor Information 2";
CM_ BO_ 2566687998 "Aftertreatment 1 Particulate Sensor Information 1";
CM_ BO_ 2566688254 "ISO 11783-12: Product Identification Information";
CM_ BO_ 2566688510 "ISO 11783-12: Control Function Functionalities";
CM_ BO_ 2432471038 "Alternate Fuel 3";
CM_ BO_ 2499580158 "Engine Fuel Injector Metering Rail Pressure Information 1";
CM_ BO_ 2566689278 "Engine Exhaust NOx";
CM_ BO_ 2566689534 "Air Fuel Ratio";
CM_ BO_ 2566689790 "Gaseous Fuel Pressure 2";
CM_ BO_ 2566690046 "Aftertreatment System Abuse Information";
CM_ BO_ 2365363710 "Engine Cylinder Pressure Monitor Status Information";
CM_ BO_ 2566690558 "Engine Information 2";
CM_ BO_ 2566690814 "Electronic Steering Control 2";
CM_ BO_ 2499582206 "Vehicle Speed Limiter";
CM_ BO_ 2566691326 "Assembly Unit Identification";
CM_ BO_ 2566691582 "Joystick 3 Lamp Status";
CM_ BO_ 2566691838 "Joystick 2 Lamp Status";
CM_ BO_ 2566692094 "Joystick 1 Lamp Status";
CM_ BO_ 2499583486 "Engine Timing Actuator Position Command";
CM_ BO_ 2499583742 "Engine Timing Actuator Position";
CM_ BO_ 2566692862 "Dash Display 2";
CM_ BO_ 2633801982 "Multi-fuel Engine Hours";
CM_ BO_ 2633802238 "Engine Spark Misfire Rate 3";
CM_ BO_ 2633802494 "Engine Spark Misfire Rate 2";
CM_ BO_ 2633802750 "Engine Spark Misfire Rate 1";
CM_ BO_ 2633803006 "Engine Spark Maximum Voltage 6";
CM_ BO_ 2633803262 "Engine Spark Maximum Voltage 5";
CM_ BO_ 2633803518 "Engine Spark Maximum Voltage 4";
CM_ BO_ 2633803774 "Engine Spark Maximum Voltage 3";
CM_ BO_ 2633804030 "Engine Spark Maximum Voltage 2";
CM_ BO_ 2633804286 "Engine Spark Maximum Voltage 1";
CM_ BO_ 2633804542 "Engine Spark Minimum Voltage 6";
CM_ BO_ 2633804798 "Engine Spark Minimum Voltage 5";
CM_ BO_ 2633805054 "Engine Spark Minimum Voltage 4";
CM_ BO_ 2633805310 "Engine Spark Minimum Voltage 3";
CM_ BO_ 2633805566 "Engine Spark Minimum Voltage 2";
CM_ BO_ 2633805822 "Engine Spark Minimum Voltage 1";
CM_ BO_ 2633806078 "Engine Ignition Controller Maintenance Hours";
CM_ BO_ 2566697470 "Engine Ignition Control Module Status";
CM_ BO_ 2566697726 "Switched Power Output Current";
CM_ BO_ 2566697982 "Fused Power Output Current";
CM_ BO_ 2566698238 "Switched Power Output Status";
CM_ BO_ 2566698494 "Fused Power Output Status";
CM_ BO_ 2566698750 "Vehicle Electrical Power 5";
CM_ BO_ 2566699006 "Hybrid System Status 2";
CM_ BO_ 2566699262 "Aftertreatment 2 Service 2";
CM_ BO_ 2566699518 "Aftertreatment 1 Service 2";
CM_ BO_ 2566699774 "Aftertreatment 2 SCR Electronic Control Module Information";
CM_ BO_ 2566700030 "Aftertreatment 1 SCR Electronic Control Module Information";
CM_ BO_ 2566700286 "Aftertreatment 2 SCR Service Information 2";
CM_ BO_ 2566700542 "Aftertreatment 1 SCR Service Information 2";
CM_ BO_ 2365374206 "Electronic Transmission Controller #9";
CM_ BO_ 2499592190 "Electronic Transmission Controller #10";
CM_ BO_ 2499592446 "Electronic Transmission Controller #11";
CM_ BO_ 2566701566 "Transmission Fluids 3";
CM_ BO_ 2566701822 "Hybrid System Status 1";
CM_ BO_ 2566702078 "Fuel Information 4 (Gaseous)";
CM_ BO_ 2566702334 "Aftertreatment 2 SCR Exhaust Gas Temperature 2";
CM_ BO_ 2566702590 "Aftertreatment 1 SCR Exhaust Gas Temperature 2";
CM_ BO_ 2566702846 "OBD Information";
CM_ BO_ 2566703102 "Model Year and Certification Engine Family";
CM_ BO_ 2566703358 "Electronic Engine Controller 13";
CM_ BO_ 2566703614 "Engine Fuel/Throttle Valve Information 2";
CM_ BO_ 2566703870 "Engine Exhaust Gas Recirculation 2 Actuator";
CM_ BO_ 2566704126 "Engine Exhaust Gas Recirculation 1 Actuator";
CM_ BO_ 2566704382 "Electronic Engine Controller 12";
CM_ BO_ 2566704638 "ISO 11783-7: Drive Strategy Status";
CM_ BO_ 2566704894 "ISO 11783-7: Drive Strategy Command";
CM_ BO_ 2566705150 "NOx Sensor Self-Diagnosis Request";
CM_ BO_ 2566705406 "Engine Particulate Sensor Information";
CM_ BO_ 2566705662 "Active Service Only DTCs";
CM_ BO_ 2566705918 "Previously Active Service Only DTCs";
CM_ BO_ 2566706174 "Diagnostic Data Clear/Reset for All Service Only DTCs";
CM_ BO_ 2566706430 "XCP Get Slave ID";
CM_ BO_ 2566706686 "Aftertreatment 1 Diesel Exhaust Fluid Pump 1 Information";
CM_ BO_ 2566706942 "Aftertreatment 1 Diesel Particulate Filter 2 Soot 5";
CM_ BO_ 2566707198 "Aftertreatment 1 Diesel Particulate Filter 2 Soot 4";
CM_ BO_ 2566707454 "Aftertreatment 1 Diesel Particulate Filter 2 Soot 3";
CM_ BO_ 2566707710 "Aftertreatment 1 Diesel Particulate Filter 1 Soot 5";
CM_ BO_ 2566707966 "Aftertreatment 1 Diesel Particulate Filter 1 Soot 4";
CM_ BO_ 2566708222 "Aftertreatment 1 Diesel Particulate Filter 1 Soot 3";
CM_ BO_ 2566708478 "Cruise Control / Vehicle Speed 3";
CM_ BO_ 2566708734 "Aftertreatment 2 Air Control 3";
CM_ BO_ 2566708990 "Aftertreatment 1 Air Control 3";
CM_ BO_ 2566709246 "Engine Fluid Level/Pressure 12";
CM_ BO_ 2566709502 "Diesel Particulate Filter Control 2";
CM_ BO_ 2566709758 "Fuel Economy 2 (Liquid)";
CM_ BO_ 2566710014 "Supplemental Fan Status";
CM_ BO_ 2432492542 "Engine Exhaust Brake Control";
CM_ BO_ 2566710526 "Engine Fuel Properties";
CM_ BO_ 2566710782 "Hydraulic Oil Properties";
CM_ BO_ 2566711038 "Vehicle/Chassis Lubrication System 2";
CM_ BO_ 2566711294 "Engine Configuration 3";
CM_ BO_ 2566711550 "Intake Valve Actuation Control";
CM_ BO_ 2566711806 "Armrest Switch Matrix Commands";
CM_ BO_ 2566712318 "Aftertreatment 2 NOx Adsorber Information";
CM_ BO_ 2566712574 "Aftertreatment 1 NOx Adsorber Information";
CM_ BO_ 2566712830 "Aftertreatment 2 Warm Up Diesel Oxidation Catalyst Information";
CM_ BO_ 2499604222 "Land Leveling System Reference Elevation Data";
CM_ BO_ 2499604478 "Engine Fluid Level/Pressure 11";
CM_ BO_ 2566713598 "Engine Fuel/Lube Systems 2";
CM_ BO_ 2566713854 "Engine Turbocharger Wastegate Actuator and Exhaust Back Pressure Regulator Information";
CM_ BO_ 2566714110 "Engine Fuel/Throttle Valve Information 1";
CM_ BO_ 2566714366 "Engine Turbocharger Compressor Bypass Information";
CM_ BO_ 2566714622 "Charge Air Cooler 2";
CM_ BO_ 2566714878 "Charge Air Cooler 2 Precooler";
CM_ BO_ 2566715134 "Charge Air Cooler 1";
CM_ BO_ 2566715390 "Charge Air Cooler 1 Precooler";
CM_ BO_ 2566715646 "Diesel Particulate Filter 2 Soot 2";
CM_ BO_ 2566715902 "Diesel Particulate Filter 1 Soot 2";
CM_ BO_ 2633825022 "Electronic Engine Controller 11";
CM_ BO_ 2499607550 "Engine Manifold Actuator Position";
CM_ BO_ 2633825534 "Engine Manifold Actuator Control";
BA_DEF_ BO_  "GenMsgCycleTime" INT 0 65535;
BA_DEF_ SG_  "SigType" ENUM "Default","Range","RangeSigned","ASCII","Discrete","Control","ReferencePGN","DTC","StringDelimiter","StringLength","StringLengthControl","MessageCounter","MessageChecksum";
BA_DEF_DEF_  "GenMsgCycleTime" 0;
BA_DEF_DEF_  "SigType" "Default";
BA_ "GenMsgCycleTime" BO_ 2633752830 1000;
BA_ "GenMsgCycleTime" BO_ 2633753086 1000;
BA_ "GenMsgCycleTime" BO_ 2633753342 1000;
BA_ "GenMsgCycleTime" BO_ 2633753598 1000;
BA_ "GenMsgCycleTime" BO_ 2566644990 500;
BA_ "GenMsgCycleTime" BO_ 2566645246 1000;
BA_ "GenMsgCycleTime" BO_ 2365318910 1000;
BA_ "GenMsgCycleTime" BO_ 2633754622 10000;
BA_ "GenMsgCycleTime" BO_ 2566646782 10000;
BA_ "GenMsgCycleTime" BO_ 2566647038 10000;
BA_ "GenMsgCycleTime" BO_ 2566647294 10000;
BA_ "GenMsgCycleTime" BO_ 2566647550 10000;
BA_ "GenMsgCycleTime" BO_ 2566647806 10000;
BA_ "GenMsgCycleTime" BO_ 2566648062 10000;
BA_ "GenMsgCycleTime" BO_ 2566648318 30000;
BA_ "GenMsgCycleTime" BO_ 2365322238 100;
BA_ "GenMsgCycleTime" BO_ 2566649086 500;
BA_ "GenMsgCycleTime" BO_ 2566649342 500;
BA_ "GenMsgCycleTime" BO_ 2566649598 5000;
BA_ "GenMsgCycleTime" BO_ 2566649854 1000;
BA_ "GenMsgCycleTime" BO_ 2566650110 1000;
BA_ "GenMsgCycleTime" BO_ 2566650366 1000;
BA_ "GenMsgCycleTime" BO_ 2566650622 1000;
BA_ "GenMsgCycleTime" BO_ 2566650878 1000;
BA_ "GenMsgCycleTime" BO_ 2566651134 1000;
BA_ "GenMsgCycleTime" BO_ 2566651390 1000;
BA_ "GenMsgCycleTime" BO_ 2566651646 1000;
BA_ "GenMsgCycleTime" BO_ 2566651902 1000;
BA_ "GenMsgCycleTime" BO_ 2566652414 1000;
BA_ "GenMsgCycleTime" BO_ 2566652670 10000;
BA_ "GenMsgCycleTime" BO_ 2566652926 1000;
BA_ "GenMsgCycleTime" BO_ 2566653182 100;
BA_ "GenMsgCycleTime" BO_ 2566653438 1000;
BA_ "GenMsgCycleTime" BO_ 2566653694 100;
BA_ "GenMsgCycleTime" BO_ 2566653950 1000;
BA_ "GenMsgCycleTime" BO_ 2566654206 100;
BA_ "GenMsgCycleTime" BO_ 2566654462 1000;
BA_ "GenMsgCycleTime" BO_ 2566654718 100;
BA_ "GenMsgCycleTime" BO_ 2566654974 250;
BA_ "GenMsgCycleTime" BO_ 2633764094 1000;
BA_ "GenMsgCycleTime" BO_ 2566655742 1000;
BA_ "GenMsgCycleTime" BO_ 2566655998 1000;
BA_ "GenMsgCycleTime" BO_ 2566656254 1000;
BA_ "GenMsgCycleTime" BO_ 2499547902 1000;
BA_ "GenMsgCycleTime" BO_ 2499548158 1000;
BA_ "GenMsgCycleTime" BO_ 2499548670 100;
BA_ "GenMsgCycleTime" BO_ 2499548926 1000;
BA_ "GenMsgCycleTime" BO_ 2499549182 1000;
BA_ "GenMsgCycleTime" BO_ 2566658302 5000;
BA_ "GenMsgCycleTime" BO_ 2566658558 5000;
BA_ "GenMsgCycleTime" BO_ 2566661374 1000;
BA_ "GenMsgCycleTime" BO_ 2566661630 1000;
BA_ "GenMsgCycleTime" BO_ 2566661886 1000;
BA_ "GenMsgCycleTime" BO_ 2566662142 1000;
BA_ "GenMsgCycleTime" BO_ 2566662654 100;
BA_ "GenMsgCycleTime" BO_ 2566662910 10000;
BA_ "GenMsgCycleTime" BO_ 2566663166 1000;
BA_ "GenMsgCycleTime" BO_ 2566663422 1000;
BA_ "GenMsgCycleTime" BO_ 2566663678 500;
BA_ "GenMsgCycleTime" BO_ 2566663934 500;
BA_ "GenMsgCycleTime" BO_ 2633773054 1000;
BA_ "GenMsgCycleTime" BO_ 2566664702 1000;
BA_ "GenMsgCycleTime" BO_ 2499556094 250;
BA_ "GenMsgCycleTime" BO_ 2499556350 500;
BA_ "GenMsgCycleTime" BO_ 2499556606 500;
BA_ "GenMsgCycleTime" BO_ 2566665726 500;
BA_ "GenMsgCycleTime" BO_ 2499557118 500;
BA_ "GenMsgCycleTime" BO_ 2499557374 500;
BA_ "GenMsgCycleTime" BO_ 2499557630 500;
BA_ "GenMsgCycleTime" BO_ 2499557886 500;
BA_ "GenMsgCycleTime" BO_ 2499558142 500;
BA_ "GenMsgCycleTime" BO_ 2566667262 1000;
BA_ "GenMsgCycleTime" BO_ 2566667518 1000;
BA_ "GenMsgCycleTime" BO_ 2566667774 1000;
BA_ "GenMsgCycleTime" BO_ 2566668030 1000;
BA_ "GenMsgCycleTime" BO_ 2566668542 500;
BA_ "GenMsgCycleTime" BO_ 2566668798 500;
BA_ "GenMsgCycleTime" BO_ 2566669054 10000;
BA_ "GenMsgCycleTime" BO_ 2566671102 1000;
BA_ "GenMsgCycleTime" BO_ 2566671870 500;
BA_ "GenMsgCycleTime" BO_ 2566672126 500;
BA_ "GenMsgCycleTime" BO_ 2566672382 1000;
BA_ "GenMsgCycleTime" BO_ 2566672638 1000;
BA_ "GenMsgCycleTime" BO_ 2365346302 100;
BA_ "GenMsgCycleTime" BO_ 2633782014 10000;
BA_ "GenMsgCycleTime" BO_ 2566673406 500;
BA_ "GenMsgCycleTime" BO_ 2566674174 10000;
BA_ "GenMsgCycleTime" BO_ 2566674430 10000;
BA_ "GenMsgCycleTime" BO_ 2566674686 1000;
BA_ "GenMsgCycleTime" BO_ 2365348350 500;
BA_ "GenMsgCycleTime" BO_ 2566687742 200;
BA_ "GenMsgCycleTime" BO_ 2566687998 200;
BA_ "GenMsgCycleTime" BO_ 2432471038 100;
BA_ "GenMsgCycleTime" BO_ 2499580158 500;
BA_ "GenMsgCycleTime" BO_ 2566690046 1000;
BA_ "GenMsgCycleTime" BO_ 2365363710 100;
BA_ "GenMsgCycleTime" BO_ 2566690558 100;
BA_ "GenMsgCycleTime" BO_ 2566690814 500;
BA_ "GenMsgCycleTime" BO_ 2499582206 500;
BA_ "GenMsgCycleTime" BO_ 2499583486 1000;
BA_ "GenMsgCycleTime" BO_ 2499583742 1000;
BA_ "GenMsgCycleTime" BO_ 2566692862 1000;
BA_ "GenMsgCycleTime" BO_ 2566697470 100;
BA_ "GenMsgCycleTime" BO_ 2566698238 1000;
BA_ "GenMsgCycleTime" BO_ 2566698494 1000;
BA_ "GenMsgCycleTime" BO_ 2566698750 1000;
BA_ "GenMsgCycleTime" BO_ 2566699006 1000;
BA_ "GenMsgCycleTime" BO_ 2566699774 1000;
BA_ "GenMsgCycleTime" BO_ 2566700030 1000;
BA_ "GenMsgCycleTime" BO_ 2365374206 20;
BA_ "GenMsgCycleTime" BO_ 2499592190 100;
BA_ "GenMsgCycleTime" BO_ 2499592446 100;
BA_ "GenMsgCycleTime" BO_ 2566701566 1000;
BA_ "GenMsgCycleTime" BO_ 2566701822 1000;
BA_ "GenMsgCycleTime" BO_ 2566702078 200;
BA_ "GenMsgCycleTime" BO_ 2566702334 500;
BA_ "GenMsgCycleTime" BO_ 2566702590 500;
BA_ "GenMsgCycleTime" BO_ 2566703358 1000;
BA_ "GenMsgCycleTime" BO_ 2566703614 100;
BA_ "GenMsgCycleTime" BO_ 2566703870 100;
BA_ "GenMsgCycleTime" BO_ 2566704126 100;
BA_ "GenMsgCycleTime" BO_ 2566706686 500;
BA_ "GenMsgCycleTime" BO_ 2566706942 1000;
BA_ "GenMsgCycleTime" BO_ 2566707198 1000;
BA_ "GenMsgCycleTime" BO_ 2566707454 1000;
BA_ "GenMsgCycleTime" BO_ 2566707710 1000;
BA_ "GenMsgCycleTime" BO_ 2566707966 1000;
BA_ "GenMsgCycleTime" BO_ 2566708222 1000;
BA_ "GenMsgCycleTime" BO_ 2566708478 1000;
BA_ "GenMsgCycleTime" BO_ 2566708734 500;
BA_ "GenMsgCycleTime" BO_ 2566708990 500;
BA_ "GenMsgCycleTime" BO_ 2566709246 500;
BA_ "GenMsgCycleTime" BO_ 2566709502 100;
BA_ "GenMsgCycleTime" BO_ 2566709758 100;
BA_ "GenMsgCycleTime" BO_ 2566710014 1000;
BA_ "GenMsgCycleTime" BO_ 2432492542 100;
BA_ "GenMsgCycleTime" BO_ 2566710526 30000;
BA_ "GenMsgCycleTime" BO_ 2566710782 30000;
BA_ "GenMsgCycleTime" BO_ 2566711038 500;
BA_ "GenMsgCycleTime" BO_ 2566711294 5000;
BA_ "GenMsgCycleTime" BO_ 2566711550 500;
BA_ "GenMsgCycleTime" BO_ 2566711806 100;
BA_ "GenMsgCycleTime" BO_ 2566712318 1000;
BA_ "GenMsgCycleTime" BO_ 2566712574 1000;
BA_ "GenMsgCycleTime" BO_ 2566712830 500;
BA_ "GenMsgCycleTime" BO_ 2499604222 200;
BA_ "GenMsgCycleTime" BO_ 2499604478 500;
BA_ "GenMsgCycleTime" BO_ 2566713598 500;
BA_ "GenMsgCycleTime" BO_ 2566713854 100;
BA_ "GenMsgCycleTime" BO_ 2566714110 100;
BA_ "GenMsgCycleTime" BO_ 2566714366 100;
BA_ "GenMsgCycleTime" BO_ 2566714622 1000;
BA_ "GenMsgCycleTime" BO_ 2566714878 1000;
BA_ "GenMsgCycleTime" BO_ 2566715134 1000;
BA_ "GenMsgCycleTime" BO_ 2566715390 1000;
BA_ "GenMsgCycleTime" BO_ 2566715646 1000;
BA_ "GenMsgCycleTime" BO_ 2566715902 1000;
BA_ "SigType" SG_ 2633755134 HostName 3;
BA_ "SigType" SG_ 2566670078 TireSensorIdentificationNumber 3;
BA_ "SigType" SG_ 2566691326 AssemblyUnitIdentification 3;
BA_ "SigType" SG_ 2566703102 ModelYear 3;
BA_ "SigType" SG_ 2566703102 CertificationEngineFamilyName 3;
VAL_ 2566644990 DrvrSdeFuelReceptacle1CoverStat 0 "Receptacle cover is detached" 1 "Receptacle cover is attached" 2 "Error" 3 "Not available" ;
VAL_ 2566644990 DrvrSdeFuelReceptacle2CoverStat 0 "Receptacle cover is detached" 1 "Receptacle cover is attached" 2 "Error" 3 "Not available" ;
VAL_ 2566644990 PassngSdeFuelReceptacle1CoverSt 0 "Receptacle cover is detached" 1 "Receptacle cover is attached" 2 "Error" 3 "Not available" ;
VAL_ 2566644990 PassngSdeFuelReceptacle2CoverSt 0 "Receptacle cover is detached" 1 "Receptacle cover is attached" 2 "Error" 3 "Not available" ;
VAL_ 2566644990 FrontFuelReceptacleCoverStatus 0 "Receptacle cover is detached" 1 "Receptacle cover is attached" 2 "Error" 3 "Not available" ;
VAL_ 2566645246 HVESFanEnableStatus 0 "Fan Off" 1 "Fan On - Normal, Forward, or Default Direction" 2 "Fan On - Reverse Direction" 3 "Not available" ;
VAL_ 2566645246 HVESFanStatusReasonCode 0 "Normal Operation" 1 "Unable to Start" 2 "Over-Voltage Protection Shutdown" 3 "Under-Voltage Protection Shutdown" 4 "Over-Temperature Protection Shutdown" 5 "Speed Limited due to current protection limit" 6 "Speed limited due to maximum system design capability" 7 "Reserved" 15 "Not Available" ;
VAL_ 2566645246 HVESFanCommandStatus 0 "Internal Command" 1 "External Command" 2 "Default Command" 3 "Not Available" ;
VAL_ 2566645246 HVESFanServiceIndicator 0 "Service Not Required" 1 "Service Required" 2 "Reserved" 3 "Not Available" ;
VAL_ 2566645246 HVESFanOperatingStatus 0 "Normal Operation" 1 "Derated Operation" 2 "Not Operable" 3 "Not Available" ;
VAL_ 2566645246 HVESFanInstance 0 "Instance 1" 1 "Instance 2" 2 "Instance 3" 3 "Instance 4" 4 "Instance 5" 5 "Instance 6" 6 "Instance 7" 7 "Instance 8" 8 "Instance 9" 9 "Instance 10" 10 "Instance 11" 11 "Instance 12" 12 "Instance 13" 13 "Instance 14" 14 "Instance 15" 15 "Not available / Instance not specified" ;
VAL_ 2365318910 HVESFanEnableCommand 0 "Fan Off" 1 "Fan On Normal/Default Direction" 2 "Fan On Reverse Direction" 3 "Don't Care/Take no action" ;
VAL_ 2365318910 HVESFanPowerHold 0 "Power Hold Disabled" 1 "Power Hold Enabled" 2 "Reserved" 3 "Don't Care/Take no action" ;
VAL_ 2365318910 HVESFanInstance1 0 "Command applied to this Fan Instance" 1 "No Command applied to this Fan Instance" ;
VAL_ 2365318910 HVESFanInstance2 0 "Command applied to this Fan Instance" 1 "No Command applied to this Fan Instance" ;
VAL_ 2365318910 HVESFanInstance3 0 "Command applied to this Fan Instance" 1 "No Command applied to this Fan Instance" ;
VAL_ 2365318910 HVESFanInstance4 0 "Command applied to this Fan Instance" 1 "No Command applied to this Fan Instance" ;
VAL_ 2365318910 HVESFanInstance5 0 "Command applied to this Fan Instance" 1 "No Command applied to this Fan Instance" ;
VAL_ 2365318910 HVESFanInstance6 0 "Command applied to this Fan Instance" 1 "No Command applied to this Fan Instance" ;
VAL_ 2365318910 HVESFanInstance7 0 "Command applied to this Fan Instance" 1 "No Command applied to this Fan Instance" ;
VAL_ 2365318910 HVESFanInstance8 0 "Command applied to this Fan Instance" 1 "No Command applied to this Fan Instance" ;
VAL_ 2365318910 HVESFanInstance9 0 "Command applied to this Fan Instance" 1 "No Command applied to this Fan Instance" ;
VAL_ 2365318910 HVESFanInstance10 0 "Command applied to this Fan Instance" 1 "No Command applied to this Fan Instance" ;
VAL_ 2365318910 HVESFanInstance11 0 "Command applied to this Fan Instance" 1 "No Command applied to this Fan Instance" ;
VAL_ 2365318910 HVESFanInstance12 0 "Command applied to this Fan Instance" 1 "No Command applied to this Fan Instance" ;
VAL_ 2365318910 HVESFanInstance13 0 "Command applied to this Fan Instance" 1 "No Command applied to this Fan Instance" ;
VAL_ 2365318910 HVESFanInstance14 0 "Command applied to this Fan Instance" 1 "No Command applied to this Fan Instance" ;
VAL_ 2365318910 HVESFanInstance15 0 "Command applied to this Fan Instance" 1 "No Command applied to this Fan Instance" ;
VAL_ 2633754878 DEFDosingMode 0 "Off, not dosing" 251 "Reserved" 254 "Error (Not Dosing)" 255 "Not available" ;
VAL_ 2633755390 DHCPStatus 0 "Not Configured (static IP)" 1 "Obtaining IP" 2 "IP Leased" 3 "Contacting DHCP Server" 4 "SAE Reserved" 5 "SAE Reserved" 6 "SAE Reserved" 7 "SAE Reserved" 8 "SAE Reserved" 9 "SAE Reserved" 10 "SAE Reserved" 11 "SAE Reserved" 12 "SAE Reserved" 13 "SAE Reserved" 14 "Error" 15 "Not Available" ;
VAL_ 2633755390 EthernetLinkStatus 0 "Ethernet Link Down" 1 "Ethernet Link Up" 2 "Error" 3 "Not Supported" ;
VAL_ 2566648318 OilDebrisMontEnvironmentStatus 0 "Acceptable environment" 1 "Excessive noise in signal" 2 "Reserved" 3 "Not available" ;
VAL_ 2566648318 OilDebrisMontSensingElementStat 0 "Sensing element OK" 1 "Fault with sensing element" 2 "Reserved" 3 "Not available" ;
VAL_ 2566648318 OilDebrisMontSigPrcngElctrncsSt 0 "Electronics functioning normally" 1 "Fault in electronics" 2 "Reserved" 3 "Not available" ;
VAL_ 2566648318 OilDebrisMontElctrncsTempStat 0 "Acceptable temperature" 1 "Temperature is outside of limits" 2 "Reserved" 3 "Not available" ;
VAL_ 2566649854 PropulsionMtrCoolntFn3EnblStatus 0 "Accessory Motor Off" 1 "Accessory Motor On - Normal, Forward, or Default Direction" 2 "Accessory Motor On - Reverse Direction" 3 "Not available" ;
VAL_ 2566649854 ProplsnMtrClntFn3CtrllerStRsnCd 0 "Normal Operation" 1 "Unable to Start" 2 "Over-Voltage Protection Shutdown" 3 "Under-Voltage Protection Shutdown" 4 "Over-Temperature Protection Shutdown" 5 "Speed Limited due to current protection limit" 6 "Speed limited due to maximum system design capability" 7 "Speed limited due to torque limit" 8 "Speed limited due to over-temperature protection" 9 "Exceeding commanded speed due to external force" 10 "Reserved" 15 "Not Available" ;
VAL_ 2566649854 ProplsnMtrClntFn3CtrllerCmdStat 0 "Internal Command" 1 "External Command" 2 "Default Command" 3 "Not Available" ;
VAL_ 2566649854 ProplsnMtrCoolntFn3SrvcIndictr 0 "Service Not Required" 1 "Service Required" 2 "Reserved" 3 "Not Available" ;
VAL_ 2566649854 ProplsnMtrCoolntFn3OprtngStatus 0 "Normal Operation" 1 "Derated Operation" 2 "Not Operable" 3 "Not Available" ;
VAL_ 2566650110 PropulsionMtrCoolntFn2EnblStatus 0 "Accessory Motor Off" 1 "Accessory Motor On - Normal, Forward, or Default Direction" 2 "Accessory Motor On - Reverse Direction" 3 "Not available" ;
VAL_ 2566650110 ProplsnMtrClntFn2CtrllerStRsnCd 0 "Normal Operation" 1 "Unable to Start" 2 "Over-Voltage Protection Shutdown" 3 "Under-Voltage Protection Shutdown" 4 "Over-Temperature Protection Shutdown" 5 "Speed Limited due to current protection limit" 6 "Speed limited due to maximum system design capability" 7 "Speed limited due to torque limit" 8 "Speed limited due to over-temperature protection" 9 "Exceeding commanded speed due to external force" 10 "Reserved" 15 "Not Available" ;
VAL_ 2566650110 ProplsnMtrClntFn2CtrllerCmdStat 0 "Internal Command" 1 "External Command" 2 "Default Command" 3 "Not Available" ;
VAL_ 2566650110 ProplsnMtrCoolntFn2SrvcIndictr 0 "Service Not Required" 1 "Service Required" 2 "Reserved" 3 "Not Available" ;
VAL_ 2566650110 ProplsnMtrCoolntFn2OprtngStatus 0 "Normal Operation" 1 "Derated Operation" 2 "Not Operable" 3 "Not Available" ;
VAL_ 2566650366 PropulsionMtrCoolntFn1EnblStatus 0 "Accessory Motor Off" 1 "Accessory Motor On - Normal, Forward, or Default Direction" 2 "Accessory Motor On - Reverse Direction" 3 "Not available" ;
VAL_ 2566650366 ProplsnMtrClntFn1CtrllerStRsnCd 0 "Normal Operation" 1 "Unable to Start" 2 "Over-Voltage Protection Shutdown" 3 "Under-Voltage Protection Shutdown" 4 "Over-Temperature Protection Shutdown" 5 "Speed Limited due to current protection limit" 6 "Speed limited due to maximum system design capability" 7 "Speed limited due to torque limit" 8 "Speed limited due to over-temperature protection" 9 "Exceeding commanded speed due to external force" 10 "Reserved" 15 "Not Available" ;
VAL_ 2566650366 ProplsnMtrClntFn1CtrllerCmdStat 0 "Internal Command" 1 "External Command" 2 "Default Command" 3 "Not Available" ;
VAL_ 2566650366 ProplsnMtrCoolntFn1SrvcIndictr 0 "Service Not Required" 1 "Service Required" 2 "Reserved" 3 "Not Available" ;
VAL_ 2566650366 ProplsnMtrCoolntFn1OprtngStatus 0 "Normal Operation" 1 "Derated Operation" 2 "Not Operable" 3 "Not Available" ;
VAL_ 2566650622 PowerElctrncsCoolntFn3EnblStatus 0 "Accessory Motor Off" 1 "Accessory Motor On - Normal, Forward, or Default Direction" 2 "Accessory Motor On - Reverse Direction" 3 "Not available" ;
VAL_ 2566650622 PwrElctrncsClntFn3CtrllerStRsnCd 0 "Normal Operation" 1 "Unable to Start" 2 "Over-Voltage Protection Shutdown" 3 "Under-Voltage Protection Shutdown" 4 "Over-Temperature Protection Shutdown" 5 "Speed Limited due to current protection limit" 6 "Speed limited due to maximum system design capability" 7 "Speed limited due to torque limit" 8 "Speed limited due to over-temperature protection" 9 "Exceeding commanded speed due to external force" 10 "Reserved" 15 "Not Available" ;
VAL_ 2566650622 PwrElctrncsClntFn3CtrllerCmdStat 0 "Internal Command" 1 "External Command" 2 "Default Command" 3 "Not Available" ;
VAL_ 2566650622 PwrElctrncsCoolntFn3SrvcIndictr 0 "Service Not Required" 1 "Service Required" 2 "Reserved" 3 "Not Available" ;
VAL_ 2566650622 PwrElctrncsCoolntFn3OprtngStatus 0 "Normal Operation" 1 "Derated Operation" 2 "Not Operable" 3 "Not Available" ;
VAL_ 2566650878 PowerElctrncsCoolntFn2EnblStatus 0 "Accessory Motor Off" 1 "Accessory Motor On - Normal, Forward, or Default Direction" 2 "Accessory Motor On - Reverse Direction" 3 "Not available" ;
VAL_ 2566650878 PwrElctrncsClntFn2CtrllerStRsnCd 0 "Normal Operation" 1 "Unable to Start" 2 "Over-Voltage Protection Shutdown" 3 "Under-Voltage Protection Shutdown" 4 "Over-Temperature Protection Shutdown" 5 "Speed Limited due to current protection limit" 6 "Speed limited due to maximum system design capability" 7 "Speed limited due to torque limit" 8 "Speed limited due to over-temperature protection" 9 "Exceeding commanded speed due to external force" 10 "Reserved" 15 "Not Available" ;
VAL_ 2566650878 PwrElctrncsClntFn2CtrllerCmdStat 0 "Internal Command" 1 "External Command" 2 "Default Command" 3 "Not Available" ;
VAL_ 2566650878 PwrElctrncsCoolntFn2SrvcIndictr 0 "Service Not Required" 1 "Service Required" 2 "Reserved" 3 "Not Available" ;
VAL_ 2566650878 PwrElctrncsCoolntFn2OprtngStatus 0 "Normal Operation" 1 "Derated Operation" 2 "Not Operable" 3 "Not Available" ;
VAL_ 2566651134 PowerElctrncsCoolntFn1EnblStatus 0 "Accessory Motor Off" 1 "Accessory Motor On - Normal, Forward, or Default Direction" 2 "Accessory Motor On - Reverse Direction" 3 "Not available" ;
VAL_ 2566651134 PwrElctrncsClntFn1CtrllerStRsnCd 0 "Normal Operation" 1 "Unable to Start" 2 "Over-Voltage Protection Shutdown" 3 "Under-Voltage Protection Shutdown" 4 "Over-Temperature Protection Shutdown" 5 "Speed Limited due to current protection limit" 6 "Speed limited due to maximum system design capability" 7 "Speed limited due to torque limit" 8 "Speed limited due to over-temperature protection" 9 "Exceeding commanded speed due to external force" 10 "Reserved" 15 "Not Available" ;
VAL_ 2566651134 PwrElctrncsClntFn1CtrllerCmdStat 0 "Internal Command" 1 "External Command" 2 "Default Command" 3 "Not Available" ;
VAL_ 2566651134 PwrElctrncsCoolntFn1SrvcIndictr 0 "Service Not Required" 1 "Service Required" 2 "Reserved" 3 "Not Available" ;
VAL_ 2566651134 PwrElctrncsCoolntFn1OprtngStatus 0 "Normal Operation" 1 "Derated Operation" 2 "Not Operable" 3 "Not Available" ;
VAL_ 2566651390 PropulsionMotorOilPumpEnblStatus 0 "Accessory Motor Off" 1 "Accessory Motor On - Normal, Forward, or Default Direction" 2 "Accessory Motor On - Reverse Direction" 3 "Not available" ;
VAL_ 2566651390 ProplsnMtrOilPmpCtrllerStatRsnCd 0 "Normal Operation" 1 "Unable to Start" 2 "Over-Voltage Protection Shutdown" 3 "Under-Voltage Protection Shutdown" 4 "Over-Temperature Protection Shutdown" 5 "Speed Limited due to current protection limit" 6 "Speed limited due to maximum system design capability" 7 "Speed limited due to torque limit" 8 "Speed limited due to over-temperature protection" 9 "Exceeding commanded speed due to external force" 10 "Reserved" 15 "Not Available" ;
VAL_ 2566651390 ProplsnMtrOilPmpCtrllerCmdStatus 0 "Internal Command" 1 "External Command" 2 "Default Command" 3 "Not Available" ;
VAL_ 2566651390 ProplsnMtrOilPumpServiceIndictr 0 "Service Not Required" 1 "Service Required" 2 "Reserved" 3 "Not Available" ;
VAL_ 2566651390 PropulsionMtrOilPumpOprtngStatus 0 "Normal Operation" 1 "Derated Operation" 2 "Not Operable" 3 "Not Available" ;
VAL_ 2566651646 ProplsnMtrCoolntPumpEnblStatus 0 "Accessory Motor Off" 1 "Accessory Motor On - Normal, Forward, or Default Direction" 2 "Accessory Motor On - Reverse Direction" 3 "Not available" ;
VAL_ 2566651646 ProplsnMtrClntPmpCtrllerStRsnCd 0 "Normal Operation" 1 "Unable to Start" 2 "Over-Voltage Protection Shutdown" 3 "Under-Voltage Protection Shutdown" 4 "Over-Temperature Protection Shutdown" 5 "Speed Limited due to current protection limit" 6 "Speed limited due to maximum system design capability" 7 "Speed limited due to torque limit" 8 "Speed limited due to over-temperature protection" 9 "Exceeding commanded speed due to external force" 10 "Reserved" 15 "Not Available" ;
VAL_ 2566651646 ProplsnMtrClntPmpCtrllerCmdStat 0 "Internal Command" 1 "External Command" 2 "Default Command" 3 "Not Available" ;
VAL_ 2566651646 ProplsnMtrCoolntPmpSrvcIndictr 0 "Service Not Required" 1 "Service Required" 2 "Reserved" 3 "Not Available" ;
VAL_ 2566651646 ProplsnMtrCoolntPumpOprtngStatus 0 "Normal Operation" 1 "Derated Operation" 2 "Not Operable" 3 "Not Available" ;
VAL_ 2566651902 PwrElctrncsCoolntPumpEnblStatus 0 "Accessory Motor Off" 1 "Accessory Motor On - Normal, Forward, or Default Direction" 2 "Accessory Motor On - Reverse Direction" 3 "Not available" ;
VAL_ 2566651902 PwrElctrncsClntPmpCtrllerStRsnCd 0 "Normal Operation" 1 "Unable to Start" 2 "Over-Voltage Protection Shutdown" 3 "Under-Voltage Protection Shutdown" 4 "Over-Temperature Protection Shutdown" 5 "Speed Limited due to current protection limit" 6 "Speed limited due to maximum system design capability" 7 "Speed limited due to torque limit" 8 "Speed limited due to over-temperature protection" 9 "Exceeding commanded speed due to external force" 10 "Reserved" 15 "Not Available" ;
VAL_ 2566651902 PwrElctrncsClntPmpCtrllerCmdStat 0 "Internal Command" 1 "External Command" 2 "Default Command" 3 "Not Available" ;
VAL_ 2566651902 PwrElctrncsCoolntPmpSrvcIndictr 0 "Service Not Required" 1 "Service Required" 2 "Reserved" 3 "Not Available" ;
VAL_ 2566651902 PwrElctrncsCoolntPmpOprtngStatus 0 "Normal Operation" 1 "Derated Operation" 2 "Not Operable" 3 "Not Available" ;
VAL_ 2566652414 ElectrfdAccssryMotorEnableStatus 0 "Accessory Motor Off" 1 "Accessory Motor On - Normal, Forward, or Default Direction" 2 "Accessory Motor On - Reverse Direction" 3 "Not available" ;
VAL_ 2566652414 ElectrfdAccssryMtrCtrllerStRsnCd 0 "Normal Operation" 1 "Unable to Start" 2 "Over-Voltage Protection Shutdown" 3 "Under-Voltage Protection Shutdown" 4 "Over-Temperature Protection Shutdown" 5 "Speed Limited due to current protection limit" 6 "Speed limited due to maximum system design capability" 7 "Speed limited due to torque limit" 8 "Speed limited due to over-temperature protection" 9 "Exceeding commanded speed due to external force" 10 "Reserved" 15 "Not Available" ;
VAL_ 2566652414 ElectrfdAccssryMtrCtrllerCmdStat 0 "Internal Command" 1 "External Command" 2 "Default Command" 3 "Not Available" ;
VAL_ 2566652414 ElectrfdAccssryMtrServiceIndictr 0 "Service Not Required" 1 "Service Required" 2 "Reserved" 3 "Not Available" ;
VAL_ 2566652414 ElectrfdAccssryMtrOprtngStatus 0 "Normal Operation" 1 "Derated Operation" 2 "Not Operable" 3 "Not Available" ;
VAL_ 2566652414 ElectrifiedAccssryMotorInstance 0 "Instance 1" 1 "Instance 2" 2 "Instance 3" 3 "Instance 4" 4 "Instance 5" 5 "Instance 6" 6 "Instance 7" 7 "Instance 8" 8 "Instance 9" 9 "Instance 10" 10 "Instance 11" 11 "Instance 12" 12 "Instance 13" 13 "Instance 14" 14 "Instance 15" 15 "Not available / Instance not specified" ;
VAL_ 2566652670 Aft1DslExhstFldDsngSysFrozen 0 "DEF system is not frozen" 1 "DEF system is frozen" 2 "Error" 3 "Not available" ;
VAL_ 2566652670 Aft2DslExhstFldDsngSysFrozen 0 "DEF system is not frozen" 1 "DEF system is frozen" 2 "Error" 3 "Not available" ;
VAL_ 2566652926 SLIBattryPack1Battry4StateCharge 64256 "Conditions are not acceptable for a valid measurement." ;
VAL_ 2566652926 SLIBatteryPack1Battery4Capacity 64256 "Capacity cannot be reported." ;
VAL_ 2566652926 SLIBatteryPack1Battery4Health 251 "Conditions are not acceptable for a valid measurement." ;
VAL_ 2566652926 SLIBattPack1Batt4PrdctMnCrnkVltg 251 "Conditions are not acceptable for a valid measurement." ;
VAL_ 2566652926 SLIBattryPack1Sensor4InitStatus 0 "Initialization process has not started." 1 "Initialization process is in progress." 10 "Initialization process is complete." ;
VAL_ 2566653438 SLIBattryPack1Battry3StateCharge 64256 "Conditions are not acceptable for a valid measurement." ;
VAL_ 2566653438 SLIBatteryPack1Battery3Capacity 64256 "Capacity cannot be reported." ;
VAL_ 2566653438 SLIBatteryPack1Battery3Health 251 "Conditions are not acceptable for a valid measurement." ;
VAL_ 2566653438 SLIBattPack1Batt3PrdctMnCrnkVltg 251 "Conditions are not acceptable for a valid measurement." ;
VAL_ 2566653438 SLIBattryPack1Sensor3InitStatus 0 "Initialization process has not started." 1 "Initialization process is in progress." 10 "Initialization process is complete." ;
VAL_ 2566653950 SLIBattryPack1Battry2StateCharge 64256 "Conditions are not acceptable for a valid measurement." ;
VAL_ 2566653950 SLIBatteryPack1Battery2Capacity 64256 "Capacity cannot be reported." ;
VAL_ 2566653950 SLIBatteryPack1Battery2Health 251 "Conditions are not acceptable for a valid measurement." ;
VAL_ 2566653950 SLIBattPack1Batt2PrdctMnCrnkVltg 251 "Conditions are not acceptable for a valid measurement." ;
VAL_ 2566653950 SLIBattryPack1Sensor2InitStatus 0 "Initialization process has not started." 1 "Initialization process is in progress." 10 "Initialization process is complete." ;
VAL_ 2566654462 SLIBattryPack1Battry1StateCharge 64256 "Conditions are not acceptable for a valid measurement." ;
VAL_ 2566654462 SLIBatteryPack1Battery1Capacity 64256 "Capacity cannot be reported." ;
VAL_ 2566654462 SLIBatteryPack1Battery1Health 251 "Conditions are not acceptable for a valid measurement." ;
VAL_ 2566654462 SLIBattPack1Batt1PrdctMnCrnkVltg 251 "Conditions are not acceptable for a valid measurement." ;
VAL_ 2566654462 SLIBattryPack1Sensor1InitStatus 0 "Initialization process has not started." 1 "Initialization process is in progress." 10 "Initialization process is complete." ;
VAL_ 2633764094 CanisterVentValve 0 "Vent Valve is Closed" 1 "Vent Valve is Open" 2 "Error" 3 "Not Available" ;
VAL_ 2633764094 CanisterPurgeValveCommand 0 "Fully closed" 100 "Fully open" ;
VAL_ 2499547902 CabDoorsLockActuationCommand 0 "Unlock left front cab door latch" 1 "Unlock right front cab door latch" 2 "Unlock left rear cab door latch" 3 "Unlock right rear cab door latch" 4 "Unlock all cab door latches" 5 "Lock all cab door latches" 6 "Reserved" 7 "Take no action" ;
VAL_ 2499547902 RemoteCabDoorLockRequest 0 "Request unlock left front cab door latch" 1 "Request unlock right front cab door latch" 2 "Request unlock left rear cab door latch" 3 "Request unlock right rear cab door latch" 4 "Request unlock all cab door latches" 5 "Request lock all cab door latches" 6 "Reserved" 7 "Take no action" ;
VAL_ 2499547902 LeftFrontWindowPositionCommand 0 "Window move up" 1 "Window move down" 2 "Window auto up" 3 "Window auto down" 4 "Reserved" 5 "Reserved" 6 "Reserved" 7 "Take no action" ;
VAL_ 2499547902 RightFrontWindowPositionCommand 0 "Window move up" 1 "Window move down" 2 "Window auto up" 3 "Window auto down" 4 "Reserved" 5 "Reserved" 6 "Reserved" 7 "Take no action" ;
VAL_ 2499547902 MirrorFoldingSwitch 0 "No Request" 1 "Request to toggle mirror position (fold/unfold)" 2 "Reserved" 3 "Take no action" ;
VAL_ 2499547902 LeftRearWindowPositionCommand 0 "Window move up" 1 "Window move down" 2 "Window auto up" 3 "Window auto down" 4 "Reserved" 5 "Reserved" 6 "Reserved" 7 "Take no action" ;
VAL_ 2499547902 RightRearWindowPositionCommand 0 "Window move up" 1 "Window move down" 2 "Window auto up" 3 "Window auto down" 4 "Reserved" 5 "Reserved" 6 "Reserved" 7 "Take no action" ;
VAL_ 2499547902 MirrorAutoPanningEnable 0 "Disable panning" 1 "Enable panning" 2 "Reserved" 3 "Not available/Take no action" ;
VAL_ 2499547902 MirrorLeft1HorizontalCommand 0 "Move left" 1 "Move right" 2 "Reserved" 3 "Take no action" ;
VAL_ 2499547902 MirrorLeft1VerticalCommand 0 "Move up" 1 "Move down" 2 "Reserved" 3 "Take no action" ;
VAL_ 2499547902 MirrorRight1HorizontalCommand 0 "Move left" 1 "Move right" 2 "Reserved" 3 "Take no action" ;
VAL_ 2499547902 MirrorRight1VerticalCommand 0 "Move up" 1 "Move down" 2 "Reserved" 3 "Take no action" ;
VAL_ 2499547902 MirrorLeft2HorizontalCommand 0 "Move left" 1 "Move right" 2 "Reserved" 3 "Take no action" ;
VAL_ 2499547902 MirrorLeft2VerticalCommand 0 "Move up" 1 "Move down" 2 "Reserved" 3 "Take no action" ;
VAL_ 2499547902 MirrorRight2HorizontalCommand 0 "Move left" 1 "Move right" 2 "Reserved" 3 "Take no action" ;
VAL_ 2499547902 MirrorRight2VerticalCommand 0 "Move up" 1 "Move down" 2 "Reserved" 3 "Take no action" ;
VAL_ 2499547902 MirrorLeft1HeatCommand 0 "Mirror heat off" 1 "Mirror heat on" 2 "Reserved" 3 "Take no action" ;
VAL_ 2499547902 MirrorRight1HeatCommand 0 "Mirror heat off" 1 "Mirror heat on" 2 "Reserved" 3 "Take no action" ;
VAL_ 2499547902 MirrorLeft2HeatCommand 0 "Mirror heat off" 1 "Mirror heat on" 2 "Reserved" 3 "Take no action" ;
VAL_ 2499547902 MirrorRight2HeatCommand 0 "Mirror heat off" 1 "Mirror heat on" 2 "Reserved" 3 "Take no action" ;
VAL_ 2499548158 LeftFrontCabDoorLatchPosition 0 "Door Latch Open" 1 "Door Latch Fully Closed/Latched" 2 "Door Latch Ajar" 3 "Reserved" 4 "Reserved" 5 "Reserved" 6 "Error" 7 "Not Available" ;
VAL_ 2499548158 RightFrontCabDoorLatchPosition 0 "Door Latch Open" 1 "Door Latch Fully Closed/Latched" 2 "Door Latch Ajar" 3 "Reserved" 4 "Reserved" 5 "Reserved" 6 "Error" 7 "Not Available" ;
VAL_ 2499548158 LeftRearCabDoorLatchPosition 0 "Door Latch Open" 1 "Door Latch Fully Closed/Latched" 2 "Door Latch Ajar" 3 "Reserved" 4 "Reserved" 5 "Reserved" 6 "Error" 7 "Not Available" ;
VAL_ 2499548158 RightRearCabDoorLatchPosition 0 "Door Latch Open" 1 "Door Latch Fully Closed/Latched" 2 "Door Latch Ajar" 3 "Reserved" 4 "Reserved" 5 "Reserved" 6 "Error" 7 "Not Available" ;
VAL_ 2566661374 Aftrtrtmnt2DslExhstFldTnkVolume2 251 "Conditions are not acceptable for a valid measurement." ;
VAL_ 2566661630 Aftrtrtmnt1DslExhstFldTnkVolume2 251 "Conditions are not acceptable for a valid measurement." ;
VAL_ 2566662654 LftDistToLaneMarkFrmVhclsMiddle 251 "not in range" 252 "not reliable" 253 "reserved / not used" 254 "error" 255 "not available or not installed" ;
VAL_ 2566662654 RghtDistToLaneMarkFrmVhclsMiddle 251 "not in range" 252 "not reliable" 253 "reserved / not used" 254 "error" 255 "not available or not installed" ;
VAL_ 2566662654 RoadCurvatureBasedOnLaneMarks 64257 "not in range" 64258 "not reliable" 64259 "reserved for parameter specific indicator" 64512 "reserved range for future indicator bits" 65024 "error indicator" 65280 "not available or not installed" ;
VAL_ 2566662654 LaneDepartureAngleLeft 251 "not in range" 252 "not reliable" 253 "reserved / not used" 254 "error" 255 "not available or not installed" ;
VAL_ 2566662654 LaneDepartureAngleRight 251 "not in range" 252 "not reliable" 253 "reserved / not used" 254 "error" 255 "not available or not installed" ;
VAL_ 2566662654 LaneMarkQualityOnTheLeftSide 0 "no lane marks detected" 1 "low reliablity of detected lane marks" 2 "good reliablity of detected lane marks" 3 "perfect recognition of lane marks" 4 "reserved for future use" 6 "error" 7 "not available or not installed" ;
VAL_ 2566662654 LaneMarkQualityOnTheRightSide 0 "no lane marks detected" 1 "low reliablity of detected lane marks" 2 "good reliablity of detected lane marks" 3 "perfect recognition of lane marks" 4 "reserved for future use" 6 "error" 7 "not available or not installed" ;
VAL_ 2566662654 RightLaneMarkerType 0 "Processing or not identified" 1 "Solid" 2 "Road edge" 3 "Dashed" 4 "Double lane marker" 5 "Raised lane marker" 6 "Reserved" 14 "Error" 15 "Not available" ;
VAL_ 2566662654 LeftLaneMarkerType 0 "Processing or not identified" 1 "Solid" 2 "Road edge" 3 "Dashed" 4 "Double lane marker" 5 "Raised lane marker" 6 "Reserved" 14 "Error" 15 "Not available" ;
VAL_ 2566662910 OprtrIndcmntTmeToTrqDerateLvl1 64256 "Operator inducement is not active" ;
VAL_ 2566662910 OperatorIndcmntTorqueDerateLvl2 0 "No operator inducement is active." ;
VAL_ 2566662910 OprtrIndcmntTmeToTrqDerateLvl2 64256 "Operator inducement is not active" ;
VAL_ 2566662910 OprtrIndcmntTmeToFinalIndcmntAct 64256 "Operator inducement is not active" ;
VAL_ 2566663166 EngExternalIdleRequestFeedback 0 "No Idle Alteration Active" 1 "Idle Alteration Active" 2 "Error" 3 "Not available" ;
VAL_ 2566663422 TractorBrkCaliperLnngClrAxl1Lft 0 "Caliper lining clearance is adequate" 1 "Caliper lining clearance is low" 2 "Error" 3 "Not available / not applicable" ;
VAL_ 2566663422 TractorBrkCaliperLnngClrAxl1Rght 0 "Caliper lining clearance is adequate" 1 "Caliper lining clearance is low" 2 "Error" 3 "Not available / not applicable" ;
VAL_ 2566663422 TractorBrkCaliperLnngClrAxl2Lft 0 "Caliper lining clearance is adequate" 1 "Caliper lining clearance is low" 2 "Error" 3 "Not available / not applicable" ;
VAL_ 2566663422 TractorBrkCaliperLnngClrAxl2Rght 0 "Caliper lining clearance is adequate" 1 "Caliper lining clearance is low" 2 "Error" 3 "Not available / not applicable" ;
VAL_ 2566663422 TractorBrkCaliperLnngClrAxl3Lft 0 "Caliper lining clearance is adequate" 1 "Caliper lining clearance is low" 2 "Error" 3 "Not available / not applicable" ;
VAL_ 2566663422 TractorBrkCaliperLnngClrAxl3Rght 0 "Caliper lining clearance is adequate" 1 "Caliper lining clearance is low" 2 "Error" 3 "Not available / not applicable" ;
VAL_ 2566663422 TractorBrkCaliperLnngClrAxl4Lft 0 "Caliper lining clearance is adequate" 1 "Caliper lining clearance is low" 2 "Error" 3 "Not available / not applicable" ;
VAL_ 2566663422 TractorBrkCaliperLnngClrAxl4Rght 0 "Caliper lining clearance is adequate" 1 "Caliper lining clearance is low" 2 "Error" 3 "Not available / not applicable" ;
VAL_ 2566663422 TractorBrkCaliperLnngClrAxl5Lft 0 "Caliper lining clearance is adequate" 1 "Caliper lining clearance is low" 2 "Error" 3 "Not available / not applicable" ;
VAL_ 2566663422 TractorBrkCaliperLnngClrAxl5Rght 0 "Caliper lining clearance is adequate" 1 "Caliper lining clearance is low" 2 "Error" 3 "Not available / not applicable" ;
VAL_ 2566663422 TrlrBrkCaliperLnngClearAxl1Lft 0 "Caliper lining clearance is adequate" 1 "Caliper lining clearance is low" 2 "Error" 3 "Not available / not applicable" ;
VAL_ 2566663422 TrlrBrkCaliperLnngClearAxl1Rght 0 "Caliper lining clearance is adequate" 1 "Caliper lining clearance is low" 2 "Error" 3 "Not available / not applicable" ;
VAL_ 2566663422 TrlrBrkCaliperLnngClearAxl2Lft 0 "Caliper lining clearance is adequate" 1 "Caliper lining clearance is low" 2 "Error" 3 "Not available / not applicable" ;
VAL_ 2566663422 TrlrBrkCaliperLnngClearAxl2Rght 0 "Caliper lining clearance is adequate" 1 "Caliper lining clearance is low" 2 "Error" 3 "Not available / not applicable" ;
VAL_ 2566663422 TrlrBrkCaliperLnngClearAxl3Lft 0 "Caliper lining clearance is adequate" 1 "Caliper lining clearance is low" 2 "Error" 3 "Not available / not applicable" ;
VAL_ 2566663422 TrlrBrkCaliperLnngClearAxl3Rght 0 "Caliper lining clearance is adequate" 1 "Caliper lining clearance is low" 2 "Error" 3 "Not available / not applicable" ;
VAL_ 2566663422 TrlrBrkCaliperLnngClearAxl4Lft 0 "Caliper lining clearance is adequate" 1 "Caliper lining clearance is low" 2 "Error" 3 "Not available / not applicable" ;
VAL_ 2566663422 TrlrBrkCaliperLnngClearAxl4Rght 0 "Caliper lining clearance is adequate" 1 "Caliper lining clearance is low" 2 "Error" 3 "Not available / not applicable" ;
VAL_ 2566663422 TrlrBrkCaliperLnngClearAxl5Lft 0 "Caliper lining clearance is adequate" 1 "Caliper lining clearance is low" 2 "Error" 3 "Not available / not applicable" ;
VAL_ 2566663422 TrlrBrkCaliperLnngClearAxl5Rght 0 "Caliper lining clearance is adequate" 1 "Caliper lining clearance is low" 2 "Error" 3 "Not available / not applicable" ;
VAL_ 2566663934 EngTurboCmprBffActr1MtrCurDisabl 0 "Do Not Disable" 1 "Disable" 2 "Reserved" 3 "Don't Care/Take No Action" ;
VAL_ 2566663934 EngTurboWstgtActr1MtrCurrDisabl 0 "Do Not Disable" 1 "Disable" 2 "Reserved" 3 "Don't Care/Take No Action" ;
VAL_ 2566663934 EngCylHeadBypssActr1MtrCurDisabl 0 "Do Not Disable" 1 "Disable" 2 "Reserved" 3 "Don't Care/Take No Action" ;
VAL_ 2566663934 EngThrottleValve1MotorCurrDisabl 0 "Do Not Disable" 1 "Disable" 2 "Reserved" 3 "Don't Care/Take No Action" ;
VAL_ 2566663934 EngTurboCmprBypssActr1MtrCurDsbl 0 "Do Not Disable" 1 "Disable" 2 "Reserved" 3 "Don't Care/Take No Action" ;
VAL_ 2566663934 EngTurboCmprBypssActr2MtrCurDsbl 0 "Do Not Disable" 1 "Disable" 2 "Reserved" 3 "Don't Care/Take No Action" ;
VAL_ 2566663934 EngTurboWstgtActr2MtrCurrDisabl 0 "Do Not Disable" 1 "Disable" 2 "Reserved" 3 "Don't Care/Take No Action" ;
VAL_ 2633773310 SCROperatorIndcmntOverrideMode 0 "Not Available" 1 "Available" 2 "Active" 3 "Active Extended" 4 "Expired" 5 "Not Defined" 7 "Not Available" ;
VAL_ 2633773310 SCROprtrIndcOvrrdRenewalRequired 0 "Not Required" 1 "Required" 2 "Error" 3 "Not Available" ;
VAL_ 2566664702 AftrtrtmntThermalMangmntStatus 0 "Not active" 1 "Active" 2 "Reserved for SAE assignment" 3 "Not available" ;
VAL_ 2566664702 AftActRegenInhbtdDTLowExhstPress 0 "Not Inhibited" 1 "Inhibited" 2 "Reserved for SAE assignment" 3 "Not Available" ;
VAL_ 2566664702 AftrtrtmntEngSpeedIncreaseRq 0 "No Request" 1 "Aftertreatment Engine Speed Control Desired" 2 "Urgent Aftertreatment Engine Speed Control Desired" 3 "Not Available" ;
VAL_ 2566664702 AftertreatmentEngineLoadRequest 0 "No Request" 1 "Aftertreatment Engine Load Desired" 2 "Urgent Aftertreatment Engine Load Desired" 3 "Not Available" ;
VAL_ 2566664702 AftrtrtmntDslExhstFldHtrCircBrkr 0 "Off" 1 "On" 2 "Error" 3 "Not available" ;
VAL_ 2566664702 DslExhstFldQltyMalfctEvPeriodAct 0 "Not active" 1 "Active" 2 "SAE reserved" 3 "Not supported" ;
VAL_ 2566664702 AfttreatmentSCRDosingModeStatus 0 "Standard SCR Dosing Mode" 1 "Reduced SCR Dosing Mode" 2 "Reserved" 3 "Reserved" 4 "Reserved" 5 "Reserved" 6 "Error" 7 "Not Available" ;
VAL_ 2566664702 AftrtrtmntDslExhstFldTankVolume 0 "Empty" 250 "Full" 251 "Conditions are not acceptable for a valid measurement." ;
VAL_ 2499556094 Aft1PrtcltSnsrHtrHiSdeDrvPrlmFMI 31 "no failure has been detected or parameter is not supported" ;
VAL_ 2499556094 Aft1PrtcltSnsrHtrHiSdeDrvDiagSt 0 "Tests monitored continuously" 1 "Tests supported but not completed this power cycle." 2 "Enable or pause conditions have allowed tests to execute this power cycle." 4 "SAE Reserved" 7 "Not Available." ;
VAL_ 2499556094 Aft1PrtcltSnsrHtrLoSdeDrvPrlmFMI 31 "no failure has been detected or parameter is not supported" ;
VAL_ 2499556094 Aft1PrtcltSnsrHtrLoSdeDrvDiagSt 0 "Tests monitored continuously." 1 "Tests supported but not completed this power cycle." 2 "Enable or pause conditions have allowed tests to execute this power cycle." 4 "SAE Reserved" 7 "Not Available." ;
VAL_ 2499556094 Aft1PrtcltSnsrInptPrelimFMI 31 "no failure has been detected or parameter is not supported" ;
VAL_ 2499556094 Aft1PrtcltSnsrInptDiagStat 0 "Tests monitored continuously." 1 "Tests supported but not completed this power cycle." 2 "Enable or pause conditions have allowed tests to execute this power cycle." 4 "SAE Reserved" 7 "Not Available." ;
VAL_ 2499556094 Aft1PrtcltSnsrPwrSuppPrelimFMI 31 "no failure has been detected or parameter is not supported" ;
VAL_ 2499556094 Aft1PrtcltSnsrPwrSuppDiagStat 0 "Tests monitored continuously." 1 "Tests supported but not completed this power cycle." 2 "Enable or pause conditions have allowed tests to execute this power cycle." 4 "SAE Reserved" 7 "Not Available." ;
VAL_ 2499556094 Aft1PrtcltSnsrHtrPwrSuppPrlmFMI 31 "no failure has been detected or parameter is not supported" ;
VAL_ 2499556094 Aft1PrtcltSnsrHtrPwrSuppDiagStat 0 "Tests monitored continuously." 1 "Tests supported but not completed this power cycle." 2 "Enable or pause conditions have allowed tests to execute this power cycle." 4 "SAE Reserved" 7 "Not Available." ;
VAL_ 2499557118 InertGasSupplyValvePosition 0 "valve fully closed" 100 "valve fully open" ;
VAL_ 2566668030 HeatExchangerDebrisPurgeStatus 0 "Inactive" 1 "Active" 2 "SAE reserved" 3 "Not available" ;
VAL_ 2566668030 HeatExchangerDebrisPurgeApprchng 0 "Not approaching" 1 "Approaching" 2 "SAE reserved" 3 "Not available" ;
VAL_ 2566669054 TireLocation 255 "Not available" ;
VAL_ 2566669310 TireLocation 255 "Not available" ;
VAL_ 2566669822 TireSensorNumber 255 "SPN is not used" ;
VAL_ 2566669822 TireLocation 255 "Not available" ;
VAL_ 2566670078 TireNumber 255 "SPN is not used" ;
VAL_ 2566670078 TireLocation 255 "Not available" ;
VAL_ 2566670334 Axle1MonitoredTireCount 15 "Not Available" ;
VAL_ 2566670334 Axle2MonitoredTireCount 15 "Not Available" ;
VAL_ 2566670334 Axle3MonitoredTireCount 15 "Not Available" ;
VAL_ 2566670334 Axle4MonitoredTireCount 15 "Not Available" ;
VAL_ 2566670334 Axle5MonitoredTireCount 15 "Not Available" ;
VAL_ 2566670334 Axle6MonitoredTireCount 15 "Not Available" ;
VAL_ 2566670334 Axle7MonitoredTireCount 15 "Not Available" ;
VAL_ 2566670334 Axle8MonitoredTireCount 15 "Not Available" ;
VAL_ 2566670334 Axle9MonitoredTireCount 15 "Not Available" ;
VAL_ 2566670334 Axle10MonitoredTireCount 15 "Not Available" ;
VAL_ 2566670334 Axle11MonitoredTireCount 15 "Not Available" ;
VAL_ 2566670334 Axle12MonitoredTireCount 15 "Not Available" ;
VAL_ 2566671102 SCRSystemCleaningLampCommand 0 "Off" 1 "On - solid" 2 "reserved for SAE assignment" 3 "reserved for SAE assignment" 4 "On - fast blink (1 HZ)" 5 "reserved for SAE assignment" 6 "reserved for SAE assignment" 7 "not available" ;
VAL_ 2566671102 SCRSystemCleaningStatus 0 "not active" 1 "active" 2 "SCR system cleaning is needed" 3 "not available" ;
VAL_ 2566671102 SCRSystemCleaningInhibitedStatus 0 "Not Inhibited" 1 "Inhibited" 2 "Reserved for SAE assignment" 3 "Not Available" ;
VAL_ 2566671102 SCRSystemCleaningInhbtdDTInhbtSw 0 "Not Inhibited" 1 "Inhibited" 2 "Reserved for SAE assignment" 3 "Not Available" ;
VAL_ 2566671102 SCRSysCleaningInhDTCltchDiseng 0 "Not Inhibited" 1 "Inhibited" 2 "Reserved for SAE assignment" 3 "Not Available" ;
VAL_ 2566671102 SCRSysCleaningInhbtdDTSrvcBrkAct 0 "Not Inhibited" 1 "Inhibited" 2 "Reserved for SAE assignment" 3 "Not Available" ;
VAL_ 2566671102 SCRSystemCleaningInhbtdDTPTOActv 0 "Not Inhibited" 1 "Inhibited" 2 "Reserved for SAE assignment" 3 "Not Available" ;
VAL_ 2566671102 SCRSysCleaningInhDTAcclPdlOffIdl 0 "Not Inhibited" 1 "Inhibited" 2 "Reserved for SAE assignment" 3 "Not Available" ;
VAL_ 2566671102 SCRSysCleaningInhbtdDTOutOfNtrl 0 "Not Inhibited" 1 "Inhibited" 2 "Reserved for SAE assignment" 3 "Not Available" ;
VAL_ 2566671102 SCRSysClnInhDTVhclSpdAbvAllwdSpd 0 "Not Inhibited" 1 "Inhibited" 2 "Reserved for SAE assignment" 3 "Not Available" ;
VAL_ 2566671102 SCRSysCleaningInhDTPrkBrkNotSet 0 "Not Inhibited" 1 "Inhibited" 2 "Reserved for SAE assignment" 3 "Not Available" ;
VAL_ 2566671102 SCRSysCleaningInhDTLowExhstTemp 0 "Not Inhibited" 1 "Inhibited" 2 "Reserved for SAE assignment" 3 "Not Available" ;
VAL_ 2566671102 SCRSysCleaningInhDTSysFaultAct 0 "Not Inhibited" 1 "Inhibited" 2 "Reserved for SAE assignment" 3 "Not Available" ;
VAL_ 2566671102 SCRSysCleaningInhbtdDTSysTimeout 0 "Not Inhibited" 1 "Inhibited" 2 "Reserved for SAE assignment" 3 "Not Available" ;
VAL_ 2566671102 SCRSysCleaningInhDTTmprySysLckt 0 "Not Inhibited" 1 "Inhibited" 2 "Reserved for SAE assignment" 3 "Not Available" ;
VAL_ 2566671102 SCRSysCleaningInhDTPrmntSysLckt 0 "Not Inhibited" 1 "Inhibited" 2 "Reserved for SAE assignment" 3 "Not Available" ;
VAL_ 2566671102 SCRSysCleangInhDTEngNotWarmedUp 0 "Not Inhibited" 1 "Inhibited" 2 "Reserved for SAE assignment" 3 "Not Available" ;
VAL_ 2566671102 SCRSysCleangInhDTVehicleSpeed 0 "Not Inhibited" 1 "Inhibited" 2 "Reserved for SAE assignment" 3 "Not Available" ;
VAL_ 2566671102 SCRSystemCleaningAutoInitConf 0 "not enabled" 1 "enabled" 2 "reserved for SAE assignment" 3 "not available" ;
VAL_ 2566671102 SCRSystemCleaningForcedStatus 0 "Not Active" 1 "Active - Forced by Switch (See SPN 3696)" 2 "Active - Forced by Service Tool" 3 "Reserved for SAE Assignment" 4 "Reserved for SAE Assignment" 5 "Reserved for SAE Assignment" 6 "Reserved for SAE Assignment" 7 "not available" ;
VAL_ 2566671102 Aft1SCRSysCondtnsNotMetActCleang 0 "SCR System Cleaning not Inhibited" 1 "SCR System Cleaning Inhibited" 2 "Reserved for SAE Assignment" 3 "Not available" ;
VAL_ 2566671614 SCROperatorIndcmntOverrideEnbl 0 "Override not allowed" 1 "Override allowed" 2 "SAE Reserved" 3 "Not available" ;
VAL_ 2566672382 PayloadWeightSensor1Status 0 "Sensor fully functional" 1 "Sensor degraded" 2 "Error (Sensor failed)" 3 "Not available" ;
VAL_ 2566672382 PayloadWeightSensor2Status 0 "Sensor fully functional" 1 "Sensor degraded" 2 "Error (Sensor failed)" 3 "Not available" ;
VAL_ 2566672382 PayloadWeightSensor3Status 0 "Sensor fully functional" 1 "Sensor degraded" 2 "Error (Sensor failed)" 3 "Not available" ;
VAL_ 2566672382 PayloadWeightSensor4Status 0 "Sensor fully functional" 1 "Sensor degraded" 2 "Error (Sensor failed)" 3 "Not available" ;
VAL_ 2566672382 PayloadWeightSensor5Status 0 "Sensor fully functional" 1 "Sensor degraded" 2 "Error (Sensor failed)" 3 "Not available" ;
VAL_ 2566672382 PayloadWeightSensor6Status 0 "Sensor fully functional" 1 "Sensor degraded" 2 "Error (Sensor failed)" 3 "Not available" ;
VAL_ 2566672382 PayloadWeightSensor7Status 0 "Sensor fully functional" 1 "Sensor degraded" 2 "Error (Sensor failed)" 3 "Not available" ;
VAL_ 2566672382 PayloadWeightSensor8Status 0 "Sensor fully functional" 1 "Sensor degraded" 2 "Error (Sensor failed)" 3 "Not available" ;
VAL_ 2566672638 HaulModeStatus 0 "Not in Haul Mode" 1 "Loading" 2 "Approaching Loaded" 3 "Loaded" 4 "Unloading" 5 "Unloaded" 7 "Reserved for Future Assignment by SAE" 14 "Error" 15 "Not Available" ;
VAL_ 2566672638 PayloadDeliveryTransactionStatus 0 "Transaction Not In Progress" 1 "Transaction In Progress" 2 "Transaction Complete" 3 "Reserved for Future Assignment by SAE" 14 "Error" 15 "Not Available" ;
VAL_ 2365346302 LiftAxle1Status 0 "Down" 1 "Unloading" 2 "Lifting" 3 "Up" 4 "Lowering" 5 "Loading" 6 "Error" 7 "Not available" ;
VAL_ 2365346302 LiftAxle2Status 0 "Down" 1 "Unloading" 2 "Lifting" 3 "Up" 4 "Lowering" 5 "Loading" 6 "Error" 7 "Not available" ;
VAL_ 2365346302 LiftAxle3Status 0 "Down" 1 "Unloading" 2 "Lifting" 3 "Up" 4 "Lowering" 5 "Loading" 6 "Error" 7 "Not available" ;
VAL_ 2365346302 LiftAxle4Status 0 "Down" 1 "Unloading" 2 "Lifting" 3 "Up" 4 "Lowering" 5 "Loading" 6 "Error" 7 "Not available" ;
VAL_ 2633782014 BinWeighingErrorStatus 0 "No error" 1 "Bad lift cycle" 2 "Weighing error" 3 "Weighing error" 4 "Reserved" 7 "Not available / not applicable" ;
VAL_ 2365348350 EngineUnloadStatus 0 "Not Requested" 1 "Requested" 2 "Error" 3 "Not Available" ;
VAL_ 2365348350 EngineLoadShareStatus 0 "Offline" 1 "Master" 2 "Slave" 3 "Loading" 4 "Unloading" 5 "Reserved" 14 "Error" 15 "Unavailable" ;
VAL_ 2566687742 Aft1PrticulateSnsrDetctnStat 0 "Initialization for particulate matter detection" 1 "Waiting for dew point" 2 "Particulate matter detection" 3 "Heater is active for particulate sensor regeneration" 4 "Cooling after particulate sensor regeneration" 5 "Heater diagnostics test" 6 "Relearning particulate sensor resistance after particulate sensor regeneration" 7 "Sensor regeneration did not complete due to system parameters out of range" 8 "Halt particulate matter detection" 9 "SAE Reserved" 15 "Not supported" ;
VAL_ 2566687742 Aft1PrticulateSnsrPwrSupply 0 "Off" 1 "On" 2 "Error" 3 "Unavailable" ;
VAL_ 2566687998 Aftrtrtmnt1PrticulateSnsrHtrStat 0 "Heater is in closed loop control" 1 "Heater is being held at a specified level" 2 "Heater is in ramp up mode" 3 "Heater is off" ;
VAL_ 2566687998 Aft1PrticulateSnsrRegenStatus 0 "Regeneration has not completed during this power cycle" 1 "Regeneration was successful" 2 "Regeneration failed" 3 "Not available" ;
VAL_ 2566687998 Aft1PrticulateSnsrRegenState 0 "Regeneration is not active" 1 "Regneration is active and has been initiated by request via SPN 6783" 2 "Regeneration is active and has been initiated because of sensor conditions" 3 "Regeneration is active and has been initiated due to time based conditions" 4 "SAE Reserved" 15 "Not Available" ;
VAL_ 2566689278 EngExhaustNOxSensorPowerSupply 0 "Off" 1 "On" 2 "Error" 3 "Unavailable" ;
VAL_ 2566690046 AftDslExhstFldDosCldownCoThsCycl 0 "Not complete" 1 "Complete" 2 "Error" 3 "Not Supported" ;
VAL_ 2566690046 AftDslExhstFldDosCldownCoLstCycl 0 "Not complete" 1 "Complete" 2 "Error" 3 "Not Supported" ;
VAL_ 2566690046 AftDslExhstFldDosPrgeCompThsCycl 0 "Not complete" 1 "Complete" 2 "Error" 3 "Not Supported" ;
VAL_ 2566690046 AftDslExhstFldDosPrgeCompLstCycl 0 "Not complete" 1 "Complete" 2 "Error" 3 "Not Supported" ;
VAL_ 2566690046 AfterRunCompleteThisCycle 0 "Not complete" 1 "Complete" 2 "Error" 3 "Not Supported" ;
VAL_ 2566690814 RequestedSteeringMode 0 "2 Wheel Steer Mode" 1 "Circle Steer Mode" 2 "Reserved for future use" 3 "Crab Steer Mode" 4 "Reserved for future use" 5 "Reserved for future use" 6 "Error" 7 "Not Available" ;
VAL_ 2566690814 FrontSteeringAxleCenteredStatus 0 "Front Axle Centered" 1 "Front Axle Not Centered" 2 "Error" 3 "Not Available" ;
VAL_ 2566690814 RearSteeringAxleCenteredStatus 0 "Rear Axle Centered" 1 "Rear Axle Not Centered" 2 "Error" 3 "Not Available" ;
VAL_ 2566690814 WheelSteerActuatorState 0 "2 Wheel Steer actuator inactive" 1 "2 Wheel Steer actuator active" 2 "Error" 3 "Not Available" ;
VAL_ 2566690814 WheelSteerActuatorState 0 "4 Wheel Steer actuator inactive" 1 "4 Wheel Steer actuator active" 2 "Error" 3 "Not Available" ;
VAL_ 2566690814 CircleSteerModeActuatorState 0 "Circle Steer Mode actuator inactive" 1 "Circle Steer Mode actuator active" 2 "Error" 3 "Not Available" ;
VAL_ 2566690814 CrabSteerModeActuatorState 0 "Crab Steer Mode actuator inactive" 1 "Crab Steer Mode actuator active" 2 "Error" 3 "Not Available" ;
VAL_ 2566690814 SteeringModeTwoWheelSwitchInput 0 "Off" 1 "On" 2 "Error" 3 "Not available" ;
VAL_ 2566690814 SteeringModeCrabSwitchInput 0 "Off" 1 "On" 2 "Error" 3 "Not available" ;
VAL_ 2566690814 SteeringModeCircleSwitchInput 0 "Off" 1 "On" 2 "Error" 3 "Not available" ;
VAL_ 2566690814 SteeringModeStatus 0 "2 Wheel Steer Mode" 1 "Circle Steer Mode" 2 "Reserved for future use" 3 "Crab Steer Mode" 4 "Reserved for future use" 5 "Reserved for future use" 6 "Error" 7 "Not Available" ;
VAL_ 2499582206 SoftTopSpeedLimitActive 0 "Soft Top Speed Limit is Inactive" 1 "Soft Top Speed Limit is Active" 2 "Reserved" 3 "Not Available" ;
VAL_ 2499582206 SoftTopRatioLimitExceeded 0 "Soft top ratio limit has not been exceeded" 1 "Soft top ratio limit has been exceeded" 2 "Reserved" 3 "Not Available" ;
VAL_ 2566691582 Joystick3Lamp1Status 0 "Off" 1 "On" 2 "Flashing" 3 "Not available" ;
VAL_ 2566691582 Joystick3Lamp2Status 0 "Off" 1 "On" 2 "Flashing" 3 "Not available" ;
VAL_ 2566691582 Joystick3Lamp3Status 0 "Off" 1 "On" 2 "Flashing" 3 "Not available" ;
VAL_ 2566691582 Joystick3Lamp4Status 0 "Off" 1 "On" 2 "Flashing" 3 "Not available" ;
VAL_ 2566691582 Joystick3Lamp5Status 0 "Off" 1 "On" 2 "Flashing" 3 "Not available" ;
VAL_ 2566691582 Joystick3Lamp6Status 0 "Off" 1 "On" 2 "Flashing" 3 "Not available" ;
VAL_ 2566691582 Joystick3Lamp7Status 0 "Off" 1 "On" 2 "Flashing" 3 "Not available" ;
VAL_ 2566691582 Joystick3Lamp8Status 0 "Off" 1 "On" 2 "Flashing" 3 "Not available" ;
VAL_ 2566691582 Joystick3Lamp9Status 0 "Off" 1 "On" 2 "Flashing" 3 "Not available" ;
VAL_ 2566691582 Joystick3Lamp10Status 0 "Off" 1 "On" 2 "Flashing" 3 "Not available" ;
VAL_ 2566691838 Joystick2Lamp1Status 0 "Off" 1 "On" 2 "Flashing" 3 "Not available" ;
VAL_ 2566691838 Joystick2Lamp2Status 0 "Off" 1 "On" 2 "Flashing" 3 "Not available" ;
VAL_ 2566691838 Joystick2Lamp3Status 0 "Off" 1 "On" 2 "Flashing" 3 "Not available" ;
VAL_ 2566691838 Joystick2Lamp4Status 0 "Off" 1 "On" 2 "Flashing" 3 "Not available" ;
VAL_ 2566691838 Joystick2Lamp5Status 0 "Off" 1 "On" 2 "Flashing" 3 "Not available" ;
VAL_ 2566691838 Joystick2Lamp6Status 0 "Off" 1 "On" 2 "Flashing" 3 "Not available" ;
VAL_ 2566691838 Joystick2Lamp7Status 0 "Off" 1 "On" 2 "Flashing" 3 "Not available" ;
VAL_ 2566691838 Joystick2Lamp8Status 0 "Off" 1 "On" 2 "Flashing" 3 "Not available" ;
VAL_ 2566691838 Joystick2Lamp9Status 0 "Off" 1 "On" 2 "Flashing" 3 "Not available" ;
VAL_ 2566691838 Joystick2Lamp10Status 0 "Off" 1 "On" 2 "Flashing" 3 "Not available" ;
VAL_ 2566692094 Joystick1Lamp1Status 1 "On" 2 "Flashing" 3 "Not available" ;
VAL_ 2566692094 Joystick1Lamp2Status 0 "Off" 1 "On" 2 "Flashing" 3 "Not available" ;
VAL_ 2566692094 Joystick1Lamp3Status 0 "Off" 1 "On" 2 "Flashing" 3 "Not available" ;
VAL_ 2566692094 Joystick1Lamp4Status 1 "On" 2 "Flashing" 3 "Not available" ;
VAL_ 2566692094 Joystick1Lamp5Status 0 "Off" 1 "On" 2 "Flashing" 3 "Not available" ;
VAL_ 2566692094 Joystick1Lamp6Status 0 "Off" 1 "On" 2 "Flashing" 3 "Not available" ;
VAL_ 2566692094 Joystick1Lamp7Status 0 "Off" 1 "On" 2 "Flashing" 3 "Not available" ;
VAL_ 2566692094 Joystick1Lamp8Status 0 "Off" 1 "On" 2 "Flashing" 3 "Not available" ;
VAL_ 2566692094 Joystick1Lamp9Status 0 "Off" 1 "On" 2 "Flashing" 3 "Not available" ;
VAL_ 2566692094 Joystick1Lamp10Status 0 "Off" 1 "On" 2 "Flashing" 3 "Not available" ;
VAL_ 2499583486 EngineTimingActr1PositionCommand 0 "Reserved" 1 "Diesel Mode Position" 2 "Diesel Part Load Position" 3 "Gas Mode Position" 4 "Diesel Part Load / Gas Mode Position" 5 "Reserved" 7 "Not Available" ;
VAL_ 2499583486 EngineTimingActr2PositionCommand 0 "Reserved" 1 "Diesel Mode Position" 2 "Diesel Part Load Position" 3 "Gas Mode Position" 4 "Diesel Part Load / Gas Mode Position" 5 "Reserved" 7 "Not Available" ;
VAL_ 2499583742 EngineTimingActuator1 0 "Unknown Position" 1 "Diesel Mode Position" 2 "Diesel Part Load Position" 3 "Gas Mode Position" 4 "Diesel Part Load / Gas Mode Position" 5 "Reserved" 7 "Not Available" ;
VAL_ 2499583742 EngineTimingActuator2 0 "Unknown Position" 1 "Diesel Mode Position" 2 "Diesel Part Load Position" 3 "Gas Mode Position" 4 "Diesel Part Load / Gas Mode Position" 5 "Reserved" 7 "Not Available" ;
VAL_ 2499583742 EngTimingActr1RequestedPosition 0 "Position Not Requested" 1 "Diesel Mode Position" 2 "Diesel Part Load Position" 3 "Gas Mode Position" 4 "Diesel Part Load / Gas Mode Position" 5 "Reserved" 7 "Not Available" ;
VAL_ 2499583742 EngTimingActr2RequestedPosition 0 "Position Not Requested" 1 "Diesel Mode Position" 2 "Diesel Part Load Position" 3 "Gas Mode Position" 4 "Diesel Part Load / Gas Mode Position" 5 "Reserved" 7 "Not Available" ;
VAL_ 2566692862 DisplayRemainPowered 0 "OK to Shutoff" 1 "Remain Powered" 2 "Reserved" 3 "Don't care" ;
VAL_ 2566697470 EngineIgnitionCtrlModule1State 0 "Disabled (by user)" 1 "Shutdown (due to alarm)" 2 "Stalled (waiting for timing signals)" 3 "Firing Ignition in Test Mode" 4 "Firing Ignition in Normal Mode" 5 "Reserved" 6 "Error" 7 "Not available" ;
VAL_ 2566697470 EngineIgnitionCtrlModule2State 0 "Disabled (by user)" 1 "Shutdown (due to alarm)" 2 "Stalled (waiting for timing signals)" 3 "Firing Ignition in Test Mode" 4 "Firing Ignition in Normal Mode" 5 "Reserved" 6 "Error" 7 "Not available" ;
VAL_ 2566698238 SwitchedOutput4 0 "Output off" 1 "Output on" 2 "Reserved" 3 "Take no action" ;
VAL_ 2566698238 SwitchedOutput3 0 "Output off" 1 "Output on" 2 "Reserved" 3 "Take no action" ;
VAL_ 2566698238 SwitchedOutput2 0 "Output off" 1 "Output on" 2 "Reserved" 3 "Take no action" ;
VAL_ 2566698238 SwitchedOutput1 0 "Output off" 1 "Output on" 2 "Reserved" 3 "Take no action" ;
VAL_ 2566698238 SwitchedOutput8 0 "Output off" 1 "Output on" 2 "Reserved" 3 "Take no action" ;
VAL_ 2566698238 SwitchedOutput7 0 "Output off" 1 "Output on" 2 "Reserved" 3 "Take no action" ;
VAL_ 2566698238 SwitchedOutput6 0 "Output off" 1 "Output on" 2 "Reserved" 3 "Take no action" ;
VAL_ 2566698238 SwitchedOutput5 0 "Output off" 1 "Output on" 2 "Reserved" 3 "Take no action" ;
VAL_ 2566698238 SwitchedOutput12 0 "Output off" 1 "Output on" 2 "Reserved" 3 "Take no action" ;
VAL_ 2566698238 SwitchedOutput11 0 "Output off" 1 "Output on" 2 "Reserved" 3 "Take no action" ;
VAL_ 2566698238 SwitchedOutput10 0 "Output off" 1 "Output on" 2 "Reserved" 3 "Take no action" ;
VAL_ 2566698238 SwitchedOutput9 0 "Output off" 1 "Output on" 2 "Reserved" 3 "Take no action" ;
VAL_ 2566698238 SwitchedOutput16 0 "Output off" 1 "Output on" 2 "Reserved" 3 "Take no action" ;
VAL_ 2566698238 SwitchedOutput15 0 "Output off" 1 "Output on" 2 "Reserved" 3 "Take no action" ;
VAL_ 2566698238 SwitchedOutput14 0 "Output off" 1 "Output on" 2 "Reserved" 3 "Take no action" ;
VAL_ 2566698238 SwitchedOutput13 0 "Output off" 1 "Output on" 2 "Reserved" 3 "Take no action" ;
VAL_ 2566698238 SwitchedOutput20 0 "Output off" 1 "Output on" 2 "Reserved" 3 "Take no action" ;
VAL_ 2566698238 SwitchedOutput19 0 "Output off" 1 "Output on" 2 "Reserved" 3 "Take no action" ;
VAL_ 2566698238 SwitchedOutput18 0 "Output off" 1 "Output on" 2 "Reserved" 3 "Take no action" ;
VAL_ 2566698238 SwitchedOutput17 0 "Output off" 1 "Output on" 2 "Reserved" 3 "Take no action" ;
VAL_ 2566698238 SwitchedOutput24 0 "Output off" 1 "Output on" 2 "Reserved" 3 "Take no action" ;
VAL_ 2566698238 SwitchedOutput23 0 "Output off" 1 "Output on" 2 "Reserved" 3 "Take no action" ;
VAL_ 2566698238 SwitchedOutput22 0 "Output off" 1 "Output on" 2 "Reserved" 3 "Take no action" ;
VAL_ 2566698238 SwitchedOutput21 0 "Output off" 1 "Output on" 2 "Reserved" 3 "Take no action" ;
VAL_ 2566698238 SwitchedOutput28 0 "Output off" 1 "Output on" 2 "Reserved" 3 "Take no action" ;
VAL_ 2566698238 SwitchedOutput27 0 "Output off" 1 "Output on" 2 "Reserved" 3 "Take no action" ;
VAL_ 2566698238 SwitchedOutput26 0 "Output off" 1 "Output on" 2 "Reserved" 3 "Take no action" ;
VAL_ 2566698238 SwitchedOutput25 0 "Output off" 1 "Output on" 2 "Reserved" 3 "Take no action" ;
VAL_ 2566698238 SwitchedOutput32 0 "Output off" 1 "Output on" 2 "Reserved" 3 "Take no action" ;
VAL_ 2566698238 SwitchedOutput31 0 "Output off" 1 "Output on" 2 "Reserved" 3 "Take no action" ;
VAL_ 2566698238 SwitchedOutput30 0 "Output off" 1 "Output on" 2 "Reserved" 3 "Take no action" ;
VAL_ 2566698238 SwitchedOutput29 0 "Output off" 1 "Output on" 2 "Reserved" 3 "Take no action" ;
VAL_ 2566698494 FusedOutput4 0 "Output not powered" 1 "Output powered" 2 "Reserved" 3 "Take no action" ;
VAL_ 2566698494 FusedOutput3 0 "Output not powered" 1 "Output powered" 2 "Reserved" 3 "Take no action" ;
VAL_ 2566698494 FusedOutput2 0 "Output not powered" 1 "Output powered" 2 "Reserved" 3 "Take no action" ;
VAL_ 2566698494 FusedOutput1 0 "Output not powered" 1 "Output powered" 2 "Reserved" 3 "Take no action" ;
VAL_ 2566698494 FusedOutput8 0 "Output not powered" 1 "Output powered" 2 "Reserved" 3 "Take no action" ;
VAL_ 2566698494 FusedOutput7 0 "Output not powered" 1 "Output powered" 2 "Reserved" 3 "Take no action" ;
VAL_ 2566698494 FusedOutput6 0 "Output not powered" 1 "Output powered" 2 "Reserved" 3 "Take no action" ;
VAL_ 2566698494 FusedOutput5 0 "Output not powered" 1 "Output powered" 2 "Reserved" 3 "Take no action" ;
VAL_ 2566698494 FusedOutput12 0 "Output not powered" 1 "Output powered" 2 "Reserved" 3 "Take no action" ;
VAL_ 2566698494 FusedOutput11 0 "Output not powered" 1 "Output powered" 2 "Reserved" 3 "Take no action" ;
VAL_ 2566698494 FusedOutput10 0 "Output not powered" 1 "Output powered" 2 "Reserved" 3 "Take no action" ;
VAL_ 2566698494 FusedOutput9 0 "Output not powered" 1 "Output powered" 2 "Reserved" 3 "Take no action" ;
VAL_ 2566698494 FusedOutput16 0 "Output not powered" 1 "Output powered" 2 "Reserved" 3 "Take no action" ;
VAL_ 2566698494 FusedOutput15 0 "Output not powered" 1 "Output powered" 2 "Reserved" 3 "Take no action" ;
VAL_ 2566698494 FusedOutput14 0 "Output not powered" 1 "Output powered" 2 "Reserved" 3 "Take no action" ;
VAL_ 2566698494 FusedOutput13 0 "Output not powered" 1 "Output powered" 2 "Reserved" 3 "Take no action" ;
VAL_ 2566698494 FusedOutput20 0 "Output not powered" 1 "Output powered" 2 "Reserved" 3 "Take no action" ;
VAL_ 2566698494 FusedOutput19 0 "Output not powered" 1 "Output powered" 2 "Reserved" 3 "Take no action" ;
VAL_ 2566698494 FusedOutput18 0 "Output not powered" 1 "Output powered" 2 "Reserved" 3 "Take no action" ;
VAL_ 2566698494 FusedOutput17 0 "Output not powered" 1 "Output powered" 2 "Reserved" 3 "Take no action" ;
VAL_ 2566698494 FusedOutput24 0 "Output not powered" 1 "Output powered" 2 "Reserved" 3 "Take no action" ;
VAL_ 2566698494 FusedOutput23 0 "Output not powered" 1 "Output powered" 2 "Reserved" 3 "Take no action" ;
VAL_ 2566698494 FusedOutput22 0 "Output not powered" 1 "Output powered" 2 "Reserved" 3 "Take no action" ;
VAL_ 2566698494 FusedOutput21 0 "Output not powered" 1 "Output powered" 2 "Reserved" 3 "Take no action" ;
VAL_ 2566698494 FusedOutput28 0 "Output not powered" 1 "Output powered" 2 "Reserved" 3 "Take no action" ;
VAL_ 2566698494 FusedOutput27 0 "Output not powered" 1 "Output powered" 2 "Reserved" 3 "Take no action" ;
VAL_ 2566698494 FusedOutput26 0 "Output not powered" 1 "Output powered" 2 "Reserved" 3 "Take no action" ;
VAL_ 2566698494 FusedOutput25 0 "Output not powered" 1 "Output powered" 2 "Reserved" 3 "Take no action" ;
VAL_ 2566698494 FusedOutput32 0 "Output not powered" 1 "Output powered" 2 "Reserved" 3 "Take no action" ;
VAL_ 2566698494 FusedOutput31 0 "Output not powered" 1 "Output powered" 2 "Reserved" 3 "Take no action" ;
VAL_ 2566698494 FusedOutput30 0 "Output not powered" 1 "Output powered" 2 "Reserved" 3 "Take no action" ;
VAL_ 2566698494 FusedOutput29 0 "Output not powered" 1 "Output powered" 2 "Reserved" 3 "Take no action" ;
VAL_ 2566699774 Aft2DslExhstFldCtrlMdulRelayCtrl 0 "Off" 1 "On" 2 "Error" 3 "Unavailable" ;
VAL_ 2566699774 Aft2DslExhstFldCtrlMdulPwrSupply 0 "Off" 1 "On" 2 "Error" 3 "Unavailable" ;
VAL_ 2566699774 Aft2DslExhstFldCtrlMdulPwrSuply2 0 "Off" 1 "On" 2 "Error" 3 "Unavailable" ;
VAL_ 2566699774 Aft2DslExhstFldCtrlMdulCircBrkr 0 "Off" 1 "On" 2 "Error" 3 "Not available" ;
VAL_ 2566699774 Aft2DslExhstFldCtrlMdul2RelyCtrl 0 "Off" 1 "On" 2 "Error" 3 "Unavailable" ;
VAL_ 2566699774 Aft2DslExhstFldCtrlMdul2PwrSupp1 0 "Off" 1 "On" 2 "Error" 3 "Unavailable" ;
VAL_ 2566699774 Aft2DslExhstFldCtrlMdul2PwrSupp2 0 "Off" 1 "On" 2 "Error" 3 "Unavailable" ;
VAL_ 2566700030 Aft1DslExhstFldCtrlMdulRelayCtrl 0 "Off" 1 "On" 2 "Error" 3 "Unavailable" ;
VAL_ 2566700030 Aft1DslExhstFldCtrlMdulPwrSupply 0 "Off" 1 "On" 2 "Error" 3 "Unavailable" ;
VAL_ 2566700030 Aft1DslExhstFldCtrlMdulPwrSuply2 0 "Off" 1 "On" 2 "Error" 3 "Unavailable" ;
VAL_ 2566700030 Aft1DslExhstFldCtrlMdulCircBrkr 0 "Off" 1 "On" 2 "Error" 3 "Not available" ;
VAL_ 2566700030 Aft1DslExhstFldCtrlMdul2RelyCtrl 0 "Off" 1 "On" 2 "Error" 3 "Unavailable" ;
VAL_ 2566700030 Aft1DslExhstFldCtrlMdul2PwrSupp1 0 "Off" 1 "On" 2 "Error" 3 "Unavailable" ;
VAL_ 2566700030 Aft1DslExhstFldCtrlMdul2PwrSupp2 0 "Off" 1 "On" 2 "Error" 3 "Unavailable" ;
VAL_ 2499592190 TrnsmCltch1CoolingActrStat 0 "Off" 1 "On" 2 "Error" 3 "Not available" ;
VAL_ 2499592190 TrnsmCltch2CoolingActrStat 0 "Off" 1 "On" 2 "Error" 3 "Not available" ;
VAL_ 2499592190 TransmissionShiftRail1ActrStatus 0 "Off" 1 "On" 2 "Error" 3 "Not available" ;
VAL_ 2499592190 TransmissionShiftRail2ActrStatus 0 "Off" 1 "On" 2 "Error" 3 "Not available" ;
VAL_ 2499592190 TransmissionShiftRail3ActrStatus 0 "Off" 1 "On" 2 "Error" 3 "Not available" ;
VAL_ 2499592190 TransmissionShiftRail4ActrStatus 0 "Off" 1 "On" 2 "Error" 3 "Not available" ;
VAL_ 2499592190 TransmissionShiftRail5ActrStatus 0 "Off" 1 "On" 2 "Error" 3 "Not available" ;
VAL_ 2499592190 TransmissionShiftRail6ActrStatus 0 "Off" 1 "On" 2 "Error" 3 "Not available" ;
VAL_ 2566701822 HybridSystemWarningIndicator 0 "Hybrid System Warning Indicator is off" 1 "Hybrid System Warning Indicator is on continuously" 2 "Hybrid System Warning Indicator is flashing" 3 "Not available" ;
VAL_ 2566701822 HybridSystemOverheatIndicator 0 "Hybrid System Temperature Indicator is off" 1 "Hybrid System Temperature Indicator is on continuously" 2 "Hybrid System Temperature Indicator is flashing" 3 "Not available" ;
VAL_ 2566701822 HybridSystemStopIndicator 0 "Hybrid System Stop Indicator is off" 1 "Hybrid System Stop Indicator is on continuously" 2 "Hybrid System Stop Indicator is flashing" 3 "Not available" ;
VAL_ 2566701822 HybridSystemOBDRelatedDTCStatus 0 "Hybrid System does not have an active OBD related DTC" 1 "Hybrid System has an active OBD related DTC" 2 "SAE Reserved" 3 "Not available" ;
VAL_ 2566701822 PropulsionSystemActive 0 "Propulsion System is not ready to move vehicle if commanded by operator" 1 "Propulsion System is ready to move, or is moving the vehicle as commanded by operator" 2 "SAE Reserved" 3 "Not Available" ;
VAL_ 2566701822 HybridSystemEngineAssistStatus 0 "Hybrid system is not mechanically assisting engine rotation" 1 "Hybrid system may or may not mechanically assist engine rotation" 2 "Error" 3 "Not Available" ;
VAL_ 2566701822 HybridSystemServiceIndicator 0 "Hybrid Service Indicator is off" 1 "Hybrid Service Indicator is on continously" 2 "Hybrid Service Indicator is flashing" 3 "Not Available" ;
VAL_ 2566701822 HybridSystemMtrOverspeedIndictr 0 "Hybrid System Motor Overspeed Indicator is off" 1 "Hybrid System Motor Overspeed Indicator is on continously" 2 "Hybrid System Motor Overspeed Indicator is flashing" 3 "Not Available" ;
VAL_ 2566701822 HybridSysMtrOverspdAudibleAlarm 0 "Motor Overspeed Audible Alarm is off" 1 "Motor Overspeed Audible Alarm is on" 2 "Error" 3 "Not Available" ;
VAL_ 2566701822 HybridSysElectricAltrntrIndictr 0 "Alternator Indicator is off" 1 "Alternator Indicator is on" 2 "Alternator Indicator is flashing" 3 "Not Available" ;
VAL_ 2566701822 HybridSystemRegativeBrkngIndictr 0 "Regenerative braking is inactive" 1 "Regenerative braking is active" 2 "Regenerative braking is disabled" 3 "Not Available" ;
VAL_ 2566701822 HybridSystemInitIndictr 0 "System Initialization Indicator is not active" 1 "System Initialization Indicator is active" 2 "Error" 3 "Not Available" ;
VAL_ 2566701822 HybridSysHghVltgExposureIndictr 0 "System is operational and intact" 1 "System is operational and has detected a compromise" 2 "Error" 3 "Not Available" ;
VAL_ 2566701822 StoredEnergySourceOnlyModeAllwd 0 "Mode NOT allowed" 1 "Mode allowed" 2 "Error" 3 "Not available" ;
VAL_ 2566701822 StoredEnergySrcIncreasngMdeAllwd 0 "Mode NOT allowed" 1 "Mode allowed" 2 "Error" 3 "Not available" ;
VAL_ 2566701822 HybridPropulsionModeStatus 0 "No mode requested" 1 "Stored Energy Source Sustaining" 2 "Stored Energy Source Increasing" 3 "Stored Energy Source Depleting" 4 "Stored Energy Source Offline" 5 "Stored Energy Source Only" 6 "Reserved" 14 "Error" 15 "Not Available" ;
VAL_ 2566701822 HybridProplsnMdeTransitionStatus 0 "No transition requested" 1 "Transition requested and in process" 2 "Requested mode denied - Requested mode not available" 3 "Requested mode denied - Vehicle Speed unacceptable for requested mode" 4 "Requested mode denied - HVES State of Charge unacceptable for requested mode" 5 "Requested mode denied - Temporary limit exceeded" 6 "Requested mode denied - HVES temporary limit threshold exceeded for one or more HVES" 7 "Reserved" 13 "Requested mode denied- reason not specified" 14 "Error" 15 "Not available" ;
VAL_ 2566701822 ExtEnergySourceConnectnStatus 0 "No Connection" 1 "Connection 1 - Error (Verification failed)" 2 "Connection 1 - Verification in Process" 3 "Connection 1 - Energy Source and Drain" 4 "Connection 1 - Energy Source" 5 "Connection 1 - Energy Drain" 6 "Connection 2 - Error (Verification failed)" 7 "Connection 2 - Verification in Process" 8 "Connection 2 - Energy Source and Drain" 9 "Connection 2 - Energy Source" 10 "Connection 2 - Energy Drain" 11 "Reserved" 14 "Error" 15 "Not Available" ;
VAL_ 2566701822 HybridSystemProplsnDisablStatus 0 "Propulsion not disabled" 1 "Propulsion is disabled" 2 "Error" 3 "Not Available" ;
VAL_ 2566702846 EngineOBDWarmUpSequence 0 "Warm-up cycle not occurred" 1 "Warm-up cycle occurred" 2 "SAE reserved" 3 "Not supported or not available" ;
VAL_ 2566703358 FeedbackEngineFuelingState 0 "Fueling inhibited" 1 "Engine kept running" 2 "No active request" 3 "Not Supported" ;
VAL_ 2566703358 EngineFuelingInhibitAllowed 0 "Engine not stop fueling" 1 "Engine stop fueling" 2 "SAE Reserved" 3 "Not Supported" ;
VAL_ 2566703358 EngFuelingInhibitPreventedReason 0 "Fueling inhibit allowed" 1 "Aftertreatment regeneration is active or preparing to be active" 2 "Oil Distribution in engine is incomplete" 3 "Engine is cold" 4 "Service Override" 5 "Aftertreatment system is cold" 6 "Aftertreatment Protection" 7 "Engine load too high" 8 "Engine protection" 9 "Insufficient SLI battery charge" 10 "Maximum number of engine fueling inhibit requests temporary limit exceeded" 11 "Engine driven fan request" 12 "Low idle governor operation required" 13 "Vehicle speed is greater than zero" 14 "See Engine Fueling Inhibit Prevented Reason Extension" 15 "Not Supported" ;
VAL_ 2566703358 EngineDualFuelMode 0 "Actual dual fuel mode off" 1 "Actual dual fuel mode on" 2 "Reserved" 3 "Not available" ;
VAL_ 2566703358 EngFuelngInhbtPrevntdRsnExtsion 0 "Fueling inhibit allowed" 1 "Aftertreatment regeneration is active or preparing to be active" 2 "Oil Distribution in engine is incomplete" 3 "Engine is cold" 4 "Service Override" 5 "Aftertreatment system is cold" 6 "Aftertreatment Protection" 7 "Engine load too high" 8 "Engine protection" 9 "Insufficient SLI battery charge" 10 "Maximum number of engine fueling inhibit requests temporary limit exceeded" 11 "Engine driven fan request" 12 "Low idle governor operation required" 13 "Vehicle speed is greater than zero" 14 "Service brake pedal is not depressed" 15 "Parking brake is not applied" 16 "Transmission is in Reverse" 17 "Clutch pedal is not depressed" 18 "PTO is active" 19 "Stability/Slip Control event is active" 20 "Stability/Slip Control system has a fault" 21 "Interlock is active" 22 "Starter system has a fault" 23 "SAE Reserved" 63 "Not Supported" ;
VAL_ 2566703358 EngineFuelingInhibitRequestCount 0 "Number of active fueling requests" 11 "More than 10 active fueling requests" 12 "SAE Reserved" 15 "Not available" ;
VAL_ 2566703358 EngineFuelingDesiredRequestCount 0 "Number of active fueling requests" 11 "More than 10 active fueling requests" 12 "SAE Reserved" 15 "Not available" ;
VAL_ 2566703358 EngProtectionDerateOverrdStatus 0 "Override disabled" 1 "Override active" 2 "Error" 3 "Not Available" ;
VAL_ 2566703870 EngExhstGasRecirc2Actr1TempStat 0 "High Most severe" 1 "High Least severe" 2 "In Range" 3 "Low Least severe" 4 "Low Most severe" 5 "Not Defined" 6 "Error" 7 "Not available" ;
VAL_ 2566703870 EngExhstGasRecirc2Actr2TempStat 0 "High Most severe" 1 "High Least severe" 2 "In Range" 3 "Low Least severe" 4 "Low Most severe" 5 "Not Defined" 6 "Error" 7 "Not available" ;
VAL_ 2566703870 EngExhstGasRecirc2Actr1OpStatus 0 "Normal" 1 "Alarm" 2 "Alarm High Severity" 3 "Derate Active" 4 "Controlled Shutdown Active" 5 "Uncontrolled Shutdown Active" 6 "Reserved for future assignment" 14 "Error" 15 "Not available" ;
VAL_ 2566703870 EngExhstGasRecirc2Actr2OpStatus 0 "Normal" 1 "Alarm" 2 "Alarm High Severity" 3 "Derate Active" 4 "Controlled Shutdown Active" 5 "Uncontrolled Shutdown Active" 6 "Reserved for future assignment" 14 "Error" 15 "Not available" ;
VAL_ 2566704126 EngExhstGasRecirc1Actr1TempStat 0 "High Most severe" 1 "High Least severe" 2 "In Range" 3 "Low Least severe" 4 "Low Most severe" 5 "Not Defined" 6 "Error" 7 "Not available" ;
VAL_ 2566704126 EngExhstGasRecirc1Actr2TempStat 0 "High Most severe" 1 "High Least severe" 2 "In Range" 3 "Low Least severe" 4 "Low Most severe" 5 "Not Defined" 6 "Error" 7 "Not available" ;
VAL_ 2566704126 EngExhstGasRecirc1Actr1OpStatus 0 "Normal" 1 "Alarm" 2 "Alarm High Severity" 3 "Derate Active" 4 "Controlled Shutdown Active" 5 "Uncontrolled Shutdown Active" 6 "Reserved for future assignment" 14 "Error" 15 "Not available" ;
VAL_ 2566704126 EngExhstGasRecirc1Actr2OpStatus 0 "Normal" 1 "Alarm" 2 "Alarm High Severity" 3 "Derate Active" 4 "Controlled Shutdown Active" 5 "Uncontrolled Shutdown Active" 6 "Reserved for future assignment" 14 "Error" 15 "Not available" ;
VAL_ 2566704382 EngExhaust1GasSensor1PowerSupply 0 "Off" 1 "On" 2 "Error" 3 "Unavailable" ;
VAL_ 2566704382 Aftrtrtmnt1OtltGasSnsrPwrSupply 0 "Off" 1 "On" 2 "Error" 3 "Unavailable" ;
VAL_ 2566704382 EngExhaust2GasSensor1PowerSupply 0 "Off" 1 "On" 2 "Error" 3 "Unavailable" ;
VAL_ 2566704382 Aftrtrtmnt2OtltGasSnsrPwrSupply 0 "Off" 1 "On" 2 "Error" 3 "Unavailable" ;
VAL_ 2566704382 EngExhaust1GasSensor2PowerSupply 0 "Off" 1 "On" 2 "Error" 3 "Unavailable" ;
VAL_ 2566704382 Aftrtrtmnt1Otlt2GsSnsrPwrSupply 0 "Off" 1 "On" 2 "Error" 3 "Unavailable" ;
VAL_ 2566705150 Aft1OtltNOxSnsrSelfDiagssTrigger 0 "Diagnostic mode disabled" 1 "Request at Lambda=1.0" 2 "Request at partial load" 3 "Request at fuel cut" 4 "Request at After Run" 5 "Reserved" 15 "Not supported" ;
VAL_ 2566705150 EngExhst1IntkNOxSnsrSelfDiagTrg 0 "Diagnostic mode disabled" 1 "Request at Lambda=1.0" 2 "Request at partial load" 3 "Request at fuel cut" 4 "Request at after run" 5 "Reserved" 15 "Not supported" ;
VAL_ 2566705150 Aft2OtltNOxSnsrSelfDiagssTrigger 0 "Diagnostic mode disabled" 1 "Request at Lambda=1.0" 2 "Request at partial load" 3 "Request at fuel cut" 4 "Request at After Run" 5 "Reserved" 15 "Not supported" ;
VAL_ 2566705150 EngExhst2IntkNOxSnsrSelfDiagTrg 0 "Diagnostic mode disabled" 1 "Request at Lambda=1.0" 2 "Request at partial load" 3 "Request at fuel cut" 4 "Request at after run" 5 "Reserved" 15 "Not supported" ;
VAL_ 2566705662 ProtectLamp 0 "Lamp Off" 1 "Lamp On" 2 "Reserved" 3 "Not available" ;
VAL_ 2566705662 AmberWarningLamp 0 "Lamp Off" 1 "Lamp On" 2 "Reserved" 3 "Not available" ;
VAL_ 2566705662 RedStopLamp 0 "Lamp Off" 1 "Lamp On" 2 "Reserved" 3 "Not available" ;
VAL_ 2566705662 MalfunctionIndicatorLamp 0 "Lamp Off" 1 "Lamp On" 2 "Short MIL for WWH OBD" 3 "Not available" ;
VAL_ 2566705662 FlashProtectLamp 0 "Slow Flash (1 Hz, 50 % duty cycle)" 1 "Fast Flash (2 Hz or faster, 50% duty cycle)" 2 "Reserved" 3 "Unavailable / Do Not Flash" ;
VAL_ 2566705662 FlashAmberWarningLamp 0 "Slow Flash (1 Hz, 50 % duty cycle)" 1 "Fast Flash (2 Hz or faster, 50% duty cycle)" 2 "Reserved" 3 "Unavailable / Do Not Flash" ;
VAL_ 2566705662 FlashRedStopLamp 0 "Slow Flash (1 Hz, 50 % duty cycle)" 1 "Fast Flash (2 Hz or faster, 50% duty cycle)" 2 "Reserved" 3 "Unavailable / Do Not Flash" ;
VAL_ 2566705662 FlashMalfunctionIndicatorLamp 0 "Slow Flash (1 Hz, 50 % duty cycle)" 1 "Fast Flash (2 Hz or faster, 50% duty cycle)" 2 "Class C DTC" 3 "Unavailable / Do Not Flash" ;
VAL_ 2566705662 SPNConversionMethod 0 "Convert SPN per Version 4" 1 "Convert SPN per Version 1, 2 or 3" ;
VAL_ 2566705918 ProtectLamp 0 "Lamp Off" 1 "Lamp On" 2 "Reserved" 3 "Not available" ;
VAL_ 2566705918 AmberWarningLamp 0 "Lamp Off" 1 "Lamp On" 2 "Reserved" 3 "Not available" ;
VAL_ 2566705918 RedStopLamp 0 "Lamp Off" 1 "Lamp On" 2 "Reserved" 3 "Not available" ;
VAL_ 2566705918 MalfunctionIndicatorLamp 0 "Lamp Off" 1 "Lamp On" 2 "Short MIL for WWH OBD" 3 "Not available" ;
VAL_ 2566705918 FlashProtectLamp 0 "Slow Flash (1 Hz, 50 % duty cycle)" 1 "Fast Flash (2 Hz or faster, 50% duty cycle)" 2 "Reserved" 3 "Unavailable / Do Not Flash" ;
VAL_ 2566705918 FlashAmberWarningLamp 0 "Slow Flash (1 Hz, 50 % duty cycle)" 1 "Fast Flash (2 Hz or faster, 50% duty cycle)" 2 "Reserved" 3 "Unavailable / Do Not Flash" ;
VAL_ 2566705918 FlashRedStopLamp 0 "Slow Flash (1 Hz, 50 % duty cycle)" 1 "Fast Flash (2 Hz or faster, 50% duty cycle)" 2 "Reserved" 3 "Unavailable / Do Not Flash" ;
VAL_ 2566705918 FlashMalfunctionIndicatorLamp 0 "Slow Flash (1 Hz, 50 % duty cycle)" 1 "Fast Flash (2 Hz or faster, 50% duty cycle)" 2 "Class C DTC" 3 "Unavailable / Do Not Flash" ;
VAL_ 2566705918 SPNConversionMethod 0 "Convert SPN per Version 4" 1 "Convert SPN per Version 1, 2 or 3" ;
VAL_ 2566706686 Aft1DslExhstFldDsngUnit1HtrRely 0 "Off" 1 "On" 2 "Error" 3 "Not available" ;
VAL_ 2566706686 Aftrtrtmnt1DslExhstFldPmpPwrSupp 0 "Off" 1 "On" 2 "Error" 3 "Unavailable" ;
VAL_ 2566708478 AdaptiveCruiseCtrlReadinessStat 0 "Off" 1 "On" 2 "Error Condition" 3 "Not Available/Not Supported" ;
VAL_ 2566708478 CruiseControlSystemCommandState 0 "No Cruise Control System Command" 1 "Disabled by Cruise Control Disable Command" 2 "Disabled by Cruise Control Pause Command" 3 "Re-activated by Cruise Control Resume Command" 4 "Received a Cruise Control Resume Command" 5 "SAE Reserved" 7 "Not Supported" ;
VAL_ 2566708478 PredictCrsCtrlSetSpdOffstStatus 0 "Cruise Control Speed (SPN 7319) does not include Predictive Cruise Control Set Speed Offset (SPN 7316)" 1 "Cruise Control Speed (SPN 7319) includes Predictive Cruise Control Set Speed Offset (SPN 7316)" 2 "SAE Reserved" 3 "Not available" ;
VAL_ 2566708478 AEBSReadinessState 0 "Off" 1 "On" 2 "Condition exists" 3 "Not Available/Not Supported" ;
VAL_ 2566708478 CrsCtrlDriverCancellationStatus 0 "Driver action has not cancelled cruise control" 1 "Cruise control cancelled by driver action" 2 "Error" 3 "Not available" ;
VAL_ 2566708990 OprtrIndcOverrdRenewalRequired 0 "Not Required" 1 "Required" 2 "Error" 3 "Not Available" ;
VAL_ 2566710014 SupplementalFanEnableStatus 0 "Disabled" 1 "Enabled" 2 "Error" 3 "Not available/Not installed" ;
VAL_ 2566710014 SupplementalFanDirectionStatus 0 "Forward" 1 "Reverse" 2 "Error" 3 "Not available/Not installed" ;
VAL_ 2566710014 SupplementalFanVelocityStatus 0 "At Velocity" 1 "Velocity Error" 2 "Fan Spin Up" 3 "Fan Spin Down" 4 "Fan Stall" 5 "Reserved" 14 "Error" 15 "Not available" ;
VAL_ 2566710014 SupplementalFanCtrllerTempStat 0 "High Most severe" 1 "High Least severe" 2 "In Range" 3 "Low Least severe" 4 "Low Most severe" 5 "Not Defined" 6 "Error" 7 "Not available" ;
VAL_ 2566710014 SupplementalFanDriveStatus 0 "Normal" 1 "Alarm" 2 "Alarm High Severity" 3 "Derate Active" 4 "Controlled Shutdown Active" 5 "Uncontrolled Shutdown Active" 6 "Reserved for future assignment" 14 "Error" 15 "Not available" ;
VAL_ 2566711038 LubricationCycleModeLockStatus 0 "Not Locked" 1 "Locked" 2 "Error" 3 "Not available" ;
VAL_ 2566711038 LubricationCycleModeStatus 0 "Cycle mode # 1" 1 "Cycle mode # 2" 2 "Cycle mode # 3" 3 "Reserved" 6 "Error" 7 "Not available" ;
VAL_ 2566711038 LubricationOperationModeStatus 0 "Automatic Mode" 1 "Manual Service Mode" 2 "Test Mode # 1" 3 "Test Mode # 2" 4 "Test Mode # 3" 5 "Reserved" 6 "Error" 7 "Not Available" ;
VAL_ 2566711038 LubricationPumpEnableStatus 0 "Disabled" 1 "Enabled" 2 "Error" 3 "Not available" ;
VAL_ 2566711038 LubricationReservoirLevel 0 "Reservoir Not Low" 1 "Reservoir Low" 2 "Error" 3 "Not available or not installed" ;
VAL_ 2566711038 LubricationTimingCycleStatus 0 "Paused" 1 "Enabled" 2 "Error" 3 "Not available or not installed" ;
VAL_ 2566711550 IntkVlvActSysOilPrs1SolenoidCtrl 0 "off" 1 "on" 2 "reserved for SAE assignment" 3 "not available" ;
VAL_ 2566711550 IntkVlvActSysOilPrs2SolenoidCtrl 0 "off" 1 "on" 2 "reserved for SAE assignment" 3 "not available" ;
VAL_ 2566711806 Armrest1Switch1 0 "Off" 1 "On" 2 "Reserved" 3 "Don't care/take no action" ;
VAL_ 2566711806 Armrest1Switch2 0 "Off" 1 "On" 2 "Reserved" 3 "Don't care/take no action" ;
VAL_ 2566711806 Armrest2Switch1 0 "Off" 1 "On" 2 "Reserved" 3 "Don't care/take no action" ;
VAL_ 2566711806 Armrest2Switch2 0 "Off" 1 "On" 2 "Reserved" 3 "Don't care/take no action" ;
VAL_ 2566712318 Aftrtrtmnt2NOxAdsorberRegenStat 0 "Inactive" 1 "Active" 2 "Error indicator" 3 "Not available" ;
VAL_ 2566712318 Aft2NOxAdsorberDesulfationStat 0 "Inactive" 1 "Active" 2 "Error indicator" 3 "Not available" ;
VAL_ 2566712574 Aftrtrtmnt1NOxAdsorberRegenStat 0 "Inactive" 1 "Active" 2 "Error indicator" 3 "Not available" ;
VAL_ 2566712574 Aft1NOxAdsorberDesulfationStat 0 "Inactive" 1 "Active" 2 "Error indicator" 3 "Not available" ;
VAL_ 2566713598 FuelTankTransferPump 0 "Off" 1 "On" 2 "Error" 3 "Not available" ;
VAL_ 2566713854 EngTurboWastegateActr2TempStat 0 "High Most severe" 1 "High Least severe" 2 "In Range" 3 "Low Least severe" 4 "Low Most severe" 5 "Not Defined" 6 "Error" 7 "Not available" ;
VAL_ 2566713854 EngTurboWastegateActr1OpStat 0 "Normal" 1 "Alarm" 2 "Alarm High Severity" 3 "Derate Active" 4 "Controlled Shutdown Active" 5 "Uncontrolled Shutdown Active" 6 "Calibration in Progress" 7 "Reserved for future assignment" 14 "Error" ;
VAL_ 2566713854 EngTurboWastegateActr2OpStat 0 "Normal" 1 "Alarm" 2 "Alarm High Severity" 3 "Derate Active" 4 "Controlled Shutdown Active" 5 "Uncontrolled Shutdown Active" 6 "Reserved for future assignment" 14 "Error" ;
VAL_ 2566713854 EngExhstPressRgltrTempStat 0 "High Most severe" 1 "High Least severe" 2 "In Range" 3 "Low Least severe" 4 "Low Most severe" 5 "Not Defined" 6 "Error" 7 "Not available" ;
VAL_ 2566713854 EngExhstPressRgltrCtrlOpStatus 0 "Normal" 1 "Alarm" 2 "Alarm High Severity" 3 "Derate Active" 4 "Controlled Shutdown Active" 5 "Uncontrolled Shutdown Active" 6 "Reserved for future assignment" 14 "Error" 15 "Not available" ;
VAL_ 2566714110 EngThrottleValve1TemperatureStat 0 "High Most severe" 1 "High Least severe" 2 "In Range" 3 "Low Least severe" 4 "Low Most severe" 5 "Not Defined" 6 "Error" 7 "Not available" ;
VAL_ 2566714110 EngThrottleValve2TemperatureStat 0 "High Most severe" 1 "High Least severe" 2 "In Range" 3 "Low Least severe" 4 "Low Most severe" 5 "Not Defined" 6 "Error" 7 "Not available" ;
VAL_ 2566714110 EngFuelValve1TemperatureStatus 0 "High Most severe" 1 "High Least severe" 2 "In Range" 3 "Low Least severe" 4 "Low Most severe" 5 "Not Defined" 6 "Error" 7 "Not available" ;
VAL_ 2566714110 EngFuelValve2TemperatureStatus 0 "High Most severe" 1 "High Least severe" 2 "In Range" 3 "Low Least severe" 4 "Low Most severe" 5 "Not Defined" 6 "Error" 7 "Not available" ;
VAL_ 2566714110 EngThrottleValve1OperationStatus 0 "Normal" 1 "Alarm" 2 "Alarm High Severity" 3 "Derate Active" 4 "Controlled Shutdown Active" 5 "Uncontrolled Shutdown Active" 6 "Calibration in Progress" 7 "Reserved for future assignment" 14 "Error" 15 "Not available" ;
VAL_ 2566714110 EngThrottleValve2OperationStatus 0 "Normal" 1 "Alarm" 2 "Alarm High Severity" 3 "Derate Active" 4 "Controlled Shutdown Active" 5 "Uncontrolled Shutdown Active" 6 "Reserved for future assignment" 14 "Error" ;
VAL_ 2566714110 EngineFuelValve1OperationStatus 0 "Normal" 1 "Alarm" 2 "Alarm High Severity" 3 "Derate Active" 4 "Controlled Shutdown Active" 5 "Uncontrolled Shutdown Active" 6 "Test Mode Active" 7 "Reserved for future assignment" 14 "Error" ;
VAL_ 2566714110 EngineFuelValve2OperationStatus 0 "Normal" 1 "Alarm" 2 "Alarm High Severity" 3 "Derate Active" 4 "Controlled Shutdown Active" 5 "Uncontrolled Shutdown Active" 6 "Test Mode Active" 7 "Reserved for future assignment" 14 "Error" ;
VAL_ 2566714366 EngTurboCmprBypssActr2TempStat 0 "High Most severe" 1 "High Least severe" 2 "In Range" 3 "Low Least severe" 4 "Low Most severe" 5 "Not Defined" 6 "Error" 7 "Not available" ;
VAL_ 2566714366 EngTurboCmprssorBypssActr1OpStat 0 "Normal" 1 "Alarm" 2 "Alarm High Severity" 3 "Derate Active" 4 "Controlled Shutdown Active" 5 "Uncontrolled Shutdown Active" 6 "Reserved for future assignment" 14 "Error" ;
VAL_ 2566714366 EngTurboCmprssorBypssActr2OpStat 0 "Normal" 1 "Alarm" 2 "Alarm High Severity" 3 "Derate Active" 4 "Controlled Shutdown Active" 5 "Uncontrolled Shutdown Active" 6 "Reserved for future assignment" 14 "Error" ;
